VERSION ""

NS_ :

BS_:

BU_: VMCU TECU TACHO RECU_Virt IC3 HPCU EMS EBS DACU CIOM BBM ACM

BO_ 2566899694 PropTCO4_X_TACHO: 44 TACHO
 SG_ DailyRestingTimeShift1_ISig_3 : 144|15@1+ (1,0) [0|32767] "min"  IC3
 SG_ RestingPeriodFlagShift2_ISig_3 : 79|1@1+ (1,0) [0|0] ""  IC3
 SG_ DailyDrivingTimeShift4_ISig_3 : 96|15@1+ (1,0) [0|32767] "min"  IC3
 SG_ DailyDrivingPeriod_ISig_3 : 32|15@1+ (1,0) [0|32767] "min"  IC3
 SG_ DailyRestingTimeShift7_ISig_3 : 240|15@1+ (1,0) [0|32767] "min"  IC3
 SG_ UnknownPeriodShift1_ISig_3 : 159|1@1+ (1,0) [0|0] ""  IC3
 SG_ RestingPeriodFlagShift1_ISig_3 : 63|1@1+ (1,0) [0|0] ""  IC3
 SG_ DailyDrivingTimeShift3_ISig_3 : 80|15@1+ (1,0) [0|32767] "min"  IC3
 SG_ DailyRestingTimeShift2_ISig_3 : 160|15@1+ (1,0) [0|32767] "min"  IC3
 SG_ DailyRestingTimeShift3_ISig_3 : 176|15@1+ (1,0) [0|32767] "min"  IC3
 SG_ UnknownPeriodShift2_ISig_3 : 175|1@1+ (1,0) [0|0] ""  IC3
 SG_ RestingPeriodFlag_ISig_3 : 47|1@1+ (1,0) [0|0] ""  IC3
 SG_ TwoWeekTotalDrvingTime_ISig_3 : 0|16@1+ (1,0) [0|65535] "min"  IC3
 SG_ UnknownPeriodShift4_ISig_3 : 207|1@1+ (1,0) [0|0] ""  IC3
 SG_ DailyDrivingTimeShift2_ISig_3 : 64|15@1+ (1,0) [0|32767] "min"  IC3
 SG_ RestingPeriodFlagShift6_ISig_3 : 143|1@1+ (1,0) [0|0] ""  IC3
 SG_ DailyRestingTimeShift4_ISig_3 : 192|15@1+ (1,0) [0|32767] "min"  IC3
 SG_ RestingPeriodFlagShift5_ISig_3 : 127|1@1+ (1,0) [0|0] ""  IC3
 SG_ RestingPeriodFlagShift3_ISig_3 : 95|1@1+ (1,0) [0|0] ""  IC3
 SG_ DailyDrivingTimeShift5_ISig_3 : 112|15@1+ (1,0) [0|32767] "min"  IC3
 SG_ DailyRestingTimeShift6_ISig_3 : 224|15@1+ (1,0) [0|32767] "min"  IC3
 SG_ WeeklyTotalDrivingTime_ISig_3 : 16|16@1+ (1,0) [0|65535] "min"  IC3
 SG_ UnknownPeriodShift7_ISig_3 : 255|1@1+ (1,0) [0|0] ""  IC3
 SG_ UnknownPeriodShift6_ISig_3 : 239|1@1+ (1,0) [0|0] ""  IC3
 SG_ DailyRestingTimeShift5_ISig_3 : 208|15@1+ (1,0) [0|32767] "min"  IC3
 SG_ DailyDrivingTimeShift1_ISig_3 : 48|15@1+ (1,0) [0|32767] "min"  IC3
 SG_ UnknownPeriodShift3_ISig_3 : 191|1@1+ (1,0) [0|0] ""  IC3
 SG_ RestingPeriodFlagShift4_ISig_3 : 111|1@1+ (1,0) [0|0] ""  IC3
 SG_ DailyDrivingTimeShift6_ISig_3 : 128|15@1+ (1,0) [0|32767] "min"  IC3
 SG_ UnknownPeriodShift5_ISig_3 : 223|1@1+ (1,0) [0|0] ""  IC3

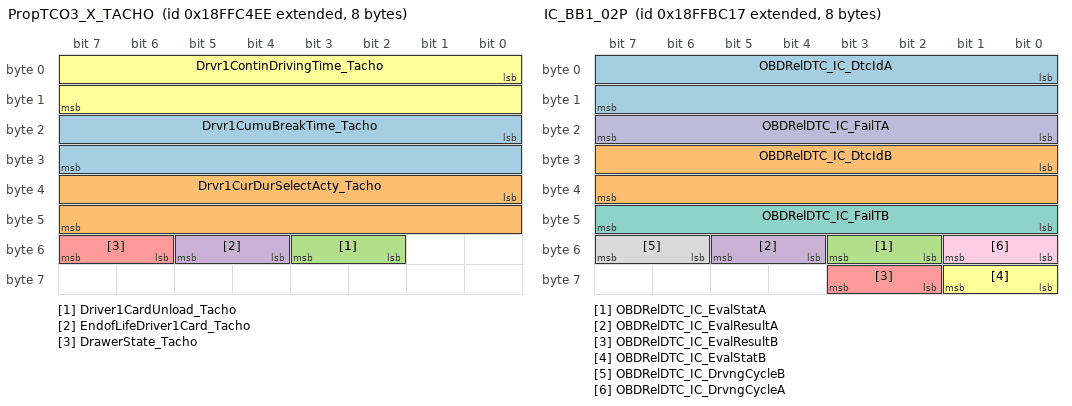
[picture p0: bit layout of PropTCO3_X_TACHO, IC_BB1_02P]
BO_ 2566898926 PropTCO3_X_TACHO: 8 TACHO
 SG_ Drvr1CumuBreakTime_Tacho : 16|16@1+ (1,0) [0|65535] "min"  VMCU
 SG_ Drvr1CurDurSelectActy_Tacho : 32|16@1+ (1,0) [0|65535] "min"  VMCU
 SG_ Driver1CardUnload_Tacho : 50|2@1+ (1,0) [0|0] ""  VMCU
 SG_ EndofLifeDriver1Card_Tacho : 52|2@1+ (1,0) [0|0] ""  VMCU
 SG_ DrawerState_Tacho : 54|2@1+ (1,0) [0|0] ""  VMCU
 SG_ Drvr1ContinDrivingTime_Tacho : 0|16@1+ (1,0) [0|65535] "min"  VMCU

BO_ 2566898670 PropTCO2_X_TACHO: 21 TACHO
 SG_ NextCalibrationDateDay : 136|8@1+ (0.25,0) [0|63.75] "Days"  VMCU
 SG_ WVehicleCharacteristicFactor : 152|16@1+ (0.001,0) [0|65.535] "NotApplicable"  VMCU
 SG_ NextCalibrationDateMonth : 128|8@1+ (1,0) [0|255] "Months"  VMCU
 SG_ Driver1Identification_ISig_3 : 0|112@1+ (1,0) [0|0] ""  IC3,CIOM
 SG_ NextCalibrationDateYear : 144|8@1+ (1,1985) [1985|2240] "Years"  VMCU

BO_ 2565804526 PropA_VMCU_TACHO: 8 TACHO
 SG_ DSRCtoOWSLink : 0|24@1+ (1,0) [0|0] ""  VMCU

BO_ 2565800709 PropA_TCU_GSSA: 8 Vector__XXX

BO_ 2565860881 PropA_TACHO_VMCU: 51 VMCU
 SG_ OWStoDSRCLink : 0|408@1+ (1,0) [0|0] ""  TACHO

BO_ 2565801219 PropA_GSSA_TCU: 8 Vector__XXX

BO_ 2671834641 PhysDiagRespMsg_F6_11_BB1: 8 ACM
 SG_ PhysDiagRespSig_F6_11_ISig_3 : 0|64@1+ (1,0) [0|0] ""  CIOM

BO_ 2671833838 PhysDiagRespMsg_F2_EE_BB1: 8 TACHO
 SG_ PhysDiagRespSig_F2_EE_ISig_3 : 0|64@1+ (1,0) [0|0] ""  VMCU

BO_ 2671833640 PhysDiagRespMsg_F2_28_BB1: 8 EBS
 SG_ PhysDiagRespSig_F2_28_ISig_3 : 0|64@1+ (1,0) [0|0] ""  VMCU

BO_ 2671833617 PhysDiagRespMsg_F2_11_BB1: 8 ACM
 SG_ PhysDiagRespSig_F2_11_ISig_3 : 0|64@1+ (1,0) [0|0] ""  VMCU

BO_ 2671833361 PhysDiagRespMsg_F1_11_BB1: 8 ACM
 SG_ PhysDiagRespSig_F1_11_ISig_3 : 0|64@1+ (1,0) [0|0] ""  VMCU

BO_ 2671832818 PhysDiagReqMsg_EE_F2_BB1: 8 VMCU
 SG_ PhysDiagReqSig_EE_F2_ISig_3 : 0|64@1+ (1,0) [0|0] ""  TACHO

BO_ 2671782130 PhysDiagReqMsg_28_F2_BB1: 8 VMCU
 SG_ PhysDiagReqSig_28_F2_ISig_3 : 0|64@1+ (1,0) [0|0] ""  EBS

BO_ 2671776246 PhysDiagReqMsg_11_F6_BB1: 8 CIOM
 SG_ PhysDiagReqSig_11_F6_ISig_3 : 0|64@1+ (1,0) [0|0] ""  ACM

BO_ 2671776242 PhysDiagReqMsg_11_F2_BB1: 8 VMCU
 SG_ PhysDiagReqSig_11_F2_ISig_3 : 0|64@1+ (1,0) [0|0] ""  ACM

BO_ 2671776241 PhysDiagReqMsg_11_F1_BB1: 8 VMCU
 SG_ PhysDiagReqSig_11_F1_ISig_3 : 0|64@1+ (1,0) [0|0] ""  ACM

BO_ 2566759457 PTODE_X_VMCU: 8 VMCU
 SG_ Pto2EnableSwitch : 4|2@1+ (1,0) [0|0] ""  TECU
 SG_ Pto1EnableSwitch : 6|2@1+ (1,0) [0|0] ""  TECU

BO_ 2566759427 PTODE_X_TECU: 8 TECU
 SG_ Pto2EngagementConsent : 20|2@1+ (1,0) [0|0] ""  VMCU
 SG_ Pto1EngagementConsent : 22|2@1+ (1,0) [0|0] ""  VMCU

BO_ 2671850481 OBDFuncDiagMsg_BB1: 8 VMCU
 SG_ FuncDiagDataOBD_ISig_3 : 0|64@1+ (1,0) [0|0] ""  ACM

BO_ 2671850486 OBDFuncDiagMsgF6_BB1: 8 CIOM
 SG_ FuncDiagDataOBDF6_ISig_3 : 0|64@1+ (1,0) [0|0] ""  ACM

BO_ 2566844928 LFE_X_EMS: 8 EMS
 SG_ InstantaneousFuelEconomy_ISig_3 : 16|16@1+ (0.001953125,0) [0|127.998046875] "km_per_l"  CIOM,IC3
 SG_ EngineFuelRate_ISig_3 : 0|16@1+ (0.05,0) [0|3276.75] "l_per_h"  BBM,VMCU,IC3,CIOM

BO_ 2566799590 LD_X_BBM_BB1: 8 BBM
 SG_ RearFogLights_ISig_3 : 32|2@1+ (1,0) [0|0] ""  DACU
 SG_ LowBeamHeadLightData_ISig_3 : 4|2@1+ (1,0) [0|0] ""  DACU

BO_ 2564428270 KWP2000Resp_VMCU_TACHO: 8 TACHO
 SG_ KWP2000Response_TACHO : 0|64@1+ (1,0) [0|0] ""  VMCU

BO_ 2564484625 KWP2000Req_TACHO_VMCU: 8 VMCU
 SG_ KWP2000Request_TACHO : 0|64@1+ (1,0) [0|0] ""  TACHO

BO_ 2633861635 J2012_X_TCU: 8 Vector__XXX

BO_ 2671902708 IntTesterTGW2FuncDiagMsg_BB1: 8 IC3
 SG_ FuncDiagDataIntTesterTGW2_ISig_3 : 0|64@1+ (1,0) [0|0] ""  TACHO,EBS,ACM

BO_ 2566825472 IMT1_X_EMS: 8 EMS
 SG_ EngineTurbo1BoostPressure : 0|16@1+ (0.125,0) [0|8191.875] "kPa"  IC3,ACM

BO_ 2566896663 IC_BB1_02P: 8 IC3
 SG_ OBDRelDTC_IC_DtcIdA : 0|16@1+ (1,0) [0|65535] ""  VMCU
 SG_ OBDRelDTC_IC_DtcIdB : 24|16@1+ (1,0) [0|65535] ""  VMCU
 SG_ OBDRelDTC_IC_EvalStatA : 50|2@1+ (1,0) [0|0] ""  VMCU
 SG_ OBDRelDTC_IC_EvalResultA : 52|2@1+ (1,0) [0|0] ""  VMCU
 SG_ OBDRelDTC_IC_EvalResultB : 58|2@1+ (1,0) [0|0] ""  VMCU
 SG_ OBDRelDTC_IC_EvalStatB : 56|2@1+ (1,0) [0|0] ""  VMCU
 SG_ OBDRelDTC_IC_FailTB : 40|8@1+ (1,0) [0|255] ""  VMCU
 SG_ OBDRelDTC_IC_DrvngCycleB : 54|2@1+ (1,0) [0|0] ""  VMCU
 SG_ OBDRelDTC_IC_DrvngCycleA : 48|2@1+ (1,0) [0|0] ""  VMCU
 SG_ OBDRelDTC_IC_FailTA : 16|8@1+ (1,0) [0|255] ""  VMCU

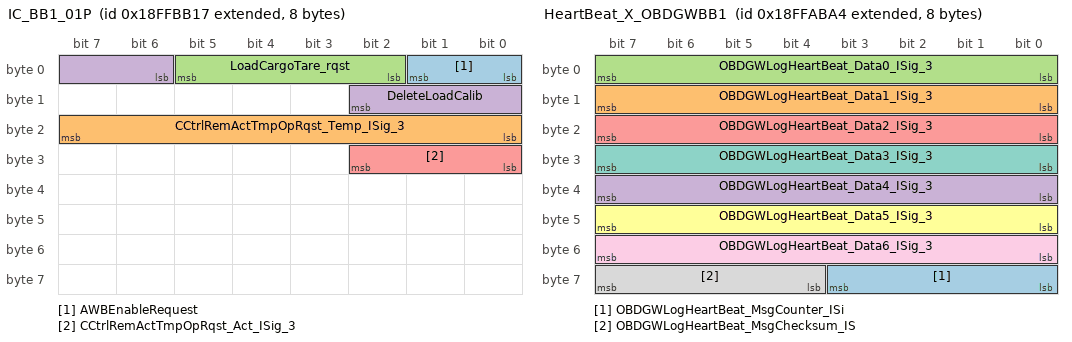
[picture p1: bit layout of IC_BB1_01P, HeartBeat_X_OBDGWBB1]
BO_ 2566896407 IC_BB1_01P: 8 IC3
 SG_ AWBEnableRequest : 0|2@1+ (1,0) [0|0] ""  TECU,EMS
 SG_ CCtrlRemActTmpOpRqst_Temp_ISig_3 : 16|8@1+ (0.5,0) [0|127.5] "DegreeC"  CIOM
 SG_ LoadCargoTare_rqst : 2|4@1+ (1,0) [0|0] ""  VMCU
 SG_ DeleteLoadCalib : 6|5@1+ (1,0) [0|0] ""  VMCU
 SG_ CCtrlRemActTmpOpRqst_Act_ISig_3 : 24|3@1+ (1,0) [0|0] ""  CIOM

BO_ 2566892452 HeartBeat_X_OBDGWBB1: 8 CIOM
 SG_ OBDGWLogHeartBeat_MsgCounter_ISi : 56|4@1+ (1,0) [0|15] "Count"  EMS
 SG_ OBDGWLogHeartBeat_Data1_ISig_3 : 8|8@1+ (1,0) [0|255] ""  EMS
 SG_ OBDGWLogHeartBeat_Data0_ISig_3 : 0|8@1+ (1,0) [0|255] ""  EMS
 SG_ OBDGWLogHeartBeat_Data4_ISig_3 : 32|8@1+ (1,0) [0|255] ""  EMS
 SG_ OBDGWLogHeartBeat_Data2_ISig_3 : 16|8@1+ (1,0) [0|255] ""  EMS
 SG_ OBDGWLogHeartBeat_Data5_ISig_3 : 40|8@1+ (1,0) [0|255] ""  EMS
 SG_ OBDGWLogHeartBeat_Data3_ISig_3 : 24|8@1+ (1,0) [0|255] ""  EMS
 SG_ OBDGWLogHeartBeat_MsgChecksum_IS : 60|4@1+ (1,0) [0|15] ""  EMS
 SG_ OBDGWLogHeartBeat_Data6_ISig_3 : 48|8@1+ (1,0) [0|255] ""  EMS

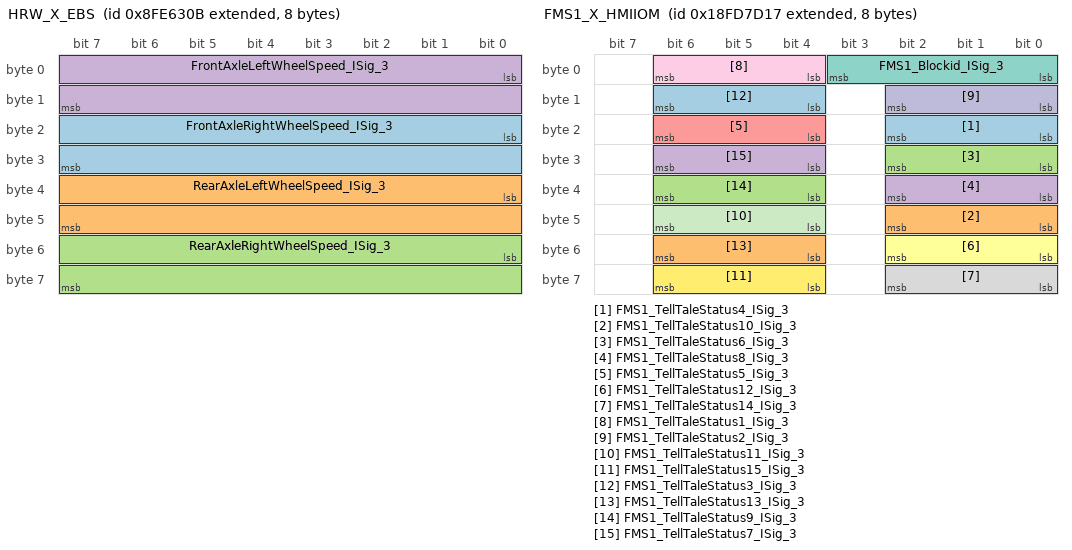
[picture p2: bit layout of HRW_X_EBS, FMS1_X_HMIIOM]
BO_ 2298372875 HRW_X_EBS: 8 EBS
 SG_ FrontAxleRightWheelSpeed_ISig_3 : 16|16@1+ (0.00390625,0) [0|255.99609375] "Km_per_h"  VMCU,BBM,DACU,TECU,IC3
 SG_ RearAxleLeftWheelSpeed_ISig_3 : 32|16@1+ (0.00390625,0) [0|255.99609375] "Km_per_h"  BBM,VMCU,TECU,DACU,IC3
 SG_ RearAxleRightWheelSpeed_ISig_3 : 48|16@1+ (0.00390625,0) [0|255.99609375] "Km_per_h"  BBM,VMCU,TECU,DACU,IC3
 SG_ FrontAxleLeftWheelSpeed_ISig_3 : 0|16@1+ (0.00390625,0) [0|255.99609375] "Km_per_h"  TECU,IC3,DACU,BBM,VMCU

BO_ 2566719744 HRLFC_X_EMS: 8 EMS
 SG_ HighResEngineTotalFuelUsed_ISig_ : 32|32@1+ (0.001,0) [0|4294967.295] "l"  IC3,BBM,CIOM

BO_ 2566841600 HOURS_X_EMS: 8 EMS
 SG_ EngineRevolutions_ISig_3 : 32|32@1+ (1000,0) [0|4294967295000] "r"  IC3

BO_ 2566749463 FMS1_X_HMIIOM: 8 IC3
 SG_ FMS1_TellTaleStatus4_ISig_3 : 16|3@1+ (1,0) [0|0] ""  CIOM
 SG_ FMS1_TellTaleStatus10_ISig_3 : 40|3@1+ (1,0) [0|0] ""  CIOM
 SG_ FMS1_TellTaleStatus6_ISig_3 : 24|3@1+ (1,0) [0|0] ""  CIOM
 SG_ FMS1_TellTaleStatus8_ISig_3 : 32|3@1+ (1,0) [0|0] ""  CIOM
 SG_ FMS1_TellTaleStatus5_ISig_3 : 20|3@1+ (1,0) [0|0] ""  CIOM
 SG_ FMS1_TellTaleStatus12_ISig_3 : 48|3@1+ (1,0) [0|0] ""  CIOM
 SG_ FMS1_Blockid_ISig_3 : 0|4@1+ (1,0) [0|15] ""  CIOM
 SG_ FMS1_TellTaleStatus14_ISig_3 : 56|3@1+ (1,0) [0|0] ""  CIOM
 SG_ FMS1_TellTaleStatus1_ISig_3 : 4|3@1+ (1,0) [0|0] ""  CIOM
 SG_ FMS1_TellTaleStatus2_ISig_3 : 8|3@1+ (1,0) [0|0] ""  CIOM
 SG_ FMS1_TellTaleStatus11_ISig_3 : 44|3@1+ (1,0) [0|0] ""  CIOM
 SG_ FMS1_TellTaleStatus15_ISig_3 : 60|3@1+ (1,0) [0|0] ""  CIOM
 SG_ FMS1_TellTaleStatus3_ISig_3 : 12|3@1+ (1,0) [0|0] ""  CIOM
 SG_ FMS1_TellTaleStatus13_ISig_3 : 52|3@1+ (1,0) [0|0] ""  CIOM
 SG_ FMS1_TellTaleStatus9_ISig_3 : 36|3@1+ (1,0) [0|0] ""  CIOM
 SG_ FMS1_TellTaleStatus7_ISig_3 : 28|3@1+ (1,0) [0|0] ""  CIOM

BO_ 2364541955 ETC8_X_TCU: 8 Vector__XXX

BO_ 2566801923 ETC7_X_TECU: 8 TECU
 SG_ TransmEngineCrankEnable2_ISig_3 : 12|2@1+ (1,0) [0|0] ""  VMCU

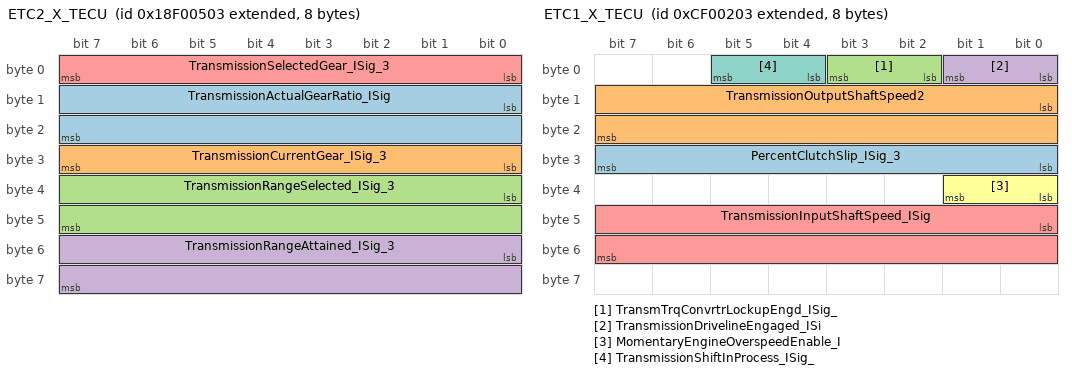
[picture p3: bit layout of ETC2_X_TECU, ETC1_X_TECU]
BO_ 2565866755 ETC2_X_TECU: 8 TECU
 SG_ TransmissionActualGearRatio_ISig : 8|16@1+ (0.001,0) [0|65.535] "NotApplicable"  BBM,DACU,EMS,VMCU
 SG_ TransmissionCurrentGear_ISig_3 : 24|8@1+ (1,-125) [-125|130] "GearValue"  EMS,BBM,VMCU,EBS,IC3,DACU
 SG_ TransmissionRangeSelected_ISig_3 : 32|16@1+ (1,0) [0|0] ""  VMCU,IC3,BBM
 SG_ TransmissionRangeAttained_ISig_3 : 48|16@1+ (1,0) [0|0] ""  BBM,IC3
 SG_ TransmissionSelectedGear_ISig_3 : 0|8@1+ (1,-125) [-125|130] "GearValue"  EMS,BBM,IC3,VMCU

BO_ 2364539395 ETC1_X_TECU: 8 TECU
 SG_ PercentClutchSlip_ISig_3 : 24|8@1+ (0.4,0) [0|102] "Percent"  EBS,EMS,VMCU,BBM
 SG_ TransmissionOutputShaftSpeed2 : 8|16@1+ (0.125,0) [0|8191.875] "rpm"  VMCU
 SG_ TransmTrqConvrtrLockupEngd_ISig_ : 2|2@1+ (1,0) [0|0] ""  VMCU,EMS,BBM
 SG_ TransmissionDrivelineEngaged_ISi : 0|2@1+ (1,0) [0|0] ""  EMS,VMCU,BBM,DACU,EBS
 SG_ TransmissionInputShaftSpeed_ISig : 40|16@1+ (0.125,0) [0|8191.875] "rpm"  BBM,EBS
 SG_ MomentaryEngineOverspeedEnable_I : 32|2@1+ (1,0) [0|0] ""  BBM,EMS
 SG_ TransmissionShiftInProcess_ISig_ : 4|2@1+ (1,0) [0|0] ""  EMS,VMCU,EBS,BBM,DACU

BO_ 2566843904 ET1_X_EMS: 8 EMS
 SG_ EngineOilTemperature_ISig_3 : 16|16@1+ (0.03125,-273) [-273|1774.96875] "DegreeC"  IC3,BBM,TECU
 SG_ EngineCoolantTemp_stat_ISig_3 : 0|8@1+ (1,-40) [-40|215] "DegreeC"  CIOM,IC3,VMCU,TECU,ACM,BBM

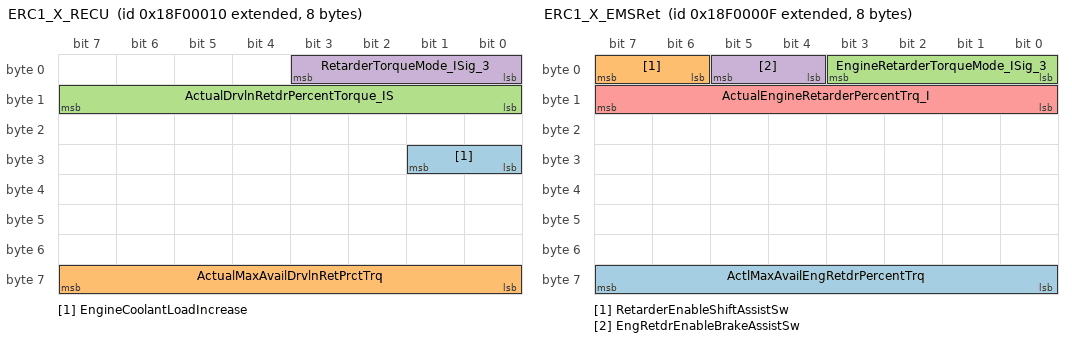
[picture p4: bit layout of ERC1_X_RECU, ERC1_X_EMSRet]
BO_ 2565865488 ERC1_X_RECU: 8 RECU_Virt
 SG_ EngineCoolantLoadIncrease : 24|2@1+ (1,0) [0|0] ""  EMS
 SG_ ActualMaxAvailDrvlnRetPrctTrq : 56|8@1+ (1,-125) [-125|130] "Percent"  EMS,EBS,VMCU,TECU
 SG_ ActualDrvlnRetdrPercentTorque_IS : 8|8@1+ (1,-125) [-125|130] "Percent"  EMS,CIOM,VMCU,TECU,EBS,IC3
 SG_ RetarderTorqueMode_ISig_3 : 0|4@1+ (1,0) [0|0] ""  CIOM,IC3,EMS

BO_ 2565865487 ERC1_X_EMSRet: 8 EMS
 SG_ ActlMaxAvailEngRetdrPercentTrq : 56|8@1+ (1,-125) [-125|130] "Percent"  VMCU,EBS
 SG_ RetarderEnableShiftAssistSw : 6|2@1+ (1,0) [0|0] ""  TECU
 SG_ EngineRetarderTorqueMode_ISig_3 : 0|4@1+ (1,0) [0|0] ""  CIOM,IC3
 SG_ EngRetdrEnableBrakeAssistSw : 4|2@1+ (1,0) [0|0] ""  TECU
 SG_ ActualEngineRetarderPercentTrq_I : 8|8@1+ (1,-125) [-125|130] "Percent"  RECU_Virt,CIOM,EBS,IC3,VMCU,TECU

BO_ 2364541440 EGF1_X_EMS: 8 EMS
 SG_ EngineIntakeAirRate : 16|16@1+ (0.05,0) [0|3276.75] "Kg_per_h"  CIOM

BO_ 2566844160 EFLP1_X_EMS: 8 EMS
 SG_ EngineOilLevel_ISig_3 : 16|8@1+ (0.4,0) [0|102] "Percent"  BBM,IC3
 SG_ EngineOilPressure_ISig_3 : 24|8@1+ (4,0) [0|1020] "kPa"  VMCU,IC3,BBM

BO_ 2566840064 EEC3_X_EMS: 8 EMS
 SG_ NominalFrictionPercentTorque_ISi : 0|8@1+ (1,-125) [-125|130] "Percent"  VMCU,TECU,DACU,CIOM,EBS,RECU_Virt

BO_ 2364539665 EEC2_X_VMCU: 8 VMCU
 SG_ AcceleratorPedalPositionVendor : 8|8@1+ (0.4,0) [0|102] "Percent"  TECU

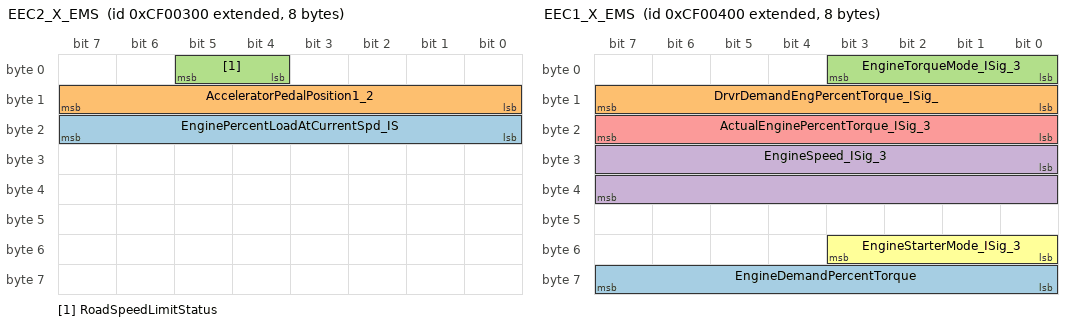
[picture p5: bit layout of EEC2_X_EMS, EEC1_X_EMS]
BO_ 2364539648 EEC2_X_EMS: 8 EMS
 SG_ EnginePercentLoadAtCurrentSpd_IS : 16|8@1+ (1,0) [0|255] "Percent"  ACM,IC3,BBM,CIOM,VMCU,TECU
 SG_ AcceleratorPedalPosition1_2 : 8|8@1+ (0.4,0) [0|102] "Percent"  TECU
 SG_ RoadSpeedLimitStatus : 4|2@1+ (1,0) [0|0] ""  TECU

BO_ 2364539904 EEC1_X_EMS: 8 EMS
 SG_ EngineDemandPercentTorque : 56|8@1+ (1,-125) [-125|130] "Percent"  TECU,CIOM
 SG_ DrvrDemandEngPercentTorque_ISig_ : 8|8@1+ (1,-125) [-125|130] "Percent"  BBM,TECU,EBS,VMCU
 SG_ EngineTorqueMode_ISig_3 : 0|4@1+ (1,0) [0|0] ""  TECU,VMCU,BBM,EBS,IC3
 SG_ EngineSpeed_ISig_3 : 24|16@1+ (0.125,0) [0|8191.875] "rpm"  BBM,DACU,IC3,VMCU,EBS,ACM,TECU,CIOM
 SG_ ActualEnginePercentTorque_ISig_3 : 16|8@1+ (1,-125) [-125|130] "Percent"  IC3,VMCU,EBS,CIOM,TECU,BBM,DACU
 SG_ EngineStarterMode_ISig_3 : 48|4@1+ (1,0) [0|0] ""  VMCU,BBM,IC3

BO_ 2566841088 EC1_X_EMS: 39 EMS
 SG_ EngConf_EngSpeedAtHighIdle_P6 : 120|16@1+ (0.125,0) [0|8191.875] "rpm"  TECU
 SG_ EngConf_EngTorqueAt_P4 : 88|8@1+ (1,-125) [-125|130] "Percent"  TECU
 SG_ EngConf_EngMaxMomOvSpeed_P7 : 168|16@1+ (0.125,0) [0|8191.875] "rpm"  TECU
 SG_ EngConf_EngTorqueAt_P5 : 112|8@1+ (1,-125) [-125|130] "Percent"  TECU
 SG_ EngConf_EngSpeedAtIdle_P1 : 0|16@1+ (0.125,0) [0|8191.875] "rpm"  TECU
 SG_ EngineReferenceTorque_ISig_3 : 152|16@1+ (1,0) [0|65535] "Nm"  TECU,CIOM,RECU_Virt,DACU,EBS,VMCU
 SG_ EngConf_EngSpeedAt_P2 : 24|16@1+ (0.125,0) [0|8191.875] "rpm"  TECU
 SG_ EngConf_MaxMomOverrideTimeLim : 184|8@1+ (0.1,0) [0|25.5] "s"  TECU
 SG_ EngConf_EngSpeedAt_P5 : 96|16@1+ (0.125,0) [0|8191.875] "rpm"  TECU
 SG_ EngConf_EngTorqueAtIdle_P1 : 16|8@1+ (1,-125) [-125|130] "Percent"  TECU
 SG_ EngConf_EngSpeedAt_P4 : 72|16@1+ (0.125,0) [0|8191.875] "rpm"  TECU
 SG_ EngConf_EngSpeedAt_P3 : 48|16@1+ (0.125,0) [0|8191.875] "rpm"  TECU
 SG_ EngConf_EngTorqueAt_P3 : 64|8@1+ (1,-125) [-125|130] "Percent"  TECU
 SG_ EngConf_EngTorqueAt_P2 : 40|8@1+ (1,-125) [-125|130] "Percent"  TECU

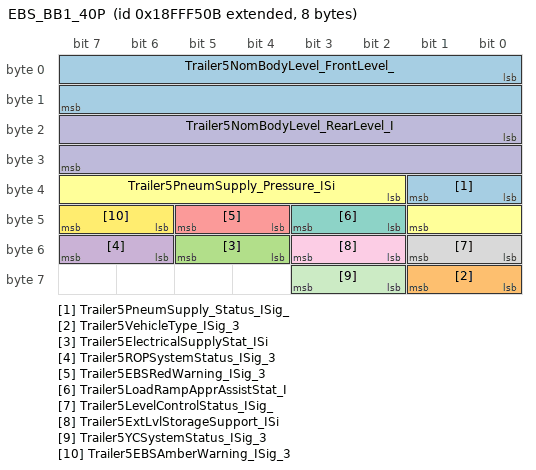
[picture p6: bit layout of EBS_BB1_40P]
BO_ 2566911243 EBS_BB1_40P: 8 EBS
 SG_ Trailer5PneumSupply_Status_ISig_ : 32|2@1+ (1,0) [0|0] ""  IC3
 SG_ Trailer5VehicleType_ISig_3 : 56|2@1+ (1,0) [0|0] ""  IC3
 SG_ Trailer5ElectricalSupplyStat_ISi : 52|2@1+ (1,0) [0|0] ""  IC3
 SG_ Trailer5ROPSystemStatus_ISig_3 : 54|2@1+ (1,0) [0|0] ""  IC3
 SG_ Trailer5EBSRedWarning_ISig_3 : 44|2@1+ (1,0) [0|0] ""  IC3
 SG_ Trailer5PneumSupply_Pressure_ISi : 34|8@1+ (5,0) [0|1275] "kPa"  IC3
 SG_ Trailer5LoadRampApprAssistStat_I : 42|2@1+ (1,0) [0|0] ""  IC3
 SG_ Trailer5LevelControlStatus_ISig_ : 48|2@1+ (1,0) [0|0] ""  IC3
 SG_ Trailer5ExtLvlStorageSupport_ISi : 50|2@1+ (1,0) [0|0] ""  IC3
 SG_ Trailer5NomBodyLevel_RearLevel_I : 16|16@1+ (1,0) [0|65535] "mm"  IC3
 SG_ Trailer5YCSystemStatus_ISig_3 : 58|2@1+ (1,0) [0|0] ""  IC3
 SG_ Trailer5EBSAmberWarning_ISig_3 : 46|2@1+ (1,0) [0|0] ""  IC3
 SG_ Trailer5NomBodyLevel_FrontLevel_ : 0|16@1+ (1,0) [0|65535] "mm"  IC3

CM_ BO_ 2566899694 "Proprietary TACHO message 4";
CM_ SG_ 2566899694 TwoWeekTotalDrvingTime_ISig_3 "65024 - 65279 Error ; 65280 - 65535 Not available";
CM_ SG_ 2566899694 WeeklyTotalDrivingTime_ISig_3 "65024 - 65279 Error ; 65280 - 65535 Not available";
CM_ BO_ 2566898926 "Proprietary TACHO message 3";
CM_ SG_ 2566898926 Drvr1CumuBreakTime_Tacho "65024 - 65279 Error ; 65280 - 65535 Not available";
CM_ SG_ 2566898926 Drvr1CurDurSelectActy_Tacho "65024 - 65279 Error ; 65280 - 65535 Not available";
CM_ SG_ 2566898926 Drvr1ContinDrivingTime_Tacho "65024 - 65279 Error ; 65280 - 65535 Not available";
CM_ BO_ 2566898670 "Proprietary TACHO message 2";
CM_ SG_ 2566898670 NextCalibrationDateDay "254 Error ; 255 Not available";
CM_ SG_ 2566898670 NextCalibrationDateMonth "254 Error ; 255 Not available";
CM_ SG_ 2566898670 NextCalibrationDateYear "254 Error ; 255 Not available";
CM_ BO_ 2565800709 "PGN61184 Proprietary A data sent by Transmission ECU to Gearshift selector";
CM_ BO_ 2565801219 "PGN61184 Proprietary A data sent by Gearshift selector to Transmission ECU";
CM_ BO_ 2566759457 "PGN 64932 PTO Drive Engagement";
CM_ BO_ 2566759427 "PGN 64932 PTO Drive Engagement
";
CM_ BO_ 2566844928 "PGN 65266 Fuel Economy (Liquid)";
CM_ SG_ 2566844928 InstantaneousFuelEconomy_ISig_3 "64256 - 65023 Spare
65024 - 65279 Error
65280 - 65535 NotAvailable";
CM_ SG_ 2566844928 EngineFuelRate_ISig_3 "65024 - 65279 Error ; 65280 - 65535 Not available";
CM_ BO_ 2633861635 "PGN 64906 SAE J2012 DTC Display";
CM_ BO_ 2566825472 "PGN 65190 Intake Manifold Information 1";
CM_ SG_ 2566825472 EngineTurbo1BoostPressure "65024 - 65279 Error ; 65280 - 65535 Not Available";
CM_ BO_ 2566892452 "Defined as sporadic on BB1, but is in reality sent cyclic 30 seconds when OBDGW is present and send msg cyclic on DiagLink.";
CM_ BO_ 2298372875 "PGN 65134 High Resolution Wheel Speed";
CM_ SG_ 2298372875 FrontAxleRightWheelSpeed_ISig_3 "65024 - 65279 Error ; 65280 - 65535 Not available";
CM_ SG_ 2298372875 RearAxleLeftWheelSpeed_ISig_3 "65024 - 65279 Error ; 65280 - 65535 Not available";
CM_ SG_ 2298372875 RearAxleRightWheelSpeed_ISig_3 "65024 - 65279 Error ; 65280 - 65535 Not available";
CM_ SG_ 2298372875 FrontAxleLeftWheelSpeed_ISig_3 "65024 - 65279 Error ; 65280 - 65535 Not available";
CM_ BO_ 2566719744 "PGN 64777 High Resolution Fuel Consumption (Liquid)";
CM_ SG_ 2566719744 HighResEngineTotalFuelUsed_ISig_ "4211081216 - 4261412863 Spare
4261412864 - 4278190079 Error
4278190080 - 4294967295 NotAvailable";
CM_ BO_ 2566841600 "PGN 65253 Engine Hours, Revolutions";
CM_ SG_ 2566841600 EngineRevolutions_ISig_3 "4261412864 - 4278190079 Error ; 4278190080 - 4294967295 Not available";
CM_ BO_ 2566749463 "PGN 64893 FMS Telltale status";
CM_ SG_ 2566749463 FMS1_Blockid_ISig_3 "15: Don't care";
CM_ BO_ 2364541955 "PGN61452 Electronic Transmission Controller #8";
CM_ BO_ 2566801923 "PGN 65098 Electronic Transmission Controller 7";
CM_ BO_ 2565866755 "PGN 61445 Electronic Transmission Controller 2";
CM_ SG_ 2565866755 TransmissionActualGearRatio_ISig "65024 - 65279 Error ; 65280 - 65535 Not available";
CM_ SG_ 2565866755 TransmissionCurrentGear_ISig_3 "254 Error ; 255 Not available";
CM_ SG_ 2565866755 TransmissionSelectedGear_ISig_3 "254 Error ; 255 Not available";
CM_ BO_ 2364539395 "PGN 61442 Electronic Transmission Controller 1";
CM_ SG_ 2364539395 PercentClutchSlip_ISig_3 "254 Error ; 255 Not available";
CM_ SG_ 2364539395 TransmissionInputShaftSpeed_ISig "65024 - 65279 Error ; 65280 - 65535 Not available";
CM_ BO_ 2566843904 "PGN 65262 Engine Temperature 1";
CM_ SG_ 2566843904 EngineOilTemperature_ISig_3 "65024 - 65279 Error ; 65280 - 65535 Not available";
CM_ SG_ 2566843904 EngineCoolantTemp_stat_ISig_3 "254 Error ; 255 Not available";
CM_ BO_ 2565865488 "PGN 61440 Electronic Retarder Controller 1 from RECU";
CM_ SG_ 2565865488 ActualMaxAvailDrvlnRetPrctTrq "254 Error ; 255 Not available";
CM_ SG_ 2565865488 ActualDrvlnRetdrPercentTorque_IS "254 Error ; 255 Not available";
CM_ BO_ 2565865487 "PGN 61440 Electronic Retarder Controller 1";
CM_ SG_ 2565865487 ActlMaxAvailEngRetdrPercentTrq "254 Error ; 255 Not available";
CM_ SG_ 2565865487 ActualEngineRetarderPercentTrq_I "254 Error ; 255 Not available";
CM_ BO_ 2364541440 "PGN 61450 Flow rates of Air and mixed gasses into the engine cylinders.
Note: SAE recommended rate 50ms, but 500ms set due to current usage only for logging.";
CM_ BO_ 2566844160 "PGN 65263 Engine Fluid Level/Pressure 1";
CM_ SG_ 2566844160 EngineOilLevel_ISig_3 "254 Error ; 255 Not available";
CM_ SG_ 2566844160 EngineOilPressure_ISig_3 "254 Error ; 255 Not available";
CM_ BO_ 2566840064 "PGN 65247 Electronic Engine Controller 3";
CM_ SG_ 2566840064 NominalFrictionPercentTorque_ISi "254 Error ; 255 Not available";
CM_ BO_ 2364539665 "PGN 61443 Electronic Engine Controller 2";
CM_ BO_ 2364539648 "PGN 61443 Electronic Engine Controller 2";
CM_ SG_ 2364539648 EnginePercentLoadAtCurrentSpd_IS "254 Error ; 255 Not available";
CM_ BO_ 2364539904 "PGN 61444 Electronic Engine Controller 1";
CM_ SG_ 2364539904 DrvrDemandEngPercentTorque_ISig_ "254 Error ; 255 Not available";
CM_ SG_ 2364539904 EngineSpeed_ISig_3 "65024 - 65279 Error ; 65280 - 65535 Not available";
CM_ SG_ 2364539904 ActualEnginePercentTorque_ISig_3 "254 Error ; 255 Not available";
CM_ BO_ 2566841088 "PGN 65251 Engine Configuration 1";
CM_ SG_ 2566841088 EngConf_EngSpeedAtHighIdle_P6 "65024 - 65279 Error ; 65280 - 65535 Not available";
CM_ SG_ 2566841088 EngConf_EngTorqueAt_P4 "254 Error ; 255 Not available";
CM_ SG_ 2566841088 EngConf_EngMaxMomOvSpeed_P7 "65024 - 65279 Error ; 65280 - 65535 Not available";
CM_ SG_ 2566841088 EngConf_EngTorqueAt_P5 "254 Error ; 255 Not available";
CM_ SG_ 2566841088 EngConf_EngSpeedAtIdle_P1 "65024 - 65279 Error ; 65280 - 65535 Not available";
CM_ SG_ 2566841088 EngineReferenceTorque_ISig_3 "65024 - 65279 Error ; 65280 - 65535 Not available";
CM_ SG_ 2566841088 EngConf_EngSpeedAt_P2 "65024 - 65279 Error ; 65280 - 65535 Not available";
CM_ SG_ 2566841088 EngConf_MaxMomOverrideTimeLim "254 Error ; 255 Not available";
CM_ SG_ 2566841088 EngConf_EngSpeedAt_P5 "65024 - 65279 Error ; 65280 - 65535 Not available";
CM_ SG_ 2566841088 EngConf_EngTorqueAtIdle_P1 "254 Error ; 255 Not available";
CM_ SG_ 2566841088 EngConf_EngSpeedAt_P4 "65024 - 65279 Error ; 65280 - 65535 Not available";
CM_ SG_ 2566841088 EngConf_EngSpeedAt_P3 "65024 - 65279 Error ; 65280 - 65535 Not available";
CM_ SG_ 2566841088 EngConf_EngTorqueAt_P3 "254 Error ; 255 Not available";
CM_ SG_ 2566841088 EngConf_EngTorqueAt_P2 "254 Error ; 255 Not available";
CM_ SG_ 2566911243 Trailer5PneumSupply_Pressure_ISi "254 Error ; 255 Not available";
BA_DEF_ BO_  "GenMsgStartDelayTime" INT 0 0;
BA_DEF_ BO_  "GenMsgDelayTime" INT 0 0;
BA_DEF_ BO_  "GenMsgNrOfRepetition" INT 0 0;
BA_DEF_ BO_  "GenMsgCycleTimeFast" INT 0 0;
BA_DEF_ BO_  "GenMsgCycleTime" INT 0 0;
BA_DEF_ BO_  "GenMsgSendType" ENUM  "Cyclic","NotUsed","NotUsed","NotUsed","NotUsed","NotUsed","NotUsed","IfActive","NoMsgSendType","NotUsed";
BA_DEF_ SG_  "GenSigStartValue" INT 0 0;
BA_DEF_ SG_  "GenSigCycleTimeActive" INT 0 0;
BA_DEF_ SG_  "GenSigCycleTime" INT 0 0;
BA_DEF_ SG_  "GenSigSendType" ENUM  "Cyclic","OnWrite","OnWriteWithRepetition","OnChange","OnChangeWithRepetition","IfActive","IfActiveWithRepetition","NoSigSendType","NotUsed","NotUsed","NotUsed","NotUsed","NotUsed";
BA_DEF_ BO_  "VFrameFormat" ENUM  "StandardCAN","ExtendedCAN","reserved","J1939PG","reserved","reserved","reserved","reserved","reserved","reserved","reserved","reserved","reserved","reserved","StandardCAN_FD","ExtendedCAN_FD";
BA_DEF_ BO_  "TpJ1939VarDlc" ENUM  "No","Yes";
BA_DEF_ SG_  "SigType" ENUM  "Default","Range","RangeSigned","ASCII","Discrete","Control","ReferencePGN","DTC","StringDelimiter","StringLength","StringLengthControl";
BA_DEF_ SG_  "SeToolVersion_SIGNAL" STRING ;
BA_DEF_ SG_  "SeToolUniqueID_SIGNAL" STRING ;
BA_DEF_ SG_  "SeToolOwnerSigGroup_SIGNAL" STRING ;
BA_DEF_ SG_  "SeToolOwnerSigGroupID_SIGNAL" STRING ;
BA_DEF_ SG_  "SeToolName_SIGNAL" STRING ;
BA_DEF_ SG_  "SeToolItemID_SIGNAL" STRING ;
BA_DEF_ SG_  "SeToolAncestorID_SIGNAL" STRING ;
BA_DEF_ SG_  "SPN" INT 0 524287;
BA_DEF_ SG_  "Platform_VMCU1_Sig" ENUM  "No","Yes";
BA_DEF_ SG_  "Platform_FactoryIf_Sig" ENUM  "No","Yes";
BA_DEF_ SG_  "NeedsUpdateBit" ENUM  "No","Yes";
BA_DEF_ SG_  "GenSigMaxLatency" INT 0 65535;
BA_DEF_ SG_  "GenSigILSupport" ENUM  "Yes","No";
BA_DEF_ BO_  "GenMsgILSupport" ENUM  "No","Yes";
BA_DEF_ BO_  "DiagUUDTResponse" ENUM  "No","Yes";
BA_DEF_ BO_  "DiagState" ENUM  "No","Yes";
BA_DEF_ BO_  "DiagResponse" ENUM  "No","Yes";
BA_DEF_ BO_  "DiagRequest" ENUM  "No","Yes";
BA_DEF_ BO_  "DiagConnection" HEX 0 65535;
BA_DEF_ BO_  "CanTpFcFrameId" HEX 0 2147483647;
BA_DEF_ BO_  "CanTpBs" INT 0 255;
BA_DEF_ SG_  "SystemSignalLongSymbol" STRING ;
BA_DEF_REL_ BU_SG_REL_  "GenSigTimeoutTime" INT 0 65535;
BA_DEF_REL_ BU_SG_REL_  "GenSigFirstTimeoutTime" INT 0 65535;
BA_DEF_DEF_  "GenMsgStartDelayTime" 0;
BA_DEF_DEF_  "GenMsgDelayTime" 0;
BA_DEF_DEF_  "GenMsgNrOfRepetition" 0;
BA_DEF_DEF_  "GenMsgCycleTimeFast" 0;
BA_DEF_DEF_  "GenMsgCycleTime" 0;
BA_DEF_DEF_  "GenMsgSendType" "Cyclic";
BA_DEF_DEF_  "GenSigStartValue" 0;
BA_DEF_DEF_  "GenSigCycleTimeActive" 0;
BA_DEF_DEF_  "GenSigCycleTime" 0;
BA_DEF_DEF_  "GenSigSendType" "Cyclic";
BA_DEF_DEF_  "VFrameFormat" "ExtendedCAN";
BA_DEF_DEF_  "TpJ1939VarDlc" "No";
BA_DEF_DEF_  "SigType" "Default";
BA_DEF_DEF_  "SeToolVersion_SIGNAL" "";
BA_DEF_DEF_  "SeToolUniqueID_SIGNAL" "";
BA_DEF_DEF_  "SeToolOwnerSigGroup_SIGNAL" "";
BA_DEF_DEF_  "SeToolOwnerSigGroupID_SIGNAL" "";
BA_DEF_DEF_  "SeToolName_SIGNAL" "";
BA_DEF_DEF_  "SeToolItemID_SIGNAL" "";
BA_DEF_DEF_  "SeToolAncestorID_SIGNAL" "";
BA_DEF_DEF_  "SPN" 0;
BA_DEF_DEF_  "Platform_VMCU1_Sig" "No";
BA_DEF_DEF_  "Platform_FactoryIf_Sig" "No";
BA_DEF_DEF_  "NeedsUpdateBit" "No";
BA_DEF_DEF_  "GenSigMaxLatency" 0;
BA_DEF_DEF_  "GenSigILSupport" "Yes";
BA_DEF_DEF_  "GenMsgILSupport" "Yes";
BA_DEF_DEF_  "DiagUUDTResponse" "No";
BA_DEF_DEF_  "DiagState" "No";
BA_DEF_DEF_  "DiagResponse" "No";
BA_DEF_DEF_  "DiagRequest" "No";
BA_DEF_DEF_  "DiagConnection" 0;
BA_DEF_DEF_  "CanTpFcFrameId" 2147483647;
BA_DEF_DEF_  "CanTpBs" 255;
BA_DEF_DEF_REL_ "GenSigTimeoutTime" 0;
BA_DEF_DEF_REL_ "GenSigFirstTimeoutTime" 0;
BA_DEF_DEF_  "SystemSignalLongSymbol" "";
BA_ "GenMsgCycleTime" BO_ 2566899694 60000;
BA_ "GenMsgDelayTime" BO_ 2566899694 995;
BA_ "VFrameFormat" BO_ 2566899694 3;
BA_ "GenMsgCycleTime" BO_ 2566898926 10000;
BA_ "GenMsgDelayTime" BO_ 2566898926 995;
BA_ "VFrameFormat" BO_ 2566898926 3;
BA_ "GenMsgCycleTime" BO_ 2566898670 60000;
BA_ "GenMsgDelayTime" BO_ 2566898670 995;
BA_ "VFrameFormat" BO_ 2566898670 3;
BA_ "GenMsgSendType" BO_ 2565804526 8;
BA_ "VFrameFormat" BO_ 2565804526 3;
BA_ "VFrameFormat" BO_ 2565800709 3;
BA_ "TpJ1939VarDlc" BO_ 2565860881 1;
BA_ "GenMsgSendType" BO_ 2565860881 8;
BA_ "VFrameFormat" BO_ 2565860881 3;
BA_ "VFrameFormat" BO_ 2565801219 3;
BA_ "DiagConnection" BO_ 2671834641 62993;
BA_ "DiagResponse" BO_ 2671834641 1;
BA_ "GenMsgILSupport" BO_ 2671834641 0;
BA_ "GenMsgSendType" BO_ 2671834641 8;
BA_ "VFrameFormat" BO_ 2671834641 3;
BA_ "DiagConnection" BO_ 2671833838 62190;
BA_ "DiagResponse" BO_ 2671833838 1;
BA_ "GenMsgILSupport" BO_ 2671833838 0;
BA_ "GenMsgSendType" BO_ 2671833838 8;
BA_ "VFrameFormat" BO_ 2671833838 3;
BA_ "DiagConnection" BO_ 2671833640 61992;
BA_ "DiagResponse" BO_ 2671833640 1;
BA_ "GenMsgILSupport" BO_ 2671833640 0;
BA_ "GenMsgSendType" BO_ 2671833640 8;
BA_ "VFrameFormat" BO_ 2671833640 3;
BA_ "DiagConnection" BO_ 2671833617 61969;
BA_ "DiagResponse" BO_ 2671833617 1;
BA_ "GenMsgILSupport" BO_ 2671833617 0;
BA_ "GenMsgSendType" BO_ 2671833617 8;
BA_ "VFrameFormat" BO_ 2671833617 3;
BA_ "DiagConnection" BO_ 2671833361 61713;
BA_ "DiagResponse" BO_ 2671833361 1;
BA_ "GenMsgILSupport" BO_ 2671833361 0;
BA_ "GenMsgSendType" BO_ 2671833361 8;
BA_ "VFrameFormat" BO_ 2671833361 3;
BA_ "DiagConnection" BO_ 2671832818 62190;
BA_ "DiagRequest" BO_ 2671832818 1;
BA_ "GenMsgILSupport" BO_ 2671832818 0;
BA_ "GenMsgSendType" BO_ 2671832818 8;
BA_ "VFrameFormat" BO_ 2671832818 3;
BA_ "DiagConnection" BO_ 2671782130 61992;
BA_ "DiagRequest" BO_ 2671782130 1;
BA_ "GenMsgILSupport" BO_ 2671782130 0;
BA_ "GenMsgSendType" BO_ 2671782130 8;
BA_ "VFrameFormat" BO_ 2671782130 3;
BA_ "DiagConnection" BO_ 2671776246 62993;
BA_ "DiagRequest" BO_ 2671776246 1;
BA_ "GenMsgILSupport" BO_ 2671776246 0;
BA_ "GenMsgSendType" BO_ 2671776246 8;
BA_ "VFrameFormat" BO_ 2671776246 3;
BA_ "DiagConnection" BO_ 2671776242 61969;
BA_ "DiagRequest" BO_ 2671776242 1;
BA_ "GenMsgILSupport" BO_ 2671776242 0;
BA_ "GenMsgSendType" BO_ 2671776242 8;
BA_ "VFrameFormat" BO_ 2671776242 3;
BA_ "DiagConnection" BO_ 2671776241 61713;
BA_ "DiagRequest" BO_ 2671776241 1;
BA_ "GenMsgILSupport" BO_ 2671776241 0;
BA_ "GenMsgSendType" BO_ 2671776241 8;
BA_ "VFrameFormat" BO_ 2671776241 3;
BA_ "GenMsgCycleTime" BO_ 2566759457 100;
BA_ "VFrameFormat" BO_ 2566759457 3;
BA_ "GenMsgCycleTime" BO_ 2566759427 100;
BA_ "GenMsgStartDelayTime" BO_ 2566759427 55;
BA_ "VFrameFormat" BO_ 2566759427 3;
BA_ "DiagConnection" BO_ 2671850481 61713;
BA_ "DiagState" BO_ 2671850481 1;
BA_ "GenMsgILSupport" BO_ 2671850481 0;
BA_ "GenMsgSendType" BO_ 2671850481 8;
BA_ "VFrameFormat" BO_ 2671850481 3;
BA_ "DiagConnection" BO_ 2671850486 62993;
BA_ "DiagState" BO_ 2671850486 1;
BA_ "GenMsgILSupport" BO_ 2671850486 0;
BA_ "GenMsgSendType" BO_ 2671850486 8;
BA_ "VFrameFormat" BO_ 2671850486 3;
BA_ "GenMsgCycleTime" BO_ 2566844928 100;
BA_ "GenMsgStartDelayTime" BO_ 2566844928 15;
BA_ "VFrameFormat" BO_ 2566844928 3;
BA_ "GenMsgCycleTime" BO_ 2566799590 100;
BA_ "GenMsgStartDelayTime" BO_ 2566799590 10;
BA_ "VFrameFormat" BO_ 2566799590 3;
BA_ "GenMsgSendType" BO_ 2564428270 8;
BA_ "VFrameFormat" BO_ 2564428270 3;
BA_ "GenMsgSendType" BO_ 2564484625 8;
BA_ "VFrameFormat" BO_ 2564484625 3;
BA_ "TpJ1939VarDlc" BO_ 2633861635 1;
BA_ "VFrameFormat" BO_ 2633861635 3;
BA_ "DiagConnection" BO_ 2671902708 62467;
BA_ "DiagState" BO_ 2671902708 1;
BA_ "GenMsgILSupport" BO_ 2671902708 0;
BA_ "GenMsgSendType" BO_ 2671902708 8;
BA_ "VFrameFormat" BO_ 2671902708 3;
BA_ "GenMsgCycleTime" BO_ 2566825472 500;
BA_ "VFrameFormat" BO_ 2566825472 3;
BA_ "GenMsgCycleTime" BO_ 2566896663 500;
BA_ "VFrameFormat" BO_ 2566896663 3;
BA_ "GenMsgCycleTime" BO_ 2566896407 500;
BA_ "GenMsgStartDelayTime" BO_ 2566896407 50;
BA_ "VFrameFormat" BO_ 2566896407 3;
BA_ "GenMsgSendType" BO_ 2566892452 8;
BA_ "GenMsgDelayTime" BO_ 2566892452 100;
BA_ "VFrameFormat" BO_ 2566892452 3;
BA_ "GenMsgCycleTime" BO_ 2298372875 20;
BA_ "VFrameFormat" BO_ 2298372875 3;
BA_ "GenMsgCycleTime" BO_ 2566719744 1000;
BA_ "VFrameFormat" BO_ 2566719744 3;
BA_ "GenMsgCycleTime" BO_ 2566841600 5000;
BA_ "GenMsgStartDelayTime" BO_ 2566841600 1345;
BA_ "VFrameFormat" BO_ 2566841600 3;
BA_ "GenMsgCycleTime" BO_ 2566749463 1000;
BA_ "GenMsgStartDelayTime" BO_ 2566749463 10;
BA_ "VFrameFormat" BO_ 2566749463 3;
BA_ "VFrameFormat" BO_ 2364541955 3;
BA_ "GenMsgCycleTime" BO_ 2566801923 100;
BA_ "GenMsgStartDelayTime" BO_ 2566801923 20;
BA_ "VFrameFormat" BO_ 2566801923 3;
BA_ "GenMsgCycleTime" BO_ 2565866755 100;
BA_ "GenMsgStartDelayTime" BO_ 2565866755 15;
BA_ "VFrameFormat" BO_ 2565866755 3;
BA_ "GenMsgCycleTime" BO_ 2364539395 10;
BA_ "VFrameFormat" BO_ 2364539395 3;
BA_ "GenMsgCycleTime" BO_ 2566843904 1000;
BA_ "GenMsgStartDelayTime" BO_ 2566843904 430;
BA_ "VFrameFormat" BO_ 2566843904 3;
BA_ "GenMsgCycleTime" BO_ 2565865488 100;
BA_ "VFrameFormat" BO_ 2565865488 3;
BA_ "GenMsgCycleTime" BO_ 2565865487 100;
BA_ "GenMsgStartDelayTime" BO_ 2565865487 10;
BA_ "VFrameFormat" BO_ 2565865487 3;
BA_ "GenMsgCycleTime" BO_ 2364541440 500;
BA_ "GenMsgStartDelayTime" BO_ 2364541440 25;
BA_ "VFrameFormat" BO_ 2364541440 3;
BA_ "GenMsgCycleTime" BO_ 2566844160 500;
BA_ "GenMsgStartDelayTime" BO_ 2566844160 125;
BA_ "VFrameFormat" BO_ 2566844160 3;
BA_ "GenMsgCycleTime" BO_ 2566840064 250;
BA_ "GenMsgStartDelayTime" BO_ 2566840064 20;
BA_ "VFrameFormat" BO_ 2566840064 3;
BA_ "GenMsgCycleTime" BO_ 2364539665 50;
BA_ "VFrameFormat" BO_ 2364539665 3;
BA_ "GenMsgCycleTime" BO_ 2364539648 50;
BA_ "VFrameFormat" BO_ 2364539648 3;
BA_ "GenMsgCycleTime" BO_ 2364539904 20;
BA_ "GenMsgStartDelayTime" BO_ 2364539904 5;
BA_ "VFrameFormat" BO_ 2364539904 3;
BA_ "GenMsgCycleTime" BO_ 2566841088 5000;
BA_ "GenMsgDelayTime" BO_ 2566841088 200;
BA_ "GenMsgStartDelayTime" BO_ 2566841088 140;
BA_ "VFrameFormat" BO_ 2566841088 3;
BA_ "GenMsgCycleTime" BO_ 2566911243 1000;
BA_ "GenMsgStartDelayTime" BO_ 2566911243 410;
BA_ "VFrameFormat" BO_ 2566911243 3;
BA_ "GenSigSendType" SG_ 2566899694 DailyRestingTimeShift1_ISig_3 1;
BA_ "GenSigStartValue" SG_ 2566899694 DailyRestingTimeShift1_ISig_3 32767;
BA_ "Platform_VMCU1_Sig" SG_ 2566899694 DailyRestingTimeShift1_ISig_3 1;
BA_ "GenSigSendType" SG_ 2566899694 RestingPeriodFlagShift2_ISig_3 1;
BA_ "Platform_VMCU1_Sig" SG_ 2566899694 RestingPeriodFlagShift2_ISig_3 1;
BA_ "GenSigSendType" SG_ 2566899694 DailyDrivingTimeShift4_ISig_3 1;
BA_ "GenSigStartValue" SG_ 2566899694 DailyDrivingTimeShift4_ISig_3 32767;
BA_ "Platform_VMCU1_Sig" SG_ 2566899694 DailyDrivingTimeShift4_ISig_3 1;
BA_ "GenSigSendType" SG_ 2566899694 DailyDrivingPeriod_ISig_3 1;
BA_ "GenSigStartValue" SG_ 2566899694 DailyDrivingPeriod_ISig_3 32767;
BA_ "Platform_VMCU1_Sig" SG_ 2566899694 DailyDrivingPeriod_ISig_3 1;
BA_ "GenSigSendType" SG_ 2566899694 DailyRestingTimeShift7_ISig_3 1;
BA_ "GenSigStartValue" SG_ 2566899694 DailyRestingTimeShift7_ISig_3 32767;
BA_ "Platform_VMCU1_Sig" SG_ 2566899694 DailyRestingTimeShift7_ISig_3 1;
BA_ "GenSigSendType" SG_ 2566899694 UnknownPeriodShift1_ISig_3 1;
BA_ "Platform_VMCU1_Sig" SG_ 2566899694 UnknownPeriodShift1_ISig_3 1;
BA_ "GenSigSendType" SG_ 2566899694 RestingPeriodFlagShift1_ISig_3 1;
BA_ "Platform_VMCU1_Sig" SG_ 2566899694 RestingPeriodFlagShift1_ISig_3 1;
BA_ "GenSigSendType" SG_ 2566899694 DailyDrivingTimeShift3_ISig_3 1;
BA_ "GenSigStartValue" SG_ 2566899694 DailyDrivingTimeShift3_ISig_3 32767;
BA_ "Platform_VMCU1_Sig" SG_ 2566899694 DailyDrivingTimeShift3_ISig_3 1;
BA_ "GenSigSendType" SG_ 2566899694 DailyRestingTimeShift2_ISig_3 1;
BA_ "GenSigStartValue" SG_ 2566899694 DailyRestingTimeShift2_ISig_3 32767;
BA_ "Platform_VMCU1_Sig" SG_ 2566899694 DailyRestingTimeShift2_ISig_3 1;
BA_ "GenSigSendType" SG_ 2566899694 DailyRestingTimeShift3_ISig_3 1;
BA_ "GenSigStartValue" SG_ 2566899694 DailyRestingTimeShift3_ISig_3 32767;
BA_ "Platform_VMCU1_Sig" SG_ 2566899694 DailyRestingTimeShift3_ISig_3 1;
BA_ "GenSigSendType" SG_ 2566899694 UnknownPeriodShift2_ISig_3 1;
BA_ "Platform_VMCU1_Sig" SG_ 2566899694 UnknownPeriodShift2_ISig_3 1;
BA_ "GenSigSendType" SG_ 2566899694 RestingPeriodFlag_ISig_3 1;
BA_ "Platform_VMCU1_Sig" SG_ 2566899694 RestingPeriodFlag_ISig_3 1;
BA_ "GenSigSendType" SG_ 2566899694 TwoWeekTotalDrvingTime_ISig_3 1;
BA_ "GenSigStartValue" SG_ 2566899694 TwoWeekTotalDrvingTime_ISig_3 65535;
BA_ "Platform_VMCU1_Sig" SG_ 2566899694 TwoWeekTotalDrvingTime_ISig_3 1;
BA_ "GenSigSendType" SG_ 2566899694 UnknownPeriodShift4_ISig_3 1;
BA_ "Platform_VMCU1_Sig" SG_ 2566899694 UnknownPeriodShift4_ISig_3 1;
BA_ "GenSigSendType" SG_ 2566899694 DailyDrivingTimeShift2_ISig_3 1;
BA_ "GenSigStartValue" SG_ 2566899694 DailyDrivingTimeShift2_ISig_3 32767;
BA_ "Platform_VMCU1_Sig" SG_ 2566899694 DailyDrivingTimeShift2_ISig_3 1;
BA_ "GenSigSendType" SG_ 2566899694 RestingPeriodFlagShift6_ISig_3 1;
BA_ "Platform_VMCU1_Sig" SG_ 2566899694 RestingPeriodFlagShift6_ISig_3 1;
BA_ "GenSigSendType" SG_ 2566899694 DailyRestingTimeShift4_ISig_3 1;
BA_ "GenSigStartValue" SG_ 2566899694 DailyRestingTimeShift4_ISig_3 32767;
BA_ "Platform_VMCU1_Sig" SG_ 2566899694 DailyRestingTimeShift4_ISig_3 1;
BA_ "GenSigSendType" SG_ 2566899694 RestingPeriodFlagShift5_ISig_3 1;
BA_ "Platform_VMCU1_Sig" SG_ 2566899694 RestingPeriodFlagShift5_ISig_3 1;
BA_ "GenSigSendType" SG_ 2566899694 RestingPeriodFlagShift3_ISig_3 1;
BA_ "Platform_VMCU1_Sig" SG_ 2566899694 RestingPeriodFlagShift3_ISig_3 1;
BA_ "GenSigSendType" SG_ 2566899694 DailyDrivingTimeShift5_ISig_3 1;
BA_ "GenSigStartValue" SG_ 2566899694 DailyDrivingTimeShift5_ISig_3 32767;
BA_ "Platform_VMCU1_Sig" SG_ 2566899694 DailyDrivingTimeShift5_ISig_3 1;
BA_ "GenSigSendType" SG_ 2566899694 DailyRestingTimeShift6_ISig_3 1;
BA_ "GenSigStartValue" SG_ 2566899694 DailyRestingTimeShift6_ISig_3 32767;
BA_ "Platform_VMCU1_Sig" SG_ 2566899694 DailyRestingTimeShift6_ISig_3 1;
BA_ "GenSigSendType" SG_ 2566899694 WeeklyTotalDrivingTime_ISig_3 1;
BA_ "GenSigStartValue" SG_ 2566899694 WeeklyTotalDrivingTime_ISig_3 65535;
BA_ "Platform_VMCU1_Sig" SG_ 2566899694 WeeklyTotalDrivingTime_ISig_3 1;
BA_ "GenSigSendType" SG_ 2566899694 UnknownPeriodShift7_ISig_3 1;
BA_ "Platform_VMCU1_Sig" SG_ 2566899694 UnknownPeriodShift7_ISig_3 1;
BA_ "GenSigSendType" SG_ 2566899694 UnknownPeriodShift6_ISig_3 1;
BA_ "Platform_VMCU1_Sig" SG_ 2566899694 UnknownPeriodShift6_ISig_3 1;
BA_ "GenSigSendType" SG_ 2566899694 DailyRestingTimeShift5_ISig_3 1;
BA_ "GenSigStartValue" SG_ 2566899694 DailyRestingTimeShift5_ISig_3 32767;
BA_ "Platform_VMCU1_Sig" SG_ 2566899694 DailyRestingTimeShift5_ISig_3 1;
BA_ "GenSigSendType" SG_ 2566899694 DailyDrivingTimeShift1_ISig_3 1;
BA_ "GenSigStartValue" SG_ 2566899694 DailyDrivingTimeShift1_ISig_3 32767;
BA_ "Platform_VMCU1_Sig" SG_ 2566899694 DailyDrivingTimeShift1_ISig_3 1;
BA_ "GenSigSendType" SG_ 2566899694 UnknownPeriodShift3_ISig_3 1;
BA_ "Platform_VMCU1_Sig" SG_ 2566899694 UnknownPeriodShift3_ISig_3 1;
BA_ "GenSigSendType" SG_ 2566899694 RestingPeriodFlagShift4_ISig_3 1;
BA_ "Platform_VMCU1_Sig" SG_ 2566899694 RestingPeriodFlagShift4_ISig_3 1;
BA_ "GenSigSendType" SG_ 2566899694 DailyDrivingTimeShift6_ISig_3 1;
BA_ "GenSigStartValue" SG_ 2566899694 DailyDrivingTimeShift6_ISig_3 32767;
BA_ "Platform_VMCU1_Sig" SG_ 2566899694 DailyDrivingTimeShift6_ISig_3 1;
BA_ "GenSigSendType" SG_ 2566899694 UnknownPeriodShift5_ISig_3 1;
BA_ "Platform_VMCU1_Sig" SG_ 2566899694 UnknownPeriodShift5_ISig_3 1;
BA_ "GenSigSendType" SG_ 2566898926 Drvr1CumuBreakTime_Tacho 1;
BA_ "GenSigStartValue" SG_ 2566898926 Drvr1CumuBreakTime_Tacho 65535;
BA_ "Platform_VMCU1_Sig" SG_ 2566898926 Drvr1CumuBreakTime_Tacho 1;
BA_ "GenSigSendType" SG_ 2566898926 Drvr1CurDurSelectActy_Tacho 1;
BA_ "GenSigStartValue" SG_ 2566898926 Drvr1CurDurSelectActy_Tacho 65535;
BA_ "Platform_VMCU1_Sig" SG_ 2566898926 Drvr1CurDurSelectActy_Tacho 1;
BA_ "GenSigSendType" SG_ 2566898926 Driver1CardUnload_Tacho 1;
BA_ "GenSigStartValue" SG_ 2566898926 Driver1CardUnload_Tacho 3;
BA_ "Platform_VMCU1_Sig" SG_ 2566898926 Driver1CardUnload_Tacho 1;
BA_ "GenSigSendType" SG_ 2566898926 EndofLifeDriver1Card_Tacho 1;
BA_ "GenSigStartValue" SG_ 2566898926 EndofLifeDriver1Card_Tacho 3;
BA_ "Platform_VMCU1_Sig" SG_ 2566898926 EndofLifeDriver1Card_Tacho 1;
BA_ "GenSigSendType" SG_ 2566898926 DrawerState_Tacho 1;
BA_ "GenSigStartValue" SG_ 2566898926 DrawerState_Tacho 3;
BA_ "Platform_VMCU1_Sig" SG_ 2566898926 DrawerState_Tacho 1;
BA_ "GenSigSendType" SG_ 2566898926 Drvr1ContinDrivingTime_Tacho 1;
BA_ "GenSigStartValue" SG_ 2566898926 Drvr1ContinDrivingTime_Tacho 65535;
BA_ "Platform_VMCU1_Sig" SG_ 2566898926 Drvr1ContinDrivingTime_Tacho 1;
BA_ "GenSigSendType" SG_ 2566898670 NextCalibrationDateDay 1;
BA_ "GenSigStartValue" SG_ 2566898670 NextCalibrationDateDay 255;
BA_ "Platform_VMCU1_Sig" SG_ 2566898670 NextCalibrationDateDay 1;
BA_ "GenSigSendType" SG_ 2566898670 WVehicleCharacteristicFactor 1;
BA_ "GenSigStartValue" SG_ 2566898670 WVehicleCharacteristicFactor 65535;
BA_ "Platform_VMCU1_Sig" SG_ 2566898670 WVehicleCharacteristicFactor 1;
BA_ "GenSigSendType" SG_ 2566898670 NextCalibrationDateMonth 1;
BA_ "GenSigStartValue" SG_ 2566898670 NextCalibrationDateMonth 255;
BA_ "Platform_VMCU1_Sig" SG_ 2566898670 NextCalibrationDateMonth 1;
BA_ "GenSigSendType" SG_ 2566898670 Driver1Identification_ISig_3 1;
BA_ "Platform_VMCU1_Sig" SG_ 2566898670 Driver1Identification_ISig_3 1;
BA_ "GenSigSendType" SG_ 2566898670 NextCalibrationDateYear 1;
BA_ "GenSigStartValue" SG_ 2566898670 NextCalibrationDateYear 255;
BA_ "Platform_VMCU1_Sig" SG_ 2566898670 NextCalibrationDateYear 1;
BA_ "GenSigSendType" SG_ 2565804526 DSRCtoOWSLink 1;
BA_ "GenSigSendType" SG_ 2565860881 OWStoDSRCLink 1;
BA_ "GenSigSendType" SG_ 2671834641 PhysDiagRespSig_F6_11_ISig_3 7;
BA_ "GenSigSendType" SG_ 2671833838 PhysDiagRespSig_F2_EE_ISig_3 7;
BA_ "Platform_VMCU1_Sig" SG_ 2671833838 PhysDiagRespSig_F2_EE_ISig_3 1;
BA_ "GenSigSendType" SG_ 2671833640 PhysDiagRespSig_F2_28_ISig_3 7;
BA_ "Platform_VMCU1_Sig" SG_ 2671833640 PhysDiagRespSig_F2_28_ISig_3 1;
BA_ "GenSigSendType" SG_ 2671833617 PhysDiagRespSig_F2_11_ISig_3 7;
BA_ "Platform_VMCU1_Sig" SG_ 2671833617 PhysDiagRespSig_F2_11_ISig_3 1;
BA_ "GenSigSendType" SG_ 2671833361 PhysDiagRespSig_F1_11_ISig_3 7;
BA_ "Platform_VMCU1_Sig" SG_ 2671833361 PhysDiagRespSig_F1_11_ISig_3 1;
BA_ "GenSigSendType" SG_ 2671832818 PhysDiagReqSig_EE_F2_ISig_3 7;
BA_ "Platform_VMCU1_Sig" SG_ 2671832818 PhysDiagReqSig_EE_F2_ISig_3 1;
BA_ "GenSigSendType" SG_ 2671782130 PhysDiagReqSig_28_F2_ISig_3 7;
BA_ "Platform_VMCU1_Sig" SG_ 2671782130 PhysDiagReqSig_28_F2_ISig_3 1;
BA_ "GenSigSendType" SG_ 2671776246 PhysDiagReqSig_11_F6_ISig_3 7;
BA_ "GenSigSendType" SG_ 2671776242 PhysDiagReqSig_11_F2_ISig_3 7;
BA_ "Platform_VMCU1_Sig" SG_ 2671776242 PhysDiagReqSig_11_F2_ISig_3 1;
BA_ "GenSigSendType" SG_ 2671776241 PhysDiagReqSig_11_F1_ISig_3 7;
BA_ "Platform_VMCU1_Sig" SG_ 2671776241 PhysDiagReqSig_11_F1_ISig_3 1;
BA_ "GenSigCycleTime" SG_ 2566759457 Pto2EnableSwitch 100;
BA_ "GenSigCycleTimeActive" SG_ 2566759457 Pto2EnableSwitch 100;
BA_ "GenSigStartValue" SG_ 2566759457 Pto2EnableSwitch 3;
BA_ "Platform_VMCU1_Sig" SG_ 2566759457 Pto2EnableSwitch 1;
BA_ "SPN" SG_ 2566759457 Pto2EnableSwitch 3453;
BA_ "GenSigCycleTime" SG_ 2566759457 Pto1EnableSwitch 100;
BA_ "GenSigCycleTimeActive" SG_ 2566759457 Pto1EnableSwitch 100;
BA_ "GenSigStartValue" SG_ 2566759457 Pto1EnableSwitch 3;
BA_ "Platform_VMCU1_Sig" SG_ 2566759457 Pto1EnableSwitch 1;
BA_ "SPN" SG_ 2566759457 Pto1EnableSwitch 3452;
BA_ "GenSigCycleTime" SG_ 2566759427 Pto2EngagementConsent 100;
BA_ "GenSigCycleTimeActive" SG_ 2566759427 Pto2EngagementConsent 100;
BA_ "GenSigStartValue" SG_ 2566759427 Pto2EngagementConsent 3;
BA_ "Platform_VMCU1_Sig" SG_ 2566759427 Pto2EngagementConsent 1;
BA_ "SPN" SG_ 2566759427 Pto2EngagementConsent 3457;
BA_ "GenSigCycleTime" SG_ 2566759427 Pto1EngagementConsent 100;
BA_ "GenSigCycleTimeActive" SG_ 2566759427 Pto1EngagementConsent 100;
BA_ "GenSigStartValue" SG_ 2566759427 Pto1EngagementConsent 3;
BA_ "Platform_VMCU1_Sig" SG_ 2566759427 Pto1EngagementConsent 1;
BA_ "SPN" SG_ 2566759427 Pto1EngagementConsent 3456;
BA_ "GenSigSendType" SG_ 2671850481 FuncDiagDataOBD_ISig_3 7;
BA_ "Platform_VMCU1_Sig" SG_ 2671850481 FuncDiagDataOBD_ISig_3 1;
BA_ "GenSigSendType" SG_ 2671850486 FuncDiagDataOBDF6_ISig_3 7;
BA_ "GenSigCycleTime" SG_ 2566844928 InstantaneousFuelEconomy_ISig_3 100;
BA_ "GenSigCycleTimeActive" SG_ 2566844928 InstantaneousFuelEconomy_ISig_3 100;
BA_ "GenSigStartValue" SG_ 2566844928 InstantaneousFuelEconomy_ISig_3 65535;
BA_ "Platform_VMCU1_Sig" SG_ 2566844928 InstantaneousFuelEconomy_ISig_3 1;
BA_ "SPN" SG_ 2566844928 InstantaneousFuelEconomy_ISig_3 184;
BA_ "GenSigCycleTime" SG_ 2566844928 EngineFuelRate_ISig_3 100;
BA_ "GenSigCycleTimeActive" SG_ 2566844928 EngineFuelRate_ISig_3 100;
BA_ "GenSigStartValue" SG_ 2566844928 EngineFuelRate_ISig_3 65535;
BA_ "Platform_VMCU1_Sig" SG_ 2566844928 EngineFuelRate_ISig_3 1;
BA_ "SPN" SG_ 2566844928 EngineFuelRate_ISig_3 183;
BA_ "GenSigCycleTime" SG_ 2566799590 RearFogLights_ISig_3 100;
BA_ "GenSigCycleTimeActive" SG_ 2566799590 RearFogLights_ISig_3 100;
BA_ "GenSigStartValue" SG_ 2566799590 RearFogLights_ISig_3 3;
BA_ "GenSigCycleTime" SG_ 2566799590 LowBeamHeadLightData_ISig_3 100;
BA_ "GenSigCycleTimeActive" SG_ 2566799590 LowBeamHeadLightData_ISig_3 100;
BA_ "GenSigStartValue" SG_ 2566799590 LowBeamHeadLightData_ISig_3 3;
BA_ "GenSigSendType" SG_ 2564428270 KWP2000Response_TACHO 1;
BA_ "Platform_VMCU1_Sig" SG_ 2564428270 KWP2000Response_TACHO 1;
BA_ "GenSigSendType" SG_ 2564484625 KWP2000Request_TACHO 1;
BA_ "Platform_VMCU1_Sig" SG_ 2564484625 KWP2000Request_TACHO 1;
BA_ "GenSigSendType" SG_ 2671902708 FuncDiagDataIntTesterTGW2_ISig_3 7;
BA_ "Platform_VMCU1_Sig" SG_ 2671902708 FuncDiagDataIntTesterTGW2_ISig_3 1;
BA_ "GenSigCycleTime" SG_ 2566825472 EngineTurbo1BoostPressure 100;
BA_ "GenSigCycleTimeActive" SG_ 2566825472 EngineTurbo1BoostPressure 100;
BA_ "GenSigStartValue" SG_ 2566825472 EngineTurbo1BoostPressure 65535;
BA_ "Platform_VMCU1_Sig" SG_ 2566825472 EngineTurbo1BoostPressure 1;
BA_ "SPN" SG_ 2566825472 EngineTurbo1BoostPressure 1127;
BA_ "GenSigCycleTime" SG_ 2566896663 OBDRelDTC_IC_DtcIdA 100;
BA_ "GenSigCycleTimeActive" SG_ 2566896663 OBDRelDTC_IC_DtcIdA 100;
BA_ "GenSigCycleTime" SG_ 2566896663 OBDRelDTC_IC_DtcIdB 100;
BA_ "GenSigCycleTimeActive" SG_ 2566896663 OBDRelDTC_IC_DtcIdB 100;
BA_ "GenSigCycleTime" SG_ 2566896663 OBDRelDTC_IC_EvalStatA 100;
BA_ "GenSigCycleTimeActive" SG_ 2566896663 OBDRelDTC_IC_EvalStatA 100;
BA_ "GenSigStartValue" SG_ 2566896663 OBDRelDTC_IC_EvalStatA 3;
BA_ "GenSigCycleTime" SG_ 2566896663 OBDRelDTC_IC_EvalResultA 100;
BA_ "GenSigCycleTimeActive" SG_ 2566896663 OBDRelDTC_IC_EvalResultA 100;
BA_ "GenSigStartValue" SG_ 2566896663 OBDRelDTC_IC_EvalResultA 3;
BA_ "GenSigCycleTime" SG_ 2566896663 OBDRelDTC_IC_EvalResultB 100;
BA_ "GenSigCycleTimeActive" SG_ 2566896663 OBDRelDTC_IC_EvalResultB 100;
BA_ "GenSigStartValue" SG_ 2566896663 OBDRelDTC_IC_EvalResultB 3;
BA_ "GenSigCycleTime" SG_ 2566896663 OBDRelDTC_IC_EvalStatB 100;
BA_ "GenSigCycleTimeActive" SG_ 2566896663 OBDRelDTC_IC_EvalStatB 100;
BA_ "GenSigStartValue" SG_ 2566896663 OBDRelDTC_IC_EvalStatB 3;
BA_ "GenSigCycleTime" SG_ 2566896663 OBDRelDTC_IC_FailTB 100;
BA_ "GenSigCycleTimeActive" SG_ 2566896663 OBDRelDTC_IC_FailTB 100;
BA_ "GenSigCycleTime" SG_ 2566896663 OBDRelDTC_IC_DrvngCycleB 100;
BA_ "GenSigCycleTimeActive" SG_ 2566896663 OBDRelDTC_IC_DrvngCycleB 100;
BA_ "GenSigStartValue" SG_ 2566896663 OBDRelDTC_IC_DrvngCycleB 3;
BA_ "GenSigCycleTime" SG_ 2566896663 OBDRelDTC_IC_DrvngCycleA 100;
BA_ "GenSigCycleTimeActive" SG_ 2566896663 OBDRelDTC_IC_DrvngCycleA 100;
BA_ "GenSigStartValue" SG_ 2566896663 OBDRelDTC_IC_DrvngCycleA 3;
BA_ "GenSigCycleTime" SG_ 2566896663 OBDRelDTC_IC_FailTA 100;
BA_ "GenSigCycleTimeActive" SG_ 2566896663 OBDRelDTC_IC_FailTA 100;
BA_ "GenSigCycleTime" SG_ 2566896407 AWBEnableRequest 100;
BA_ "GenSigCycleTimeActive" SG_ 2566896407 AWBEnableRequest 100;
BA_ "GenSigStartValue" SG_ 2566896407 AWBEnableRequest 3;
BA_ "GenSigCycleTime" SG_ 2566896407 CCtrlRemActTmpOpRqst_Temp_ISig_3 100;
BA_ "GenSigCycleTimeActive" SG_ 2566896407 CCtrlRemActTmpOpRqst_Temp_ISig_3 100;
BA_ "GenSigStartValue" SG_ 2566896407 CCtrlRemActTmpOpRqst_Temp_ISig_3 255;
BA_ "GenSigCycleTime" SG_ 2566896407 LoadCargoTare_rqst 100;
BA_ "GenSigCycleTimeActive" SG_ 2566896407 LoadCargoTare_rqst 100;
BA_ "GenSigStartValue" SG_ 2566896407 LoadCargoTare_rqst 15;
BA_ "GenSigCycleTime" SG_ 2566896407 DeleteLoadCalib 100;
BA_ "GenSigCycleTimeActive" SG_ 2566896407 DeleteLoadCalib 100;
BA_ "GenSigStartValue" SG_ 2566896407 DeleteLoadCalib 31;
BA_ "GenSigCycleTime" SG_ 2566896407 CCtrlRemActTmpOpRqst_Act_ISig_3 100;
BA_ "GenSigCycleTimeActive" SG_ 2566896407 CCtrlRemActTmpOpRqst_Act_ISig_3 100;
BA_ "GenSigStartValue" SG_ 2566896407 CCtrlRemActTmpOpRqst_Act_ISig_3 7;
BA_ "GenSigSendType" SG_ 2566892452 OBDGWLogHeartBeat_MsgCounter_ISi 1;
BA_ "GenSigCycleTime" SG_ 2566892452 OBDGWLogHeartBeat_MsgCounter_ISi 100;
BA_ "GenSigCycleTimeActive" SG_ 2566892452 OBDGWLogHeartBeat_MsgCounter_ISi 100;
BA_ "GenSigStartValue" SG_ 2566892452 OBDGWLogHeartBeat_MsgCounter_ISi 15;
BA_ "SystemSignalLongSymbol" SG_ 2566892452 OBDGWLogHeartBeat_MsgCounter_ISi "OBDGWLogHeartBeat_MsgCounter_ISig_3";
BA_ "GenSigSendType" SG_ 2566892452 OBDGWLogHeartBeat_Data1_ISig_3 1;
BA_ "GenSigCycleTime" SG_ 2566892452 OBDGWLogHeartBeat_Data1_ISig_3 100;
BA_ "GenSigCycleTimeActive" SG_ 2566892452 OBDGWLogHeartBeat_Data1_ISig_3 100;
BA_ "GenSigStartValue" SG_ 2566892452 OBDGWLogHeartBeat_Data1_ISig_3 255;
BA_ "GenSigSendType" SG_ 2566892452 OBDGWLogHeartBeat_Data0_ISig_3 1;
BA_ "GenSigCycleTime" SG_ 2566892452 OBDGWLogHeartBeat_Data0_ISig_3 100;
BA_ "GenSigCycleTimeActive" SG_ 2566892452 OBDGWLogHeartBeat_Data0_ISig_3 100;
BA_ "GenSigStartValue" SG_ 2566892452 OBDGWLogHeartBeat_Data0_ISig_3 255;
BA_ "GenSigSendType" SG_ 2566892452 OBDGWLogHeartBeat_Data4_ISig_3 1;
BA_ "GenSigCycleTime" SG_ 2566892452 OBDGWLogHeartBeat_Data4_ISig_3 100;
BA_ "GenSigCycleTimeActive" SG_ 2566892452 OBDGWLogHeartBeat_Data4_ISig_3 100;
BA_ "GenSigStartValue" SG_ 2566892452 OBDGWLogHeartBeat_Data4_ISig_3 255;
BA_ "GenSigSendType" SG_ 2566892452 OBDGWLogHeartBeat_Data2_ISig_3 1;
BA_ "GenSigCycleTime" SG_ 2566892452 OBDGWLogHeartBeat_Data2_ISig_3 100;
BA_ "GenSigCycleTimeActive" SG_ 2566892452 OBDGWLogHeartBeat_Data2_ISig_3 100;
BA_ "GenSigStartValue" SG_ 2566892452 OBDGWLogHeartBeat_Data2_ISig_3 255;
BA_ "GenSigSendType" SG_ 2566892452 OBDGWLogHeartBeat_Data5_ISig_3 1;
BA_ "GenSigCycleTime" SG_ 2566892452 OBDGWLogHeartBeat_Data5_ISig_3 100;
BA_ "GenSigCycleTimeActive" SG_ 2566892452 OBDGWLogHeartBeat_Data5_ISig_3 100;
BA_ "GenSigStartValue" SG_ 2566892452 OBDGWLogHeartBeat_Data5_ISig_3 255;
BA_ "GenSigSendType" SG_ 2566892452 OBDGWLogHeartBeat_Data3_ISig_3 1;
BA_ "GenSigCycleTime" SG_ 2566892452 OBDGWLogHeartBeat_Data3_ISig_3 100;
BA_ "GenSigCycleTimeActive" SG_ 2566892452 OBDGWLogHeartBeat_Data3_ISig_3 100;
BA_ "GenSigStartValue" SG_ 2566892452 OBDGWLogHeartBeat_Data3_ISig_3 255;
BA_ "GenSigSendType" SG_ 2566892452 OBDGWLogHeartBeat_MsgChecksum_IS 1;
BA_ "GenSigCycleTime" SG_ 2566892452 OBDGWLogHeartBeat_MsgChecksum_IS 100;
BA_ "GenSigCycleTimeActive" SG_ 2566892452 OBDGWLogHeartBeat_MsgChecksum_IS 100;
BA_ "GenSigStartValue" SG_ 2566892452 OBDGWLogHeartBeat_MsgChecksum_IS 15;
BA_ "SystemSignalLongSymbol" SG_ 2566892452 OBDGWLogHeartBeat_MsgChecksum_IS "OBDGWLogHeartBeat_MsgChecksum_ISig_3";
BA_ "GenSigSendType" SG_ 2566892452 OBDGWLogHeartBeat_Data6_ISig_3 1;
BA_ "GenSigCycleTime" SG_ 2566892452 OBDGWLogHeartBeat_Data6_ISig_3 100;
BA_ "GenSigCycleTimeActive" SG_ 2566892452 OBDGWLogHeartBeat_Data6_ISig_3 100;
BA_ "GenSigStartValue" SG_ 2566892452 OBDGWLogHeartBeat_Data6_ISig_3 255;
BA_ "GenSigCycleTime" SG_ 2298372875 FrontAxleRightWheelSpeed_ISig_3 100;
BA_ "GenSigCycleTimeActive" SG_ 2298372875 FrontAxleRightWheelSpeed_ISig_3 100;
BA_ "GenSigStartValue" SG_ 2298372875 FrontAxleRightWheelSpeed_ISig_3 65535;
BA_ "Platform_VMCU1_Sig" SG_ 2298372875 FrontAxleRightWheelSpeed_ISig_3 1;
BA_ "SPN" SG_ 2298372875 FrontAxleRightWheelSpeed_ISig_3 1593;
BA_ "SeToolAncestorID_SIGNAL" SG_ 2298372875 FrontAxleRightWheelSpeed_ISig_3 "x0000001D0410DA6F";
BA_ "SeToolItemID_SIGNAL" SG_ 2298372875 FrontAxleRightWheelSpeed_ISig_3 "x0000001D0410DA6F";
BA_ "SeToolName_SIGNAL" SG_ 2298372875 FrontAxleRightWheelSpeed_ISig_3 "FrontAxleRightWheelSpeed";
BA_ "SeToolVersion_SIGNAL" SG_ 2298372875 FrontAxleRightWheelSpeed_ISig_3 "1";
BA_ "GenSigCycleTime" SG_ 2298372875 RearAxleLeftWheelSpeed_ISig_3 100;
BA_ "GenSigCycleTimeActive" SG_ 2298372875 RearAxleLeftWheelSpeed_ISig_3 100;
BA_ "GenSigStartValue" SG_ 2298372875 RearAxleLeftWheelSpeed_ISig_3 65535;
BA_ "Platform_VMCU1_Sig" SG_ 2298372875 RearAxleLeftWheelSpeed_ISig_3 1;
BA_ "SPN" SG_ 2298372875 RearAxleLeftWheelSpeed_ISig_3 1594;
BA_ "SeToolAncestorID_SIGNAL" SG_ 2298372875 RearAxleLeftWheelSpeed_ISig_3 "x0000001D0410DA87";
BA_ "SeToolItemID_SIGNAL" SG_ 2298372875 RearAxleLeftWheelSpeed_ISig_3 "x0000001D0410DA87";
BA_ "SeToolName_SIGNAL" SG_ 2298372875 RearAxleLeftWheelSpeed_ISig_3 "RearAxleLeftWheelSpeed";
BA_ "SeToolVersion_SIGNAL" SG_ 2298372875 RearAxleLeftWheelSpeed_ISig_3 "1";
BA_ "GenSigCycleTime" SG_ 2298372875 RearAxleRightWheelSpeed_ISig_3 100;
BA_ "GenSigCycleTimeActive" SG_ 2298372875 RearAxleRightWheelSpeed_ISig_3 100;
BA_ "GenSigStartValue" SG_ 2298372875 RearAxleRightWheelSpeed_ISig_3 65535;
BA_ "Platform_VMCU1_Sig" SG_ 2298372875 RearAxleRightWheelSpeed_ISig_3 1;
BA_ "SPN" SG_ 2298372875 RearAxleRightWheelSpeed_ISig_3 1595;
BA_ "SeToolAncestorID_SIGNAL" SG_ 2298372875 RearAxleRightWheelSpeed_ISig_3 "x0000001D0410DA80";
BA_ "SeToolItemID_SIGNAL" SG_ 2298372875 RearAxleRightWheelSpeed_ISig_3 "x0000001D0410DA80";
BA_ "SeToolName_SIGNAL" SG_ 2298372875 RearAxleRightWheelSpeed_ISig_3 "RearAxleRightWheelSpeed";
BA_ "SeToolVersion_SIGNAL" SG_ 2298372875 RearAxleRightWheelSpeed_ISig_3 "1";
BA_ "GenSigCycleTime" SG_ 2298372875 FrontAxleLeftWheelSpeed_ISig_3 100;
BA_ "GenSigCycleTimeActive" SG_ 2298372875 FrontAxleLeftWheelSpeed_ISig_3 100;
BA_ "GenSigStartValue" SG_ 2298372875 FrontAxleLeftWheelSpeed_ISig_3 65535;
BA_ "Platform_VMCU1_Sig" SG_ 2298372875 FrontAxleLeftWheelSpeed_ISig_3 1;
BA_ "SPN" SG_ 2298372875 FrontAxleLeftWheelSpeed_ISig_3 1592;
BA_ "SeToolAncestorID_SIGNAL" SG_ 2298372875 FrontAxleLeftWheelSpeed_ISig_3 "x0000001D0410DA66";
BA_ "SeToolItemID_SIGNAL" SG_ 2298372875 FrontAxleLeftWheelSpeed_ISig_3 "x0000001D0410DA66";
BA_ "SeToolName_SIGNAL" SG_ 2298372875 FrontAxleLeftWheelSpeed_ISig_3 "FrontAxleLeftWheelSpeed";
BA_ "SeToolVersion_SIGNAL" SG_ 2298372875 FrontAxleLeftWheelSpeed_ISig_3 "1";
BA_ "GenSigCycleTime" SG_ 2566719744 HighResEngineTotalFuelUsed_ISig_ 100;
BA_ "GenSigCycleTimeActive" SG_ 2566719744 HighResEngineTotalFuelUsed_ISig_ 100;
BA_ "GenSigStartValue" SG_ 2566719744 HighResEngineTotalFuelUsed_ISig_ 4294967295;
BA_ "Platform_VMCU1_Sig" SG_ 2566719744 HighResEngineTotalFuelUsed_ISig_ 1;
BA_ "SPN" SG_ 2566719744 HighResEngineTotalFuelUsed_ISig_ 5054;
BA_ "SystemSignalLongSymbol" SG_ 2566719744 HighResEngineTotalFuelUsed_ISig_ "HighResEngineTotalFuelUsed_ISig_3";
BA_ "GenSigCycleTime" SG_ 2566841600 EngineRevolutions_ISig_3 100;
BA_ "GenSigCycleTimeActive" SG_ 2566841600 EngineRevolutions_ISig_3 100;
BA_ "GenSigStartValue" SG_ 2566841600 EngineRevolutions_ISig_3 4294967295;
BA_ "Platform_VMCU1_Sig" SG_ 2566841600 EngineRevolutions_ISig_3 1;
BA_ "SPN" SG_ 2566841600 EngineRevolutions_ISig_3 249;
BA_ "GenSigCycleTime" SG_ 2566749463 FMS1_TellTaleStatus4_ISig_3 100;
BA_ "GenSigCycleTimeActive" SG_ 2566749463 FMS1_TellTaleStatus4_ISig_3 100;
BA_ "GenSigStartValue" SG_ 2566749463 FMS1_TellTaleStatus4_ISig_3 7;
BA_ "GenSigCycleTime" SG_ 2566749463 FMS1_TellTaleStatus10_ISig_3 100;
BA_ "GenSigCycleTimeActive" SG_ 2566749463 FMS1_TellTaleStatus10_ISig_3 100;
BA_ "GenSigStartValue" SG_ 2566749463 FMS1_TellTaleStatus10_ISig_3 7;
BA_ "GenSigCycleTime" SG_ 2566749463 FMS1_TellTaleStatus6_ISig_3 100;
BA_ "GenSigCycleTimeActive" SG_ 2566749463 FMS1_TellTaleStatus6_ISig_3 100;
BA_ "GenSigStartValue" SG_ 2566749463 FMS1_TellTaleStatus6_ISig_3 7;
BA_ "GenSigCycleTime" SG_ 2566749463 FMS1_TellTaleStatus8_ISig_3 100;
BA_ "GenSigCycleTimeActive" SG_ 2566749463 FMS1_TellTaleStatus8_ISig_3 100;
BA_ "GenSigStartValue" SG_ 2566749463 FMS1_TellTaleStatus8_ISig_3 7;
BA_ "GenSigCycleTime" SG_ 2566749463 FMS1_TellTaleStatus5_ISig_3 100;
BA_ "GenSigCycleTimeActive" SG_ 2566749463 FMS1_TellTaleStatus5_ISig_3 100;
BA_ "GenSigStartValue" SG_ 2566749463 FMS1_TellTaleStatus5_ISig_3 7;
BA_ "GenSigCycleTime" SG_ 2566749463 FMS1_TellTaleStatus12_ISig_3 100;
BA_ "GenSigCycleTimeActive" SG_ 2566749463 FMS1_TellTaleStatus12_ISig_3 100;
BA_ "GenSigStartValue" SG_ 2566749463 FMS1_TellTaleStatus12_ISig_3 7;
BA_ "GenSigCycleTime" SG_ 2566749463 FMS1_Blockid_ISig_3 100;
BA_ "GenSigCycleTimeActive" SG_ 2566749463 FMS1_Blockid_ISig_3 100;
BA_ "GenSigStartValue" SG_ 2566749463 FMS1_Blockid_ISig_3 15;
BA_ "GenSigCycleTime" SG_ 2566749463 FMS1_TellTaleStatus14_ISig_3 100;
BA_ "GenSigCycleTimeActive" SG_ 2566749463 FMS1_TellTaleStatus14_ISig_3 100;
BA_ "GenSigStartValue" SG_ 2566749463 FMS1_TellTaleStatus14_ISig_3 7;
BA_ "GenSigCycleTime" SG_ 2566749463 FMS1_TellTaleStatus1_ISig_3 100;
BA_ "GenSigCycleTimeActive" SG_ 2566749463 FMS1_TellTaleStatus1_ISig_3 100;
BA_ "GenSigStartValue" SG_ 2566749463 FMS1_TellTaleStatus1_ISig_3 7;
BA_ "GenSigCycleTime" SG_ 2566749463 FMS1_TellTaleStatus2_ISig_3 100;
BA_ "GenSigCycleTimeActive" SG_ 2566749463 FMS1_TellTaleStatus2_ISig_3 100;
BA_ "GenSigStartValue" SG_ 2566749463 FMS1_TellTaleStatus2_ISig_3 7;
BA_ "GenSigCycleTime" SG_ 2566749463 FMS1_TellTaleStatus11_ISig_3 100;
BA_ "GenSigCycleTimeActive" SG_ 2566749463 FMS1_TellTaleStatus11_ISig_3 100;
BA_ "GenSigStartValue" SG_ 2566749463 FMS1_TellTaleStatus11_ISig_3 7;
BA_ "GenSigCycleTime" SG_ 2566749463 FMS1_TellTaleStatus15_ISig_3 100;
BA_ "GenSigCycleTimeActive" SG_ 2566749463 FMS1_TellTaleStatus15_ISig_3 100;
BA_ "GenSigStartValue" SG_ 2566749463 FMS1_TellTaleStatus15_ISig_3 7;
BA_ "GenSigCycleTime" SG_ 2566749463 FMS1_TellTaleStatus3_ISig_3 100;
BA_ "GenSigCycleTimeActive" SG_ 2566749463 FMS1_TellTaleStatus3_ISig_3 100;
BA_ "GenSigStartValue" SG_ 2566749463 FMS1_TellTaleStatus3_ISig_3 7;
BA_ "GenSigCycleTime" SG_ 2566749463 FMS1_TellTaleStatus13_ISig_3 100;
BA_ "GenSigCycleTimeActive" SG_ 2566749463 FMS1_TellTaleStatus13_ISig_3 100;
BA_ "GenSigStartValue" SG_ 2566749463 FMS1_TellTaleStatus13_ISig_3 7;
BA_ "GenSigCycleTime" SG_ 2566749463 FMS1_TellTaleStatus9_ISig_3 100;
BA_ "GenSigCycleTimeActive" SG_ 2566749463 FMS1_TellTaleStatus9_ISig_3 100;
BA_ "GenSigStartValue" SG_ 2566749463 FMS1_TellTaleStatus9_ISig_3 7;
BA_ "GenSigCycleTime" SG_ 2566749463 FMS1_TellTaleStatus7_ISig_3 100;
BA_ "GenSigCycleTimeActive" SG_ 2566749463 FMS1_TellTaleStatus7_ISig_3 100;
BA_ "GenSigStartValue" SG_ 2566749463 FMS1_TellTaleStatus7_ISig_3 7;
BA_ "GenSigCycleTime" SG_ 2566801923 TransmEngineCrankEnable2_ISig_3 100;
BA_ "GenSigCycleTimeActive" SG_ 2566801923 TransmEngineCrankEnable2_ISig_3 100;
BA_ "GenSigStartValue" SG_ 2566801923 TransmEngineCrankEnable2_ISig_3 3;
BA_ "Platform_VMCU1_Sig" SG_ 2566801923 TransmEngineCrankEnable2_ISig_3 1;
BA_ "SPN" SG_ 2566801923 TransmEngineCrankEnable2_ISig_3 2900;
BA_ "GenSigCycleTime" SG_ 2565866755 TransmissionActualGearRatio_ISig 100;
BA_ "GenSigCycleTimeActive" SG_ 2565866755 TransmissionActualGearRatio_ISig 100;
BA_ "GenSigStartValue" SG_ 2565866755 TransmissionActualGearRatio_ISig 65535;
BA_ "Platform_VMCU1_Sig" SG_ 2565866755 TransmissionActualGearRatio_ISig 1;
BA_ "SPN" SG_ 2565866755 TransmissionActualGearRatio_ISig 526;
BA_ "SeToolAncestorID_SIGNAL" SG_ 2565866755 TransmissionActualGearRatio_ISig "x0000001D0414E198";
BA_ "SeToolItemID_SIGNAL" SG_ 2565866755 TransmissionActualGearRatio_ISig "x0000001D0414E198";
BA_ "SeToolName_SIGNAL" SG_ 2565866755 TransmissionActualGearRatio_ISig "TransmissionActualGearRatio";
BA_ "SeToolVersion_SIGNAL" SG_ 2565866755 TransmissionActualGearRatio_ISig "1";
BA_ "SystemSignalLongSymbol" SG_ 2565866755 TransmissionActualGearRatio_ISig "TransmissionActualGearRatio_ISig_3";
BA_ "GenSigCycleTime" SG_ 2565866755 TransmissionCurrentGear_ISig_3 100;
BA_ "GenSigCycleTimeActive" SG_ 2565866755 TransmissionCurrentGear_ISig_3 100;
BA_ "GenSigStartValue" SG_ 2565866755 TransmissionCurrentGear_ISig_3 255;
BA_ "Platform_VMCU1_Sig" SG_ 2565866755 TransmissionCurrentGear_ISig_3 1;
BA_ "SPN" SG_ 2565866755 TransmissionCurrentGear_ISig_3 523;
BA_ "SeToolAncestorID_SIGNAL" SG_ 2565866755 TransmissionCurrentGear_ISig_3 "x0000001D0412E700";
BA_ "SeToolItemID_SIGNAL" SG_ 2565866755 TransmissionCurrentGear_ISig_3 "x0000001D0412E700";
BA_ "SeToolName_SIGNAL" SG_ 2565866755 TransmissionCurrentGear_ISig_3 "TransmissionCurrentGear";
BA_ "SeToolVersion_SIGNAL" SG_ 2565866755 TransmissionCurrentGear_ISig_3 "1";
BA_ "GenSigCycleTime" SG_ 2565866755 TransmissionRangeSelected_ISig_3 100;
BA_ "GenSigCycleTimeActive" SG_ 2565866755 TransmissionRangeSelected_ISig_3 100;
BA_ "Platform_VMCU1_Sig" SG_ 2565866755 TransmissionRangeSelected_ISig_3 1;
BA_ "SPN" SG_ 2565866755 TransmissionRangeSelected_ISig_3 162;
BA_ "SigType" SG_ 2565866755 TransmissionRangeSelected_ISig_3 3;
BA_ "SeToolAncestorID_SIGNAL" SG_ 2565866755 TransmissionRangeSelected_ISig_3 "x0000001D0416F5C6";
BA_ "SeToolItemID_SIGNAL" SG_ 2565866755 TransmissionRangeSelected_ISig_3 "x0000001D04320F35";
BA_ "SeToolName_SIGNAL" SG_ 2565866755 TransmissionRangeSelected_ISig_3 "TransmissionRangeSelected";
BA_ "SeToolVersion_SIGNAL" SG_ 2565866755 TransmissionRangeSelected_ISig_3 "2";
BA_ "GenSigCycleTime" SG_ 2565866755 TransmissionRangeAttained_ISig_3 100;
BA_ "GenSigCycleTimeActive" SG_ 2565866755 TransmissionRangeAttained_ISig_3 100;
BA_ "Platform_VMCU1_Sig" SG_ 2565866755 TransmissionRangeAttained_ISig_3 1;
BA_ "SPN" SG_ 2565866755 TransmissionRangeAttained_ISig_3 163;
BA_ "SigType" SG_ 2565866755 TransmissionRangeAttained_ISig_3 3;
BA_ "SeToolAncestorID_SIGNAL" SG_ 2565866755 TransmissionRangeAttained_ISig_3 "x0000001D04296471";
BA_ "SeToolItemID_SIGNAL" SG_ 2565866755 TransmissionRangeAttained_ISig_3 "x0000001D04296471";
BA_ "SeToolName_SIGNAL" SG_ 2565866755 TransmissionRangeAttained_ISig_3 "TransmissionRangeAttained";
BA_ "SeToolVersion_SIGNAL" SG_ 2565866755 TransmissionRangeAttained_ISig_3 "1";
BA_ "GenSigCycleTime" SG_ 2565866755 TransmissionSelectedGear_ISig_3 100;
BA_ "GenSigCycleTimeActive" SG_ 2565866755 TransmissionSelectedGear_ISig_3 100;
BA_ "GenSigStartValue" SG_ 2565866755 TransmissionSelectedGear_ISig_3 255;
BA_ "Platform_VMCU1_Sig" SG_ 2565866755 TransmissionSelectedGear_ISig_3 1;
BA_ "SPN" SG_ 2565866755 TransmissionSelectedGear_ISig_3 524;
BA_ "SeToolAncestorID_SIGNAL" SG_ 2565866755 TransmissionSelectedGear_ISig_3 "x0000001D0416F5A6";
BA_ "SeToolItemID_SIGNAL" SG_ 2565866755 TransmissionSelectedGear_ISig_3 "x0000001D0416F5A6";
BA_ "SeToolName_SIGNAL" SG_ 2565866755 TransmissionSelectedGear_ISig_3 "TransmissionSelectedGear";
BA_ "SeToolVersion_SIGNAL" SG_ 2565866755 TransmissionSelectedGear_ISig_3 "1";
BA_ "GenSigCycleTime" SG_ 2364539395 PercentClutchSlip_ISig_3 100;
BA_ "GenSigCycleTimeActive" SG_ 2364539395 PercentClutchSlip_ISig_3 100;
BA_ "GenSigStartValue" SG_ 2364539395 PercentClutchSlip_ISig_3 255;
BA_ "Platform_VMCU1_Sig" SG_ 2364539395 PercentClutchSlip_ISig_3 1;
BA_ "SPN" SG_ 2364539395 PercentClutchSlip_ISig_3 522;
BA_ "SeToolAncestorID_SIGNAL" SG_ 2364539395 PercentClutchSlip_ISig_3 "x0000001D04174A3C";
BA_ "SeToolItemID_SIGNAL" SG_ 2364539395 PercentClutchSlip_ISig_3 "x0000001D04174A3C";
BA_ "SeToolName_SIGNAL" SG_ 2364539395 PercentClutchSlip_ISig_3 "PercentClutchSlip";
BA_ "SeToolVersion_SIGNAL" SG_ 2364539395 PercentClutchSlip_ISig_3 "1";
BA_ "GenSigCycleTime" SG_ 2364539395 TransmissionOutputShaftSpeed2 100;
BA_ "GenSigCycleTimeActive" SG_ 2364539395 TransmissionOutputShaftSpeed2 100;
BA_ "GenSigStartValue" SG_ 2364539395 TransmissionOutputShaftSpeed2 65535;
BA_ "Platform_VMCU1_Sig" SG_ 2364539395 TransmissionOutputShaftSpeed2 1;
BA_ "SPN" SG_ 2364539395 TransmissionOutputShaftSpeed2 191;
BA_ "GenSigCycleTime" SG_ 2364539395 TransmTrqConvrtrLockupEngd_ISig_ 100;
BA_ "GenSigCycleTimeActive" SG_ 2364539395 TransmTrqConvrtrLockupEngd_ISig_ 100;
BA_ "GenSigStartValue" SG_ 2364539395 TransmTrqConvrtrLockupEngd_ISig_ 3;
BA_ "Platform_VMCU1_Sig" SG_ 2364539395 TransmTrqConvrtrLockupEngd_ISig_ 1;
BA_ "SPN" SG_ 2364539395 TransmTrqConvrtrLockupEngd_ISig_ 573;
BA_ "SystemSignalLongSymbol" SG_ 2364539395 TransmTrqConvrtrLockupEngd_ISig_ "TransmTrqConvrtrLockupEngd_ISig_3";
BA_ "GenSigCycleTime" SG_ 2364539395 TransmissionDrivelineEngaged_ISi 100;
BA_ "GenSigCycleTimeActive" SG_ 2364539395 TransmissionDrivelineEngaged_ISi 100;
BA_ "GenSigStartValue" SG_ 2364539395 TransmissionDrivelineEngaged_ISi 3;
BA_ "Platform_VMCU1_Sig" SG_ 2364539395 TransmissionDrivelineEngaged_ISi 1;
BA_ "SPN" SG_ 2364539395 TransmissionDrivelineEngaged_ISi 560;
BA_ "SeToolAncestorID_SIGNAL" SG_ 2364539395 TransmissionDrivelineEngaged_ISi "x0000001D0410CEC8";
BA_ "SeToolItemID_SIGNAL" SG_ 2364539395 TransmissionDrivelineEngaged_ISi "x0000001D0410CEC8";
BA_ "SeToolName_SIGNAL" SG_ 2364539395 TransmissionDrivelineEngaged_ISi "TransmissionDrivelineEngaged";
BA_ "SeToolVersion_SIGNAL" SG_ 2364539395 TransmissionDrivelineEngaged_ISi "1";
BA_ "SystemSignalLongSymbol" SG_ 2364539395 TransmissionDrivelineEngaged_ISi "TransmissionDrivelineEngaged_ISig_3";
BA_ "GenSigCycleTime" SG_ 2364539395 TransmissionInputShaftSpeed_ISig 100;
BA_ "GenSigCycleTimeActive" SG_ 2364539395 TransmissionInputShaftSpeed_ISig 100;
BA_ "GenSigStartValue" SG_ 2364539395 TransmissionInputShaftSpeed_ISig 65535;
BA_ "Platform_VMCU1_Sig" SG_ 2364539395 TransmissionInputShaftSpeed_ISig 1;
BA_ "SPN" SG_ 2364539395 TransmissionInputShaftSpeed_ISig 161;
BA_ "SeToolAncestorID_SIGNAL" SG_ 2364539395 TransmissionInputShaftSpeed_ISig "x0000001D0410D25D";
BA_ "SeToolItemID_SIGNAL" SG_ 2364539395 TransmissionInputShaftSpeed_ISig "x0000001D0410D25D";
BA_ "SeToolName_SIGNAL" SG_ 2364539395 TransmissionInputShaftSpeed_ISig "TransmissionInputShaftSpeed";
BA_ "SeToolVersion_SIGNAL" SG_ 2364539395 TransmissionInputShaftSpeed_ISig "1";
BA_ "SystemSignalLongSymbol" SG_ 2364539395 TransmissionInputShaftSpeed_ISig "TransmissionInputShaftSpeed_ISig_3";
BA_ "GenSigCycleTime" SG_ 2364539395 MomentaryEngineOverspeedEnable_I 100;
BA_ "GenSigCycleTimeActive" SG_ 2364539395 MomentaryEngineOverspeedEnable_I 100;
BA_ "GenSigStartValue" SG_ 2364539395 MomentaryEngineOverspeedEnable_I 3;
BA_ "Platform_VMCU1_Sig" SG_ 2364539395 MomentaryEngineOverspeedEnable_I 1;
BA_ "SPN" SG_ 2364539395 MomentaryEngineOverspeedEnable_I 606;
BA_ "SeToolAncestorID_SIGNAL" SG_ 2364539395 MomentaryEngineOverspeedEnable_I "x0000001D041DB5AB";
BA_ "SeToolItemID_SIGNAL" SG_ 2364539395 MomentaryEngineOverspeedEnable_I "x0000001D041DB5AB";
BA_ "SeToolName_SIGNAL" SG_ 2364539395 MomentaryEngineOverspeedEnable_I "MomentaryEngineOverspeedEnable";
BA_ "SeToolVersion_SIGNAL" SG_ 2364539395 MomentaryEngineOverspeedEnable_I "1";
BA_ "SystemSignalLongSymbol" SG_ 2364539395 MomentaryEngineOverspeedEnable_I "MomentaryEngineOverspeedEnable_ISig_3";
BA_ "GenSigCycleTime" SG_ 2364539395 TransmissionShiftInProcess_ISig_ 100;
BA_ "GenSigCycleTimeActive" SG_ 2364539395 TransmissionShiftInProcess_ISig_ 100;
BA_ "GenSigStartValue" SG_ 2364539395 TransmissionShiftInProcess_ISig_ 3;
BA_ "Platform_VMCU1_Sig" SG_ 2364539395 TransmissionShiftInProcess_ISig_ 1;
BA_ "SPN" SG_ 2364539395 TransmissionShiftInProcess_ISig_ 574;
BA_ "SeToolAncestorID_SIGNAL" SG_ 2364539395 TransmissionShiftInProcess_ISig_ "x0000001D0410D0F1";
BA_ "SeToolItemID_SIGNAL" SG_ 2364539395 TransmissionShiftInProcess_ISig_ "x0000001D0410D0F1";
BA_ "SeToolName_SIGNAL" SG_ 2364539395 TransmissionShiftInProcess_ISig_ "TransmissionShiftInProcess";
BA_ "SeToolVersion_SIGNAL" SG_ 2364539395 TransmissionShiftInProcess_ISig_ "1";
BA_ "SystemSignalLongSymbol" SG_ 2364539395 TransmissionShiftInProcess_ISig_ "TransmissionShiftInProcess_ISig_3";
BA_ "GenSigCycleTime" SG_ 2566843904 EngineOilTemperature_ISig_3 100;
BA_ "GenSigCycleTimeActive" SG_ 2566843904 EngineOilTemperature_ISig_3 100;
BA_ "GenSigStartValue" SG_ 2566843904 EngineOilTemperature_ISig_3 65535;
BA_ "Platform_FactoryIf_Sig" SG_ 2566843904 EngineOilTemperature_ISig_3 1;
BA_ "Platform_VMCU1_Sig" SG_ 2566843904 EngineOilTemperature_ISig_3 1;
BA_ "SPN" SG_ 2566843904 EngineOilTemperature_ISig_3 175;
BA_ "SeToolAncestorID_SIGNAL" SG_ 2566843904 EngineOilTemperature_ISig_3 "x0000001D0413132D";
BA_ "SeToolItemID_SIGNAL" SG_ 2566843904 EngineOilTemperature_ISig_3 "x0000001D0413132D";
BA_ "SeToolName_SIGNAL" SG_ 2566843904 EngineOilTemperature_ISig_3 "EngineOilTemperature";
BA_ "SeToolVersion_SIGNAL" SG_ 2566843904 EngineOilTemperature_ISig_3 "1";
BA_ "GenSigCycleTime" SG_ 2566843904 EngineCoolantTemp_stat_ISig_3 100;
BA_ "GenSigCycleTimeActive" SG_ 2566843904 EngineCoolantTemp_stat_ISig_3 100;
BA_ "GenSigStartValue" SG_ 2566843904 EngineCoolantTemp_stat_ISig_3 255;
BA_ "Platform_VMCU1_Sig" SG_ 2566843904 EngineCoolantTemp_stat_ISig_3 1;
BA_ "SPN" SG_ 2566843904 EngineCoolantTemp_stat_ISig_3 110;
BA_ "SeToolAncestorID_SIGNAL" SG_ 2566843904 EngineCoolantTemp_stat_ISig_3 "x0000001D0410E5B1";
BA_ "SeToolItemID_SIGNAL" SG_ 2566843904 EngineCoolantTemp_stat_ISig_3 "x0000001D0410E5B1";
BA_ "SeToolName_SIGNAL" SG_ 2566843904 EngineCoolantTemp_stat_ISig_3 "EngineCoolantTemperature_status";
BA_ "SeToolVersion_SIGNAL" SG_ 2566843904 EngineCoolantTemp_stat_ISig_3 "1";
BA_ "GenSigCycleTime" SG_ 2565865488 EngineCoolantLoadIncrease 100;
BA_ "GenSigCycleTimeActive" SG_ 2565865488 EngineCoolantLoadIncrease 100;
BA_ "GenSigStartValue" SG_ 2565865488 EngineCoolantLoadIncrease 3;
BA_ "Platform_VMCU1_Sig" SG_ 2565865488 EngineCoolantLoadIncrease 1;
BA_ "SPN" SG_ 2565865488 EngineCoolantLoadIncrease 1082;
BA_ "GenSigCycleTime" SG_ 2565865488 ActualMaxAvailDrvlnRetPrctTrq 100;
BA_ "GenSigCycleTimeActive" SG_ 2565865488 ActualMaxAvailDrvlnRetPrctTrq 100;
BA_ "GenSigStartValue" SG_ 2565865488 ActualMaxAvailDrvlnRetPrctTrq 255;
BA_ "Platform_VMCU1_Sig" SG_ 2565865488 ActualMaxAvailDrvlnRetPrctTrq 1;
BA_ "SPN" SG_ 2565865488 ActualMaxAvailDrvlnRetPrctTrq 1717;
BA_ "GenSigCycleTime" SG_ 2565865488 ActualDrvlnRetdrPercentTorque_IS 100;
BA_ "GenSigCycleTimeActive" SG_ 2565865488 ActualDrvlnRetdrPercentTorque_IS 100;
BA_ "GenSigStartValue" SG_ 2565865488 ActualDrvlnRetdrPercentTorque_IS 255;
BA_ "Platform_VMCU1_Sig" SG_ 2565865488 ActualDrvlnRetdrPercentTorque_IS 1;
BA_ "SPN" SG_ 2565865488 ActualDrvlnRetdrPercentTorque_IS 520;
BA_ "SeToolAncestorID_SIGNAL" SG_ 2565865488 ActualDrvlnRetdrPercentTorque_IS "x0000001D0410CFDE";
BA_ "SeToolItemID_SIGNAL" SG_ 2565865488 ActualDrvlnRetdrPercentTorque_IS "x0000001D0410CFDE";
BA_ "SeToolName_SIGNAL" SG_ 2565865488 ActualDrvlnRetdrPercentTorque_IS "ActualDrivelineRetarderPercentTorque";
BA_ "SeToolVersion_SIGNAL" SG_ 2565865488 ActualDrvlnRetdrPercentTorque_IS "1";
BA_ "SystemSignalLongSymbol" SG_ 2565865488 ActualDrvlnRetdrPercentTorque_IS "ActualDrvlnRetdrPercentTorque_ISig_3";
BA_ "GenSigCycleTime" SG_ 2565865488 RetarderTorqueMode_ISig_3 100;
BA_ "GenSigCycleTimeActive" SG_ 2565865488 RetarderTorqueMode_ISig_3 100;
BA_ "GenSigStartValue" SG_ 2565865488 RetarderTorqueMode_ISig_3 15;
BA_ "Platform_VMCU1_Sig" SG_ 2565865488 RetarderTorqueMode_ISig_3 1;
BA_ "SPN" SG_ 2565865488 RetarderTorqueMode_ISig_3 900;
BA_ "GenSigCycleTime" SG_ 2565865487 ActlMaxAvailEngRetdrPercentTrq 100;
BA_ "GenSigCycleTimeActive" SG_ 2565865487 ActlMaxAvailEngRetdrPercentTrq 100;
BA_ "GenSigStartValue" SG_ 2565865487 ActlMaxAvailEngRetdrPercentTrq 255;
BA_ "Platform_VMCU1_Sig" SG_ 2565865487 ActlMaxAvailEngRetdrPercentTrq 1;
BA_ "SPN" SG_ 2565865487 ActlMaxAvailEngRetdrPercentTrq 1717;
BA_ "SeToolAncestorID_SIGNAL" SG_ 2565865487 ActlMaxAvailEngRetdrPercentTrq "x0000001D041286DD";
BA_ "SeToolItemID_SIGNAL" SG_ 2565865487 ActlMaxAvailEngRetdrPercentTrq "x0000001D0437CD37";
BA_ "SeToolName_SIGNAL" SG_ 2565865487 ActlMaxAvailEngRetdrPercentTrq "ActualMaximumAvailableEngineRetarder-PercentTorque";
BA_ "SeToolVersion_SIGNAL" SG_ 2565865487 ActlMaxAvailEngRetdrPercentTrq "2";
BA_ "GenSigCycleTime" SG_ 2565865487 RetarderEnableShiftAssistSw 100;
BA_ "GenSigCycleTimeActive" SG_ 2565865487 RetarderEnableShiftAssistSw 100;
BA_ "GenSigStartValue" SG_ 2565865487 RetarderEnableShiftAssistSw 3;
BA_ "Platform_VMCU1_Sig" SG_ 2565865487 RetarderEnableShiftAssistSw 1;
BA_ "SPN" SG_ 2565865487 RetarderEnableShiftAssistSw 572;
BA_ "SeToolAncestorID_SIGNAL" SG_ 2565865487 RetarderEnableShiftAssistSw "x0000001D042E05A1";
BA_ "SeToolItemID_SIGNAL" SG_ 2565865487 RetarderEnableShiftAssistSw "x0000001D042E05A1";
BA_ "SeToolName_SIGNAL" SG_ 2565865487 RetarderEnableShiftAssistSw "RetarderEnableShiftAssistSwitch";
BA_ "SeToolVersion_SIGNAL" SG_ 2565865487 RetarderEnableShiftAssistSw "1";
BA_ "GenSigCycleTime" SG_ 2565865487 EngineRetarderTorqueMode_ISig_3 100;
BA_ "GenSigCycleTimeActive" SG_ 2565865487 EngineRetarderTorqueMode_ISig_3 100;
BA_ "GenSigStartValue" SG_ 2565865487 EngineRetarderTorqueMode_ISig_3 15;
BA_ "SPN" SG_ 2565865487 EngineRetarderTorqueMode_ISig_3 900;
BA_ "GenSigCycleTime" SG_ 2565865487 EngRetdrEnableBrakeAssistSw 100;
BA_ "GenSigCycleTimeActive" SG_ 2565865487 EngRetdrEnableBrakeAssistSw 100;
BA_ "GenSigStartValue" SG_ 2565865487 EngRetdrEnableBrakeAssistSw 3;
BA_ "Platform_VMCU1_Sig" SG_ 2565865487 EngRetdrEnableBrakeAssistSw 1;
BA_ "SPN" SG_ 2565865487 EngRetdrEnableBrakeAssistSw 571;
BA_ "GenSigCycleTime" SG_ 2565865487 ActualEngineRetarderPercentTrq_I 100;
BA_ "GenSigCycleTimeActive" SG_ 2565865487 ActualEngineRetarderPercentTrq_I 100;
BA_ "GenSigStartValue" SG_ 2565865487 ActualEngineRetarderPercentTrq_I 255;
BA_ "Platform_VMCU1_Sig" SG_ 2565865487 ActualEngineRetarderPercentTrq_I 1;
BA_ "SPN" SG_ 2565865487 ActualEngineRetarderPercentTrq_I 520;
BA_ "SeToolAncestorID_SIGNAL" SG_ 2565865487 ActualEngineRetarderPercentTrq_I "x0000001D0410BAE1";
BA_ "SeToolItemID_SIGNAL" SG_ 2565865487 ActualEngineRetarderPercentTrq_I "x0000001D043C302E";
BA_ "SeToolName_SIGNAL" SG_ 2565865487 ActualEngineRetarderPercentTrq_I "ActualEngineRetarderPercentTorque";
BA_ "SeToolVersion_SIGNAL" SG_ 2565865487 ActualEngineRetarderPercentTrq_I "2";
BA_ "SystemSignalLongSymbol" SG_ 2565865487 ActualEngineRetarderPercentTrq_I "ActualEngineRetarderPercentTrq_ISig_3";
BA_ "GenSigCycleTime" SG_ 2364541440 EngineIntakeAirRate 100;
BA_ "GenSigCycleTimeActive" SG_ 2364541440 EngineIntakeAirRate 100;
BA_ "GenSigStartValue" SG_ 2364541440 EngineIntakeAirRate 65535;
BA_ "SPN" SG_ 2364541440 EngineIntakeAirRate 132;
BA_ "GenSigCycleTime" SG_ 2566844160 EngineOilLevel_ISig_3 100;
BA_ "GenSigCycleTimeActive" SG_ 2566844160 EngineOilLevel_ISig_3 100;
BA_ "GenSigStartValue" SG_ 2566844160 EngineOilLevel_ISig_3 255;
BA_ "Platform_VMCU1_Sig" SG_ 2566844160 EngineOilLevel_ISig_3 1;
BA_ "SPN" SG_ 2566844160 EngineOilLevel_ISig_3 98;
BA_ "SeToolAncestorID_SIGNAL" SG_ 2566844160 EngineOilLevel_ISig_3 "x0000001D0412B86E";
BA_ "SeToolItemID_SIGNAL" SG_ 2566844160 EngineOilLevel_ISig_3 "x0000001D0412B86E";
BA_ "SeToolName_SIGNAL" SG_ 2566844160 EngineOilLevel_ISig_3 "EngineOilLevel";
BA_ "SeToolVersion_SIGNAL" SG_ 2566844160 EngineOilLevel_ISig_3 "1";
BA_ "GenSigCycleTime" SG_ 2566844160 EngineOilPressure_ISig_3 100;
BA_ "GenSigCycleTimeActive" SG_ 2566844160 EngineOilPressure_ISig_3 100;
BA_ "GenSigStartValue" SG_ 2566844160 EngineOilPressure_ISig_3 255;
BA_ "Platform_FactoryIf_Sig" SG_ 2566844160 EngineOilPressure_ISig_3 1;
BA_ "Platform_VMCU1_Sig" SG_ 2566844160 EngineOilPressure_ISig_3 1;
BA_ "SPN" SG_ 2566844160 EngineOilPressure_ISig_3 100;
BA_ "SeToolAncestorID_SIGNAL" SG_ 2566844160 EngineOilPressure_ISig_3 "x0000001D041937A0";
BA_ "SeToolItemID_SIGNAL" SG_ 2566844160 EngineOilPressure_ISig_3 "x0000001D041937A0";
BA_ "SeToolName_SIGNAL" SG_ 2566844160 EngineOilPressure_ISig_3 "EngineOilPressure";
BA_ "SeToolVersion_SIGNAL" SG_ 2566844160 EngineOilPressure_ISig_3 "1";
BA_ "GenSigCycleTime" SG_ 2566840064 NominalFrictionPercentTorque_ISi 100;
BA_ "GenSigCycleTimeActive" SG_ 2566840064 NominalFrictionPercentTorque_ISi 100;
BA_ "GenSigStartValue" SG_ 2566840064 NominalFrictionPercentTorque_ISi 255;
BA_ "Platform_VMCU1_Sig" SG_ 2566840064 NominalFrictionPercentTorque_ISi 1;
BA_ "SPN" SG_ 2566840064 NominalFrictionPercentTorque_ISi 514;
BA_ "SeToolAncestorID_SIGNAL" SG_ 2566840064 NominalFrictionPercentTorque_ISi "x0000001D0410CF68";
BA_ "SeToolItemID_SIGNAL" SG_ 2566840064 NominalFrictionPercentTorque_ISi "x0000001D04295709";
BA_ "SeToolName_SIGNAL" SG_ 2566840064 NominalFrictionPercentTorque_ISi "NominalFrictionPercentTorque";
BA_ "SeToolVersion_SIGNAL" SG_ 2566840064 NominalFrictionPercentTorque_ISi "2";
BA_ "SystemSignalLongSymbol" SG_ 2566840064 NominalFrictionPercentTorque_ISi "NominalFrictionPercentTorque_ISig_3";
BA_ "GenSigCycleTime" SG_ 2364539665 AcceleratorPedalPositionVendor 100;
BA_ "GenSigCycleTimeActive" SG_ 2364539665 AcceleratorPedalPositionVendor 100;
BA_ "GenSigStartValue" SG_ 2364539665 AcceleratorPedalPositionVendor 255;
BA_ "SPN" SG_ 2364539665 AcceleratorPedalPositionVendor 91;
BA_ "GenSigCycleTime" SG_ 2364539648 EnginePercentLoadAtCurrentSpd_IS 100;
BA_ "GenSigCycleTimeActive" SG_ 2364539648 EnginePercentLoadAtCurrentSpd_IS 100;
BA_ "GenSigStartValue" SG_ 2364539648 EnginePercentLoadAtCurrentSpd_IS 255;
BA_ "Platform_FactoryIf_Sig" SG_ 2364539648 EnginePercentLoadAtCurrentSpd_IS 1;
BA_ "Platform_VMCU1_Sig" SG_ 2364539648 EnginePercentLoadAtCurrentSpd_IS 1;
BA_ "SPN" SG_ 2364539648 EnginePercentLoadAtCurrentSpd_IS 92;
BA_ "SeToolAncestorID_SIGNAL" SG_ 2364539648 EnginePercentLoadAtCurrentSpd_IS "x0000001D04172658";
BA_ "SeToolItemID_SIGNAL" SG_ 2364539648 EnginePercentLoadAtCurrentSpd_IS "x0000001D04172658";
BA_ "SeToolName_SIGNAL" SG_ 2364539648 EnginePercentLoadAtCurrentSpd_IS "EnginePercentLoadAtCurrentSpeed";
BA_ "SeToolVersion_SIGNAL" SG_ 2364539648 EnginePercentLoadAtCurrentSpd_IS "1";
BA_ "SystemSignalLongSymbol" SG_ 2364539648 EnginePercentLoadAtCurrentSpd_IS "EnginePercentLoadAtCurrentSpd_ISig_3";
BA_ "GenSigCycleTime" SG_ 2364539648 AcceleratorPedalPosition1_2 100;
BA_ "GenSigCycleTimeActive" SG_ 2364539648 AcceleratorPedalPosition1_2 100;
BA_ "GenSigStartValue" SG_ 2364539648 AcceleratorPedalPosition1_2 255;
BA_ "Platform_VMCU1_Sig" SG_ 2364539648 AcceleratorPedalPosition1_2 1;
BA_ "SPN" SG_ 2364539648 AcceleratorPedalPosition1_2 91;
BA_ "GenSigCycleTime" SG_ 2364539648 RoadSpeedLimitStatus 100;
BA_ "GenSigCycleTimeActive" SG_ 2364539648 RoadSpeedLimitStatus 100;
BA_ "GenSigStartValue" SG_ 2364539648 RoadSpeedLimitStatus 3;
BA_ "Platform_VMCU1_Sig" SG_ 2364539648 RoadSpeedLimitStatus 1;
BA_ "SPN" SG_ 2364539648 RoadSpeedLimitStatus 1437;
BA_ "GenSigCycleTime" SG_ 2364539904 EngineDemandPercentTorque 100;
BA_ "GenSigCycleTimeActive" SG_ 2364539904 EngineDemandPercentTorque 100;
BA_ "GenSigStartValue" SG_ 2364539904 EngineDemandPercentTorque 255;
BA_ "Platform_VMCU1_Sig" SG_ 2364539904 EngineDemandPercentTorque 1;
BA_ "SPN" SG_ 2364539904 EngineDemandPercentTorque 2432;
BA_ "GenSigCycleTime" SG_ 2364539904 DrvrDemandEngPercentTorque_ISig_ 100;
BA_ "GenSigCycleTimeActive" SG_ 2364539904 DrvrDemandEngPercentTorque_ISig_ 100;
BA_ "GenSigStartValue" SG_ 2364539904 DrvrDemandEngPercentTorque_ISig_ 255;
BA_ "Platform_VMCU1_Sig" SG_ 2364539904 DrvrDemandEngPercentTorque_ISig_ 1;
BA_ "SPN" SG_ 2364539904 DrvrDemandEngPercentTorque_ISig_ 512;
BA_ "SeToolAncestorID_SIGNAL" SG_ 2364539904 DrvrDemandEngPercentTorque_ISig_ "x0000001D0410D0C7";
BA_ "SeToolItemID_SIGNAL" SG_ 2364539904 DrvrDemandEngPercentTorque_ISig_ "x0000001D0410D0C7";
BA_ "SeToolName_SIGNAL" SG_ 2364539904 DrvrDemandEngPercentTorque_ISig_ "Driver'sDemandEngine-PercentTorque";
BA_ "SeToolVersion_SIGNAL" SG_ 2364539904 DrvrDemandEngPercentTorque_ISig_ "1";
BA_ "SystemSignalLongSymbol" SG_ 2364539904 DrvrDemandEngPercentTorque_ISig_ "DrvrDemandEngPercentTorque_ISig_3";
BA_ "GenSigCycleTime" SG_ 2364539904 EngineTorqueMode_ISig_3 100;
BA_ "GenSigCycleTimeActive" SG_ 2364539904 EngineTorqueMode_ISig_3 100;
BA_ "GenSigStartValue" SG_ 2364539904 EngineTorqueMode_ISig_3 15;
BA_ "Platform_VMCU1_Sig" SG_ 2364539904 EngineTorqueMode_ISig_3 1;
BA_ "SPN" SG_ 2364539904 EngineTorqueMode_ISig_3 899;
BA_ "SeToolAncestorID_SIGNAL" SG_ 2364539904 EngineTorqueMode_ISig_3 "x0000001D0414E4FD";
BA_ "SeToolItemID_SIGNAL" SG_ 2364539904 EngineTorqueMode_ISig_3 "x0000001D0414E4FD";
BA_ "SeToolName_SIGNAL" SG_ 2364539904 EngineTorqueMode_ISig_3 "EngineTorqueMode";
BA_ "SeToolVersion_SIGNAL" SG_ 2364539904 EngineTorqueMode_ISig_3 "1";
BA_ "GenSigCycleTime" SG_ 2364539904 EngineSpeed_ISig_3 100;
BA_ "GenSigCycleTimeActive" SG_ 2364539904 EngineSpeed_ISig_3 100;
BA_ "GenSigStartValue" SG_ 2364539904 EngineSpeed_ISig_3 65535;
BA_ "Platform_VMCU1_Sig" SG_ 2364539904 EngineSpeed_ISig_3 1;
BA_ "SPN" SG_ 2364539904 EngineSpeed_ISig_3 190;
BA_ "SeToolAncestorID_SIGNAL" SG_ 2364539904 EngineSpeed_ISig_3 "x0000001D0410BACF";
BA_ "SeToolItemID_SIGNAL" SG_ 2364539904 EngineSpeed_ISig_3 "x0000001D0410BACF";
BA_ "SeToolName_SIGNAL" SG_ 2364539904 EngineSpeed_ISig_3 "EngineSpeed_status";
BA_ "SeToolVersion_SIGNAL" SG_ 2364539904 EngineSpeed_ISig_3 "1";
BA_ "GenSigCycleTime" SG_ 2364539904 ActualEnginePercentTorque_ISig_3 100;
BA_ "GenSigCycleTimeActive" SG_ 2364539904 ActualEnginePercentTorque_ISig_3 100;
BA_ "GenSigStartValue" SG_ 2364539904 ActualEnginePercentTorque_ISig_3 255;
BA_ "Platform_VMCU1_Sig" SG_ 2364539904 ActualEnginePercentTorque_ISig_3 1;
BA_ "SPN" SG_ 2364539904 ActualEnginePercentTorque_ISig_3 513;
BA_ "SeToolAncestorID_SIGNAL" SG_ 2364539904 ActualEnginePercentTorque_ISig_3 "x0000001D0410CDD5";
BA_ "SeToolItemID_SIGNAL" SG_ 2364539904 ActualEnginePercentTorque_ISig_3 "x0000001D0410CDD5";
BA_ "SeToolName_SIGNAL" SG_ 2364539904 ActualEnginePercentTorque_ISig_3 "ActualEngine-PercentTorque";
BA_ "SeToolVersion_SIGNAL" SG_ 2364539904 ActualEnginePercentTorque_ISig_3 "1";
BA_ "GenSigCycleTime" SG_ 2364539904 EngineStarterMode_ISig_3 100;
BA_ "GenSigCycleTimeActive" SG_ 2364539904 EngineStarterMode_ISig_3 100;
BA_ "GenSigStartValue" SG_ 2364539904 EngineStarterMode_ISig_3 15;
BA_ "Platform_FactoryIf_Sig" SG_ 2364539904 EngineStarterMode_ISig_3 1;
BA_ "Platform_VMCU1_Sig" SG_ 2364539904 EngineStarterMode_ISig_3 1;
BA_ "SPN" SG_ 2364539904 EngineStarterMode_ISig_3 1675;
BA_ "SeToolAncestorID_SIGNAL" SG_ 2364539904 EngineStarterMode_ISig_3 "x0000001D04146CF7";
BA_ "SeToolItemID_SIGNAL" SG_ 2364539904 EngineStarterMode_ISig_3 "x0000001D04146CF7";
BA_ "SeToolName_SIGNAL" SG_ 2364539904 EngineStarterMode_ISig_3 "EngineStarterMode";
BA_ "SeToolVersion_SIGNAL" SG_ 2364539904 EngineStarterMode_ISig_3 "1";
BA_ "GenSigSendType" SG_ 2566841088 EngConf_EngSpeedAtHighIdle_P6 3;
BA_ "GenSigStartValue" SG_ 2566841088 EngConf_EngSpeedAtHighIdle_P6 65535;
BA_ "Platform_VMCU1_Sig" SG_ 2566841088 EngConf_EngSpeedAtHighIdle_P6 1;
BA_ "SPN" SG_ 2566841088 EngConf_EngSpeedAtHighIdle_P6 532;
BA_ "SeToolAncestorID_SIGNAL" SG_ 2566841088 EngConf_EngSpeedAtHighIdle_P6 "x0000001D0429A8E3";
BA_ "SeToolItemID_SIGNAL" SG_ 2566841088 EngConf_EngSpeedAtHighIdle_P6 "x0000001D0429A8E3";
BA_ "SeToolName_SIGNAL" SG_ 2566841088 EngConf_EngSpeedAtHighIdle_P6 "EngConf_EngSpeedAtHighIdle_P6";
BA_ "SeToolVersion_SIGNAL" SG_ 2566841088 EngConf_EngSpeedAtHighIdle_P6 "1";
BA_ "GenSigSendType" SG_ 2566841088 EngConf_EngTorqueAt_P4 3;
BA_ "GenSigStartValue" SG_ 2566841088 EngConf_EngTorqueAt_P4 255;
BA_ "Platform_VMCU1_Sig" SG_ 2566841088 EngConf_EngTorqueAt_P4 1;
BA_ "SPN" SG_ 2566841088 EngConf_EngTorqueAt_P4 542;
BA_ "SeToolAncestorID_SIGNAL" SG_ 2566841088 EngConf_EngTorqueAt_P4 "x0000001D0429EA2A";
BA_ "SeToolItemID_SIGNAL" SG_ 2566841088 EngConf_EngTorqueAt_P4 "x0000001D0429EA2A";
BA_ "SeToolName_SIGNAL" SG_ 2566841088 EngConf_EngTorqueAt_P4 "EngConf_EngTorqueAt_P4";
BA_ "SeToolVersion_SIGNAL" SG_ 2566841088 EngConf_EngTorqueAt_P4 "1";
BA_ "GenSigSendType" SG_ 2566841088 EngConf_EngMaxMomOvSpeed_P7 3;
BA_ "GenSigStartValue" SG_ 2566841088 EngConf_EngMaxMomOvSpeed_P7 65535;
BA_ "Platform_VMCU1_Sig" SG_ 2566841088 EngConf_EngMaxMomOvSpeed_P7 1;
BA_ "SPN" SG_ 2566841088 EngConf_EngMaxMomOvSpeed_P7 533;
BA_ "SeToolAncestorID_SIGNAL" SG_ 2566841088 EngConf_EngMaxMomOvSpeed_P7 "x0000001D0429A8EA";
BA_ "SeToolItemID_SIGNAL" SG_ 2566841088 EngConf_EngMaxMomOvSpeed_P7 "x0000001D0429A8EA";
BA_ "SeToolName_SIGNAL" SG_ 2566841088 EngConf_EngMaxMomOvSpeed_P7 "EngConf_EngMaxMomOvSpeed_P7";
BA_ "SeToolVersion_SIGNAL" SG_ 2566841088 EngConf_EngMaxMomOvSpeed_P7 "1";
BA_ "GenSigSendType" SG_ 2566841088 EngConf_EngTorqueAt_P5 3;
BA_ "GenSigStartValue" SG_ 2566841088 EngConf_EngTorqueAt_P5 255;
BA_ "Platform_VMCU1_Sig" SG_ 2566841088 EngConf_EngTorqueAt_P5 1;
BA_ "SPN" SG_ 2566841088 EngConf_EngTorqueAt_P5 543;
BA_ "SeToolAncestorID_SIGNAL" SG_ 2566841088 EngConf_EngTorqueAt_P5 "x0000001D0429EA2C";
BA_ "SeToolItemID_SIGNAL" SG_ 2566841088 EngConf_EngTorqueAt_P5 "x0000001D0429EA2C";
BA_ "SeToolName_SIGNAL" SG_ 2566841088 EngConf_EngTorqueAt_P5 "EngConf_EngTorqueAt_P5";
BA_ "SeToolVersion_SIGNAL" SG_ 2566841088 EngConf_EngTorqueAt_P5 "1";
BA_ "GenSigSendType" SG_ 2566841088 EngConf_EngSpeedAtIdle_P1 3;
BA_ "GenSigStartValue" SG_ 2566841088 EngConf_EngSpeedAtIdle_P1 65535;
BA_ "Platform_VMCU1_Sig" SG_ 2566841088 EngConf_EngSpeedAtIdle_P1 1;
BA_ "SPN" SG_ 2566841088 EngConf_EngSpeedAtIdle_P1 539;
BA_ "SeToolAncestorID_SIGNAL" SG_ 2566841088 EngConf_EngSpeedAtIdle_P1 "x0000001D0429A8D5";
BA_ "SeToolItemID_SIGNAL" SG_ 2566841088 EngConf_EngSpeedAtIdle_P1 "x0000001D0429A8D5";
BA_ "SeToolName_SIGNAL" SG_ 2566841088 EngConf_EngSpeedAtIdle_P1 "EngConf_EngSpeedAtIdle_P1";
BA_ "SeToolVersion_SIGNAL" SG_ 2566841088 EngConf_EngSpeedAtIdle_P1 "1";
BA_ "GenSigSendType" SG_ 2566841088 EngineReferenceTorque_ISig_3 3;
BA_ "GenSigStartValue" SG_ 2566841088 EngineReferenceTorque_ISig_3 65535;
BA_ "Platform_VMCU1_Sig" SG_ 2566841088 EngineReferenceTorque_ISig_3 1;
BA_ "SPN" SG_ 2566841088 EngineReferenceTorque_ISig_3 544;
BA_ "SeToolAncestorID_SIGNAL" SG_ 2566841088 EngineReferenceTorque_ISig_3 "x0000001D041286BC";
BA_ "SeToolItemID_SIGNAL" SG_ 2566841088 EngineReferenceTorque_ISig_3 "x0000001D041286BC";
BA_ "SeToolName_SIGNAL" SG_ 2566841088 EngineReferenceTorque_ISig_3 "EngineReferenceTorque";
BA_ "SeToolVersion_SIGNAL" SG_ 2566841088 EngineReferenceTorque_ISig_3 "1";
BA_ "GenSigSendType" SG_ 2566841088 EngConf_EngSpeedAt_P2 3;
BA_ "GenSigStartValue" SG_ 2566841088 EngConf_EngSpeedAt_P2 65535;
BA_ "Platform_VMCU1_Sig" SG_ 2566841088 EngConf_EngSpeedAt_P2 1;
BA_ "SPN" SG_ 2566841088 EngConf_EngSpeedAt_P2 528;
BA_ "SeToolAncestorID_SIGNAL" SG_ 2566841088 EngConf_EngSpeedAt_P2 "x0000001D0429A8D8";
BA_ "SeToolItemID_SIGNAL" SG_ 2566841088 EngConf_EngSpeedAt_P2 "x0000001D0429A8D8";
BA_ "SeToolName_SIGNAL" SG_ 2566841088 EngConf_EngSpeedAt_P2 "EngConf_EngSpeedAt_P2";
BA_ "SeToolVersion_SIGNAL" SG_ 2566841088 EngConf_EngSpeedAt_P2 "1";
BA_ "GenSigSendType" SG_ 2566841088 EngConf_MaxMomOverrideTimeLim 3;
BA_ "GenSigStartValue" SG_ 2566841088 EngConf_MaxMomOverrideTimeLim 255;
BA_ "Platform_VMCU1_Sig" SG_ 2566841088 EngConf_MaxMomOverrideTimeLim 1;
BA_ "SPN" SG_ 2566841088 EngConf_MaxMomOverrideTimeLim 534;
BA_ "SeToolAncestorID_SIGNAL" SG_ 2566841088 EngConf_MaxMomOverrideTimeLim "x0000001D0429EA9F";
BA_ "SeToolItemID_SIGNAL" SG_ 2566841088 EngConf_MaxMomOverrideTimeLim "x0000001D0429EA9F";
BA_ "SeToolName_SIGNAL" SG_ 2566841088 EngConf_MaxMomOverrideTimeLim "EngConf_MaxMomOverrideTimeLimit";
BA_ "SeToolVersion_SIGNAL" SG_ 2566841088 EngConf_MaxMomOverrideTimeLim "1";
BA_ "GenSigSendType" SG_ 2566841088 EngConf_EngSpeedAt_P5 3;
BA_ "GenSigStartValue" SG_ 2566841088 EngConf_EngSpeedAt_P5 65535;
BA_ "Platform_VMCU1_Sig" SG_ 2566841088 EngConf_EngSpeedAt_P5 1;
BA_ "SPN" SG_ 2566841088 EngConf_EngSpeedAt_P5 531;
BA_ "SeToolAncestorID_SIGNAL" SG_ 2566841088 EngConf_EngSpeedAt_P5 "x0000001D0429A8E1";
BA_ "SeToolItemID_SIGNAL" SG_ 2566841088 EngConf_EngSpeedAt_P5 "x0000001D0429A8E1";
BA_ "SeToolName_SIGNAL" SG_ 2566841088 EngConf_EngSpeedAt_P5 "EngConf_EngSpeedAt_P5";
BA_ "SeToolVersion_SIGNAL" SG_ 2566841088 EngConf_EngSpeedAt_P5 "1";
BA_ "GenSigSendType" SG_ 2566841088 EngConf_EngTorqueAtIdle_P1 3;
BA_ "GenSigStartValue" SG_ 2566841088 EngConf_EngTorqueAtIdle_P1 255;
BA_ "Platform_VMCU1_Sig" SG_ 2566841088 EngConf_EngTorqueAtIdle_P1 1;
BA_ "SPN" SG_ 2566841088 EngConf_EngTorqueAtIdle_P1 188;
BA_ "SeToolAncestorID_SIGNAL" SG_ 2566841088 EngConf_EngTorqueAtIdle_P1 "x0000001D0429EA1D";
BA_ "SeToolItemID_SIGNAL" SG_ 2566841088 EngConf_EngTorqueAtIdle_P1 "x0000001D0429EA1D";
BA_ "SeToolName_SIGNAL" SG_ 2566841088 EngConf_EngTorqueAtIdle_P1 "EngConf_EngTorqueAtIdle_P1";
BA_ "SeToolVersion_SIGNAL" SG_ 2566841088 EngConf_EngTorqueAtIdle_P1 "1";
BA_ "GenSigSendType" SG_ 2566841088 EngConf_EngSpeedAt_P4 3;
BA_ "GenSigStartValue" SG_ 2566841088 EngConf_EngSpeedAt_P4 65535;
BA_ "Platform_VMCU1_Sig" SG_ 2566841088 EngConf_EngSpeedAt_P4 1;
BA_ "SPN" SG_ 2566841088 EngConf_EngSpeedAt_P4 530;
BA_ "SeToolAncestorID_SIGNAL" SG_ 2566841088 EngConf_EngSpeedAt_P4 "x0000001D0429A8DF";
BA_ "SeToolItemID_SIGNAL" SG_ 2566841088 EngConf_EngSpeedAt_P4 "x0000001D0429A8DF";
BA_ "SeToolName_SIGNAL" SG_ 2566841088 EngConf_EngSpeedAt_P4 "EngConf_EngSpeedAt_P4";
BA_ "SeToolVersion_SIGNAL" SG_ 2566841088 EngConf_EngSpeedAt_P4 "1";
BA_ "GenSigSendType" SG_ 2566841088 EngConf_EngSpeedAt_P3 3;
BA_ "GenSigStartValue" SG_ 2566841088 EngConf_EngSpeedAt_P3 65535;
BA_ "Platform_VMCU1_Sig" SG_ 2566841088 EngConf_EngSpeedAt_P3 1;
BA_ "SPN" SG_ 2566841088 EngConf_EngSpeedAt_P3 529;
BA_ "SeToolAncestorID_SIGNAL" SG_ 2566841088 EngConf_EngSpeedAt_P3 "x0000001D0429A8DD";
BA_ "SeToolItemID_SIGNAL" SG_ 2566841088 EngConf_EngSpeedAt_P3 "x0000001D0429A8DD";
BA_ "SeToolName_SIGNAL" SG_ 2566841088 EngConf_EngSpeedAt_P3 "EngConf_EngSpeedAt_P3";
BA_ "SeToolVersion_SIGNAL" SG_ 2566841088 EngConf_EngSpeedAt_P3 "1";
BA_ "GenSigSendType" SG_ 2566841088 EngConf_EngTorqueAt_P3 3;
BA_ "GenSigStartValue" SG_ 2566841088 EngConf_EngTorqueAt_P3 255;
BA_ "Platform_VMCU1_Sig" SG_ 2566841088 EngConf_EngTorqueAt_P3 1;
BA_ "SPN" SG_ 2566841088 EngConf_EngTorqueAt_P3 541;
BA_ "SeToolAncestorID_SIGNAL" SG_ 2566841088 EngConf_EngTorqueAt_P3 "x0000001D0429EA28";
BA_ "SeToolItemID_SIGNAL" SG_ 2566841088 EngConf_EngTorqueAt_P3 "x0000001D0429EA28";
BA_ "SeToolName_SIGNAL" SG_ 2566841088 EngConf_EngTorqueAt_P3 "EngConf_EngTorqueAt_P3";
BA_ "SeToolVersion_SIGNAL" SG_ 2566841088 EngConf_EngTorqueAt_P3 "1";
BA_ "GenSigSendType" SG_ 2566841088 EngConf_EngTorqueAt_P2 3;
BA_ "GenSigStartValue" SG_ 2566841088 EngConf_EngTorqueAt_P2 255;
BA_ "Platform_VMCU1_Sig" SG_ 2566841088 EngConf_EngTorqueAt_P2 1;
BA_ "SPN" SG_ 2566841088 EngConf_EngTorqueAt_P2 540;
BA_ "SeToolAncestorID_SIGNAL" SG_ 2566841088 EngConf_EngTorqueAt_P2 "x0000001D0429EA26";
BA_ "SeToolItemID_SIGNAL" SG_ 2566841088 EngConf_EngTorqueAt_P2 "x0000001D0429EA26";
BA_ "SeToolName_SIGNAL" SG_ 2566841088 EngConf_EngTorqueAt_P2 "EngConf_EngTorqueAt_P2";
BA_ "SeToolVersion_SIGNAL" SG_ 2566841088 EngConf_EngTorqueAt_P2 "1";
BA_ "GenSigCycleTime" SG_ 2566911243 Trailer5PneumSupply_Status_ISig_ 100;
BA_ "GenSigCycleTimeActive" SG_ 2566911243 Trailer5PneumSupply_Status_ISig_ 100;
BA_ "GenSigStartValue" SG_ 2566911243 Trailer5PneumSupply_Status_ISig_ 3;
BA_ "GenSigMaxLatency" SG_ 2566911243 Trailer5PneumSupply_Status_ISig_ 1150;
BA_ "SystemSignalLongSymbol" SG_ 2566911243 Trailer5PneumSupply_Status_ISig_ "Trailer5PneumSupply_Status_ISig_3";
BA_ "GenSigCycleTime" SG_ 2566911243 Trailer5VehicleType_ISig_3 100;
BA_ "GenSigCycleTimeActive" SG_ 2566911243 Trailer5VehicleType_ISig_3 100;
BA_ "GenSigStartValue" SG_ 2566911243 Trailer5VehicleType_ISig_3 3;
BA_ "GenSigMaxLatency" SG_ 2566911243 Trailer5VehicleType_ISig_3 1150;
BA_ "GenSigCycleTime" SG_ 2566911243 Trailer5ElectricalSupplyStat_ISi 100;
BA_ "GenSigCycleTimeActive" SG_ 2566911243 Trailer5ElectricalSupplyStat_ISi 100;
BA_ "GenSigStartValue" SG_ 2566911243 Trailer5ElectricalSupplyStat_ISi 3;
BA_ "GenSigMaxLatency" SG_ 2566911243 Trailer5ElectricalSupplyStat_ISi 1150;
BA_ "SystemSignalLongSymbol" SG_ 2566911243 Trailer5ElectricalSupplyStat_ISi "Trailer5ElectricalSupplyStat_ISig_3";
BA_ "GenSigCycleTime" SG_ 2566911243 Trailer5ROPSystemStatus_ISig_3 100;
BA_ "GenSigCycleTimeActive" SG_ 2566911243 Trailer5ROPSystemStatus_ISig_3 100;
BA_ "GenSigStartValue" SG_ 2566911243 Trailer5ROPSystemStatus_ISig_3 3;
BA_ "GenSigMaxLatency" SG_ 2566911243 Trailer5ROPSystemStatus_ISig_3 1150;
BA_ "GenSigCycleTime" SG_ 2566911243 Trailer5EBSRedWarning_ISig_3 100;
BA_ "GenSigCycleTimeActive" SG_ 2566911243 Trailer5EBSRedWarning_ISig_3 100;
BA_ "GenSigStartValue" SG_ 2566911243 Trailer5EBSRedWarning_ISig_3 3;
BA_ "GenSigMaxLatency" SG_ 2566911243 Trailer5EBSRedWarning_ISig_3 1150;
BA_ "GenSigCycleTime" SG_ 2566911243 Trailer5PneumSupply_Pressure_ISi 100;
BA_ "GenSigCycleTimeActive" SG_ 2566911243 Trailer5PneumSupply_Pressure_ISi 100;
BA_ "GenSigStartValue" SG_ 2566911243 Trailer5PneumSupply_Pressure_ISi 255;
BA_ "GenSigMaxLatency" SG_ 2566911243 Trailer5PneumSupply_Pressure_ISi 1150;
BA_ "SystemSignalLongSymbol" SG_ 2566911243 Trailer5PneumSupply_Pressure_ISi "Trailer5PneumSupply_Pressure_ISig_3";
BA_ "GenSigCycleTime" SG_ 2566911243 Trailer5LoadRampApprAssistStat_I 100;
BA_ "GenSigCycleTimeActive" SG_ 2566911243 Trailer5LoadRampApprAssistStat_I 100;
BA_ "GenSigStartValue" SG_ 2566911243 Trailer5LoadRampApprAssistStat_I 3;
BA_ "GenSigMaxLatency" SG_ 2566911243 Trailer5LoadRampApprAssistStat_I 1150;
BA_ "SystemSignalLongSymbol" SG_ 2566911243 Trailer5LoadRampApprAssistStat_I "Trailer5LoadRampApprAssistStat_ISig_3";
BA_ "GenSigCycleTime" SG_ 2566911243 Trailer5LevelControlStatus_ISig_ 100;
BA_ "GenSigCycleTimeActive" SG_ 2566911243 Trailer5LevelControlStatus_ISig_ 100;
BA_ "GenSigStartValue" SG_ 2566911243 Trailer5LevelControlStatus_ISig_ 3;
BA_ "GenSigMaxLatency" SG_ 2566911243 Trailer5LevelControlStatus_ISig_ 1150;
BA_ "SystemSignalLongSymbol" SG_ 2566911243 Trailer5LevelControlStatus_ISig_ "Trailer5LevelControlStatus_ISig_3";
BA_ "GenSigCycleTime" SG_ 2566911243 Trailer5ExtLvlStorageSupport_ISi 100;
BA_ "GenSigCycleTimeActive" SG_ 2566911243 Trailer5ExtLvlStorageSupport_ISi 100;
BA_ "GenSigStartValue" SG_ 2566911243 Trailer5ExtLvlStorageSupport_ISi 3;
BA_ "GenSigMaxLatency" SG_ 2566911243 Trailer5ExtLvlStorageSupport_ISi 1150;
BA_ "SystemSignalLongSymbol" SG_ 2566911243 Trailer5ExtLvlStorageSupport_ISi "Trailer5ExtLvlStorageSupport_ISig_3";
BA_ "GenSigCycleTime" SG_ 2566911243 Trailer5NomBodyLevel_RearLevel_I 100;
BA_ "GenSigCycleTimeActive" SG_ 2566911243 Trailer5NomBodyLevel_RearLevel_I 100;
BA_ "GenSigStartValue" SG_ 2566911243 Trailer5NomBodyLevel_RearLevel_I 65535;
BA_ "GenSigMaxLatency" SG_ 2566911243 Trailer5NomBodyLevel_RearLevel_I 1150;
BA_ "SystemSignalLongSymbol" SG_ 2566911243 Trailer5NomBodyLevel_RearLevel_I "Trailer5NomBodyLevel_RearLevel_ISig_3";
BA_ "GenSigCycleTime" SG_ 2566911243 Trailer5YCSystemStatus_ISig_3 100;
BA_ "GenSigCycleTimeActive" SG_ 2566911243 Trailer5YCSystemStatus_ISig_3 100;
BA_ "GenSigStartValue" SG_ 2566911243 Trailer5YCSystemStatus_ISig_3 3;
BA_ "GenSigMaxLatency" SG_ 2566911243 Trailer5YCSystemStatus_ISig_3 1150;
BA_ "GenSigCycleTime" SG_ 2566911243 Trailer5EBSAmberWarning_ISig_3 100;
BA_ "GenSigCycleTimeActive" SG_ 2566911243 Trailer5EBSAmberWarning_ISig_3 100;
BA_ "GenSigStartValue" SG_ 2566911243 Trailer5EBSAmberWarning_ISig_3 3;
BA_ "GenSigMaxLatency" SG_ 2566911243 Trailer5EBSAmberWarning_ISig_3 1150;
BA_ "GenSigCycleTime" SG_ 2566911243 Trailer5NomBodyLevel_FrontLevel_ 100;
BA_ "GenSigCycleTimeActive" SG_ 2566911243 Trailer5NomBodyLevel_FrontLevel_ 100;
BA_ "GenSigStartValue" SG_ 2566911243 Trailer5NomBodyLevel_FrontLevel_ 65535;
BA_ "GenSigMaxLatency" SG_ 2566911243 Trailer5NomBodyLevel_FrontLevel_ 1150;
BA_ "SystemSignalLongSymbol" SG_ 2566911243 Trailer5NomBodyLevel_FrontLevel_ "Trailer5NomBodyLevel_FrontLevel_ISig_3";
BA_REL_ "GenSigFirstTimeoutTime" BU_SG_REL_ IC3 SG_ 2566899694 DailyRestingTimeShift1_ISig_3 65535;
BA_REL_ "GenSigTimeoutTime" BU_SG_REL_ IC3 SG_ 2566899694 DailyRestingTimeShift1_ISig_3 65535;
BA_REL_ "GenSigFirstTimeoutTime" BU_SG_REL_ IC3 SG_ 2566899694 RestingPeriodFlagShift2_ISig_3 65535;
BA_REL_ "GenSigTimeoutTime" BU_SG_REL_ IC3 SG_ 2566899694 RestingPeriodFlagShift2_ISig_3 65535;
BA_REL_ "GenSigFirstTimeoutTime" BU_SG_REL_ IC3 SG_ 2566899694 DailyDrivingTimeShift4_ISig_3 65535;
BA_REL_ "GenSigTimeoutTime" BU_SG_REL_ IC3 SG_ 2566899694 DailyDrivingTimeShift4_ISig_3 65535;
BA_REL_ "GenSigFirstTimeoutTime" BU_SG_REL_ IC3 SG_ 2566899694 DailyDrivingPeriod_ISig_3 65535;
BA_REL_ "GenSigTimeoutTime" BU_SG_REL_ IC3 SG_ 2566899694 DailyDrivingPeriod_ISig_3 65535;
BA_REL_ "GenSigFirstTimeoutTime" BU_SG_REL_ IC3 SG_ 2566899694 DailyRestingTimeShift7_ISig_3 65535;
BA_REL_ "GenSigTimeoutTime" BU_SG_REL_ IC3 SG_ 2566899694 DailyRestingTimeShift7_ISig_3 65535;
BA_REL_ "GenSigFirstTimeoutTime" BU_SG_REL_ IC3 SG_ 2566899694 UnknownPeriodShift1_ISig_3 65535;
BA_REL_ "GenSigTimeoutTime" BU_SG_REL_ IC3 SG_ 2566899694 UnknownPeriodShift1_ISig_3 65535;
BA_REL_ "GenSigFirstTimeoutTime" BU_SG_REL_ IC3 SG_ 2566899694 RestingPeriodFlagShift1_ISig_3 65535;
BA_REL_ "GenSigTimeoutTime" BU_SG_REL_ IC3 SG_ 2566899694 RestingPeriodFlagShift1_ISig_3 65535;
BA_REL_ "GenSigFirstTimeoutTime" BU_SG_REL_ IC3 SG_ 2566899694 DailyDrivingTimeShift3_ISig_3 65535;
BA_REL_ "GenSigTimeoutTime" BU_SG_REL_ IC3 SG_ 2566899694 DailyDrivingTimeShift3_ISig_3 65535;
BA_REL_ "GenSigFirstTimeoutTime" BU_SG_REL_ IC3 SG_ 2566899694 DailyRestingTimeShift2_ISig_3 65535;
BA_REL_ "GenSigTimeoutTime" BU_SG_REL_ IC3 SG_ 2566899694 DailyRestingTimeShift2_ISig_3 65535;
BA_REL_ "GenSigFirstTimeoutTime" BU_SG_REL_ IC3 SG_ 2566899694 DailyRestingTimeShift3_ISig_3 65535;
BA_REL_ "GenSigTimeoutTime" BU_SG_REL_ IC3 SG_ 2566899694 DailyRestingTimeShift3_ISig_3 65535;
BA_REL_ "GenSigFirstTimeoutTime" BU_SG_REL_ IC3 SG_ 2566899694 UnknownPeriodShift2_ISig_3 65535;
BA_REL_ "GenSigTimeoutTime" BU_SG_REL_ IC3 SG_ 2566899694 UnknownPeriodShift2_ISig_3 65535;
BA_REL_ "GenSigFirstTimeoutTime" BU_SG_REL_ IC3 SG_ 2566899694 RestingPeriodFlag_ISig_3 65535;
BA_REL_ "GenSigTimeoutTime" BU_SG_REL_ IC3 SG_ 2566899694 RestingPeriodFlag_ISig_3 65535;
BA_REL_ "GenSigFirstTimeoutTime" BU_SG_REL_ IC3 SG_ 2566899694 TwoWeekTotalDrvingTime_ISig_3 65535;
BA_REL_ "GenSigTimeoutTime" BU_SG_REL_ IC3 SG_ 2566899694 TwoWeekTotalDrvingTime_ISig_3 65535;
BA_REL_ "GenSigFirstTimeoutTime" BU_SG_REL_ IC3 SG_ 2566899694 UnknownPeriodShift4_ISig_3 65535;
BA_REL_ "GenSigTimeoutTime" BU_SG_REL_ IC3 SG_ 2566899694 UnknownPeriodShift4_ISig_3 65535;
BA_REL_ "GenSigFirstTimeoutTime" BU_SG_REL_ IC3 SG_ 2566899694 DailyDrivingTimeShift2_ISig_3 65535;
BA_REL_ "GenSigTimeoutTime" BU_SG_REL_ IC3 SG_ 2566899694 DailyDrivingTimeShift2_ISig_3 65535;
BA_REL_ "GenSigFirstTimeoutTime" BU_SG_REL_ IC3 SG_ 2566899694 RestingPeriodFlagShift6_ISig_3 65535;
BA_REL_ "GenSigTimeoutTime" BU_SG_REL_ IC3 SG_ 2566899694 RestingPeriodFlagShift6_ISig_3 65535;
BA_REL_ "GenSigFirstTimeoutTime" BU_SG_REL_ IC3 SG_ 2566899694 DailyRestingTimeShift4_ISig_3 65535;
BA_REL_ "GenSigTimeoutTime" BU_SG_REL_ IC3 SG_ 2566899694 DailyRestingTimeShift4_ISig_3 65535;
BA_REL_ "GenSigFirstTimeoutTime" BU_SG_REL_ IC3 SG_ 2566899694 RestingPeriodFlagShift5_ISig_3 65535;
BA_REL_ "GenSigTimeoutTime" BU_SG_REL_ IC3 SG_ 2566899694 RestingPeriodFlagShift5_ISig_3 65535;
BA_REL_ "GenSigFirstTimeoutTime" BU_SG_REL_ IC3 SG_ 2566899694 RestingPeriodFlagShift3_ISig_3 65535;
BA_REL_ "GenSigTimeoutTime" BU_SG_REL_ IC3 SG_ 2566899694 RestingPeriodFlagShift3_ISig_3 65535;
BA_REL_ "GenSigFirstTimeoutTime" BU_SG_REL_ IC3 SG_ 2566899694 DailyDrivingTimeShift5_ISig_3 65535;
BA_REL_ "GenSigTimeoutTime" BU_SG_REL_ IC3 SG_ 2566899694 DailyDrivingTimeShift5_ISig_3 65535;
BA_REL_ "GenSigFirstTimeoutTime" BU_SG_REL_ IC3 SG_ 2566899694 DailyRestingTimeShift6_ISig_3 65535;
BA_REL_ "GenSigTimeoutTime" BU_SG_REL_ IC3 SG_ 2566899694 DailyRestingTimeShift6_ISig_3 65535;
BA_REL_ "GenSigFirstTimeoutTime" BU_SG_REL_ IC3 SG_ 2566899694 WeeklyTotalDrivingTime_ISig_3 65535;
BA_REL_ "GenSigTimeoutTime" BU_SG_REL_ IC3 SG_ 2566899694 WeeklyTotalDrivingTime_ISig_3 65535;
BA_REL_ "GenSigFirstTimeoutTime" BU_SG_REL_ IC3 SG_ 2566899694 UnknownPeriodShift7_ISig_3 65535;
BA_REL_ "GenSigTimeoutTime" BU_SG_REL_ IC3 SG_ 2566899694 UnknownPeriodShift7_ISig_3 65535;
BA_REL_ "GenSigFirstTimeoutTime" BU_SG_REL_ IC3 SG_ 2566899694 UnknownPeriodShift6_ISig_3 65535;
BA_REL_ "GenSigTimeoutTime" BU_SG_REL_ IC3 SG_ 2566899694 UnknownPeriodShift6_ISig_3 65535;
BA_REL_ "GenSigFirstTimeoutTime" BU_SG_REL_ IC3 SG_ 2566899694 DailyRestingTimeShift5_ISig_3 65535;
BA_REL_ "GenSigTimeoutTime" BU_SG_REL_ IC3 SG_ 2566899694 DailyRestingTimeShift5_ISig_3 65535;
BA_REL_ "GenSigFirstTimeoutTime" BU_SG_REL_ IC3 SG_ 2566899694 DailyDrivingTimeShift1_ISig_3 65535;
BA_REL_ "GenSigTimeoutTime" BU_SG_REL_ IC3 SG_ 2566899694 DailyDrivingTimeShift1_ISig_3 65535;
BA_REL_ "GenSigFirstTimeoutTime" BU_SG_REL_ IC3 SG_ 2566899694 UnknownPeriodShift3_ISig_3 65535;
BA_REL_ "GenSigTimeoutTime" BU_SG_REL_ IC3 SG_ 2566899694 UnknownPeriodShift3_ISig_3 65535;
BA_REL_ "GenSigFirstTimeoutTime" BU_SG_REL_ IC3 SG_ 2566899694 RestingPeriodFlagShift4_ISig_3 65535;
BA_REL_ "GenSigTimeoutTime" BU_SG_REL_ IC3 SG_ 2566899694 RestingPeriodFlagShift4_ISig_3 65535;
BA_REL_ "GenSigFirstTimeoutTime" BU_SG_REL_ IC3 SG_ 2566899694 DailyDrivingTimeShift6_ISig_3 65535;
BA_REL_ "GenSigTimeoutTime" BU_SG_REL_ IC3 SG_ 2566899694 DailyDrivingTimeShift6_ISig_3 65535;
BA_REL_ "GenSigFirstTimeoutTime" BU_SG_REL_ IC3 SG_ 2566899694 UnknownPeriodShift5_ISig_3 65535;
BA_REL_ "GenSigTimeoutTime" BU_SG_REL_ IC3 SG_ 2566899694 UnknownPeriodShift5_ISig_3 65535;
BA_REL_ "GenSigFirstTimeoutTime" BU_SG_REL_ VMCU SG_ 2566898926 Drvr1CumuBreakTime_Tacho 65000;
BA_REL_ "GenSigTimeoutTime" BU_SG_REL_ VMCU SG_ 2566898926 Drvr1CumuBreakTime_Tacho 60000;
BA_REL_ "GenSigFirstTimeoutTime" BU_SG_REL_ VMCU SG_ 2566898926 Drvr1CurDurSelectActy_Tacho 65000;
BA_REL_ "GenSigTimeoutTime" BU_SG_REL_ VMCU SG_ 2566898926 Drvr1CurDurSelectActy_Tacho 60000;
BA_REL_ "GenSigFirstTimeoutTime" BU_SG_REL_ VMCU SG_ 2566898926 Driver1CardUnload_Tacho 65000;
BA_REL_ "GenSigTimeoutTime" BU_SG_REL_ VMCU SG_ 2566898926 Driver1CardUnload_Tacho 60000;
BA_REL_ "GenSigFirstTimeoutTime" BU_SG_REL_ VMCU SG_ 2566898926 EndofLifeDriver1Card_Tacho 65000;
BA_REL_ "GenSigTimeoutTime" BU_SG_REL_ VMCU SG_ 2566898926 EndofLifeDriver1Card_Tacho 60000;
BA_REL_ "GenSigFirstTimeoutTime" BU_SG_REL_ VMCU SG_ 2566898926 DrawerState_Tacho 65000;
BA_REL_ "GenSigTimeoutTime" BU_SG_REL_ VMCU SG_ 2566898926 DrawerState_Tacho 60000;
BA_REL_ "GenSigFirstTimeoutTime" BU_SG_REL_ VMCU SG_ 2566898926 Drvr1ContinDrivingTime_Tacho 65000;
BA_REL_ "GenSigTimeoutTime" BU_SG_REL_ VMCU SG_ 2566898926 Drvr1ContinDrivingTime_Tacho 60000;
BA_REL_ "GenSigFirstTimeoutTime" BU_SG_REL_ VMCU SG_ 2566898670 NextCalibrationDateDay 65535;
BA_REL_ "GenSigTimeoutTime" BU_SG_REL_ VMCU SG_ 2566898670 NextCalibrationDateDay 65535;
BA_REL_ "GenSigFirstTimeoutTime" BU_SG_REL_ VMCU SG_ 2566898670 WVehicleCharacteristicFactor 65535;
BA_REL_ "GenSigTimeoutTime" BU_SG_REL_ VMCU SG_ 2566898670 WVehicleCharacteristicFactor 65535;
BA_REL_ "GenSigFirstTimeoutTime" BU_SG_REL_ VMCU SG_ 2566898670 NextCalibrationDateMonth 65535;
BA_REL_ "GenSigTimeoutTime" BU_SG_REL_ VMCU SG_ 2566898670 NextCalibrationDateMonth 65535;
BA_REL_ "GenSigFirstTimeoutTime" BU_SG_REL_ IC3 SG_ 2566898670 Driver1Identification_ISig_3 65535;
BA_REL_ "GenSigTimeoutTime" BU_SG_REL_ IC3 SG_ 2566898670 Driver1Identification_ISig_3 65535;
BA_REL_ "GenSigFirstTimeoutTime" BU_SG_REL_ CIOM SG_ 2566898670 Driver1Identification_ISig_3 65535;
BA_REL_ "GenSigTimeoutTime" BU_SG_REL_ CIOM SG_ 2566898670 Driver1Identification_ISig_3 65535;
BA_REL_ "GenSigFirstTimeoutTime" BU_SG_REL_ VMCU SG_ 2566898670 NextCalibrationDateYear 65535;
BA_REL_ "GenSigTimeoutTime" BU_SG_REL_ VMCU SG_ 2566898670 NextCalibrationDateYear 65535;
BA_REL_ "GenSigFirstTimeoutTime" BU_SG_REL_ TECU SG_ 2566759457 Pto2EnableSwitch 3000;
BA_REL_ "GenSigTimeoutTime" BU_SG_REL_ TECU SG_ 2566759457 Pto2EnableSwitch 600;
BA_REL_ "GenSigFirstTimeoutTime" BU_SG_REL_ TECU SG_ 2566759457 Pto1EnableSwitch 3000;
BA_REL_ "GenSigTimeoutTime" BU_SG_REL_ TECU SG_ 2566759457 Pto1EnableSwitch 600;
BA_REL_ "GenSigFirstTimeoutTime" BU_SG_REL_ VMCU SG_ 2566759427 Pto2EngagementConsent 3000;
BA_REL_ "GenSigTimeoutTime" BU_SG_REL_ VMCU SG_ 2566759427 Pto2EngagementConsent 600;
BA_REL_ "GenSigFirstTimeoutTime" BU_SG_REL_ VMCU SG_ 2566759427 Pto1EngagementConsent 3000;
BA_REL_ "GenSigTimeoutTime" BU_SG_REL_ VMCU SG_ 2566759427 Pto1EngagementConsent 600;
BA_REL_ "GenSigFirstTimeoutTime" BU_SG_REL_ CIOM SG_ 2566844928 InstantaneousFuelEconomy_ISig_3 3000;
BA_REL_ "GenSigTimeoutTime" BU_SG_REL_ CIOM SG_ 2566844928 InstantaneousFuelEconomy_ISig_3 600;
BA_REL_ "GenSigFirstTimeoutTime" BU_SG_REL_ IC3 SG_ 2566844928 InstantaneousFuelEconomy_ISig_3 3000;
BA_REL_ "GenSigTimeoutTime" BU_SG_REL_ IC3 SG_ 2566844928 InstantaneousFuelEconomy_ISig_3 600;
BA_REL_ "GenSigFirstTimeoutTime" BU_SG_REL_ BBM SG_ 2566844928 EngineFuelRate_ISig_3 3000;
BA_REL_ "GenSigTimeoutTime" BU_SG_REL_ BBM SG_ 2566844928 EngineFuelRate_ISig_3 600;
BA_REL_ "GenSigFirstTimeoutTime" BU_SG_REL_ VMCU SG_ 2566844928 EngineFuelRate_ISig_3 3000;
BA_REL_ "GenSigTimeoutTime" BU_SG_REL_ VMCU SG_ 2566844928 EngineFuelRate_ISig_3 600;
BA_REL_ "GenSigFirstTimeoutTime" BU_SG_REL_ IC3 SG_ 2566844928 EngineFuelRate_ISig_3 3000;
BA_REL_ "GenSigTimeoutTime" BU_SG_REL_ IC3 SG_ 2566844928 EngineFuelRate_ISig_3 600;
BA_REL_ "GenSigFirstTimeoutTime" BU_SG_REL_ CIOM SG_ 2566844928 EngineFuelRate_ISig_3 3000;
BA_REL_ "GenSigTimeoutTime" BU_SG_REL_ CIOM SG_ 2566844928 EngineFuelRate_ISig_3 600;
BA_REL_ "GenSigFirstTimeoutTime" BU_SG_REL_ DACU SG_ 2566799590 RearFogLights_ISig_3 3000;
BA_REL_ "GenSigTimeoutTime" BU_SG_REL_ DACU SG_ 2566799590 RearFogLights_ISig_3 600;
BA_REL_ "GenSigFirstTimeoutTime" BU_SG_REL_ DACU SG_ 2566799590 LowBeamHeadLightData_ISig_3 3000;
BA_REL_ "GenSigTimeoutTime" BU_SG_REL_ DACU SG_ 2566799590 LowBeamHeadLightData_ISig_3 600;
BA_REL_ "GenSigFirstTimeoutTime" BU_SG_REL_ IC3 SG_ 2566825472 EngineTurbo1BoostPressure 12000;
BA_REL_ "GenSigTimeoutTime" BU_SG_REL_ IC3 SG_ 2566825472 EngineTurbo1BoostPressure 3000;
BA_REL_ "GenSigFirstTimeoutTime" BU_SG_REL_ ACM SG_ 2566825472 EngineTurbo1BoostPressure 12000;
BA_REL_ "GenSigTimeoutTime" BU_SG_REL_ ACM SG_ 2566825472 EngineTurbo1BoostPressure 3000;
BA_REL_ "GenSigFirstTimeoutTime" BU_SG_REL_ VMCU SG_ 2566896663 OBDRelDTC_IC_DtcIdA 12000;
BA_REL_ "GenSigTimeoutTime" BU_SG_REL_ VMCU SG_ 2566896663 OBDRelDTC_IC_DtcIdA 3000;
BA_REL_ "GenSigFirstTimeoutTime" BU_SG_REL_ VMCU SG_ 2566896663 OBDRelDTC_IC_DtcIdB 12000;
BA_REL_ "GenSigTimeoutTime" BU_SG_REL_ VMCU SG_ 2566896663 OBDRelDTC_IC_DtcIdB 3000;
BA_REL_ "GenSigFirstTimeoutTime" BU_SG_REL_ VMCU SG_ 2566896663 OBDRelDTC_IC_EvalStatA 12000;
BA_REL_ "GenSigTimeoutTime" BU_SG_REL_ VMCU SG_ 2566896663 OBDRelDTC_IC_EvalStatA 3000;
BA_REL_ "GenSigFirstTimeoutTime" BU_SG_REL_ VMCU SG_ 2566896663 OBDRelDTC_IC_EvalResultA 12000;
BA_REL_ "GenSigTimeoutTime" BU_SG_REL_ VMCU SG_ 2566896663 OBDRelDTC_IC_EvalResultA 3000;
BA_REL_ "GenSigFirstTimeoutTime" BU_SG_REL_ VMCU SG_ 2566896663 OBDRelDTC_IC_EvalResultB 12000;
BA_REL_ "GenSigTimeoutTime" BU_SG_REL_ VMCU SG_ 2566896663 OBDRelDTC_IC_EvalResultB 3000;
BA_REL_ "GenSigFirstTimeoutTime" BU_SG_REL_ VMCU SG_ 2566896663 OBDRelDTC_IC_EvalStatB 12000;
BA_REL_ "GenSigTimeoutTime" BU_SG_REL_ VMCU SG_ 2566896663 OBDRelDTC_IC_EvalStatB 3000;
BA_REL_ "GenSigFirstTimeoutTime" BU_SG_REL_ VMCU SG_ 2566896663 OBDRelDTC_IC_FailTB 12000;
BA_REL_ "GenSigTimeoutTime" BU_SG_REL_ VMCU SG_ 2566896663 OBDRelDTC_IC_FailTB 3000;
BA_REL_ "GenSigFirstTimeoutTime" BU_SG_REL_ VMCU SG_ 2566896663 OBDRelDTC_IC_DrvngCycleB 12000;
BA_REL_ "GenSigTimeoutTime" BU_SG_REL_ VMCU SG_ 2566896663 OBDRelDTC_IC_DrvngCycleB 3000;
BA_REL_ "GenSigFirstTimeoutTime" BU_SG_REL_ VMCU SG_ 2566896663 OBDRelDTC_IC_DrvngCycleA 12000;
BA_REL_ "GenSigTimeoutTime" BU_SG_REL_ VMCU SG_ 2566896663 OBDRelDTC_IC_DrvngCycleA 3000;
BA_REL_ "GenSigFirstTimeoutTime" BU_SG_REL_ VMCU SG_ 2566896663 OBDRelDTC_IC_FailTA 12000;
BA_REL_ "GenSigTimeoutTime" BU_SG_REL_ VMCU SG_ 2566896663 OBDRelDTC_IC_FailTA 3000;
BA_REL_ "GenSigFirstTimeoutTime" BU_SG_REL_ TECU SG_ 2566896407 AWBEnableRequest 12000;
BA_REL_ "GenSigTimeoutTime" BU_SG_REL_ TECU SG_ 2566896407 AWBEnableRequest 3000;
BA_REL_ "GenSigFirstTimeoutTime" BU_SG_REL_ EMS SG_ 2566896407 AWBEnableRequest 12000;
BA_REL_ "GenSigTimeoutTime" BU_SG_REL_ EMS SG_ 2566896407 AWBEnableRequest 3000;
BA_REL_ "GenSigFirstTimeoutTime" BU_SG_REL_ CIOM SG_ 2566896407 CCtrlRemActTmpOpRqst_Temp_ISig_3 12000;
BA_REL_ "GenSigTimeoutTime" BU_SG_REL_ CIOM SG_ 2566896407 CCtrlRemActTmpOpRqst_Temp_ISig_3 3000;
BA_REL_ "GenSigFirstTimeoutTime" BU_SG_REL_ VMCU SG_ 2566896407 LoadCargoTare_rqst 12000;
BA_REL_ "GenSigTimeoutTime" BU_SG_REL_ VMCU SG_ 2566896407 LoadCargoTare_rqst 3000;
BA_REL_ "GenSigFirstTimeoutTime" BU_SG_REL_ VMCU SG_ 2566896407 DeleteLoadCalib 12000;
BA_REL_ "GenSigTimeoutTime" BU_SG_REL_ VMCU SG_ 2566896407 DeleteLoadCalib 3000;
BA_REL_ "GenSigFirstTimeoutTime" BU_SG_REL_ CIOM SG_ 2566896407 CCtrlRemActTmpOpRqst_Act_ISig_3 12000;
BA_REL_ "GenSigTimeoutTime" BU_SG_REL_ CIOM SG_ 2566896407 CCtrlRemActTmpOpRqst_Act_ISig_3 3000;
BA_REL_ "GenSigFirstTimeoutTime" BU_SG_REL_ EMS SG_ 2566892452 OBDGWLogHeartBeat_MsgCounter_ISi 65535;
BA_REL_ "GenSigTimeoutTime" BU_SG_REL_ EMS SG_ 2566892452 OBDGWLogHeartBeat_MsgCounter_ISi 65535;
BA_REL_ "GenSigFirstTimeoutTime" BU_SG_REL_ EMS SG_ 2566892452 OBDGWLogHeartBeat_Data1_ISig_3 65535;
BA_REL_ "GenSigTimeoutTime" BU_SG_REL_ EMS SG_ 2566892452 OBDGWLogHeartBeat_Data1_ISig_3 65535;
BA_REL_ "GenSigFirstTimeoutTime" BU_SG_REL_ EMS SG_ 2566892452 OBDGWLogHeartBeat_Data0_ISig_3 65535;
BA_REL_ "GenSigTimeoutTime" BU_SG_REL_ EMS SG_ 2566892452 OBDGWLogHeartBeat_Data0_ISig_3 65535;
BA_REL_ "GenSigFirstTimeoutTime" BU_SG_REL_ EMS SG_ 2566892452 OBDGWLogHeartBeat_Data4_ISig_3 65535;
BA_REL_ "GenSigTimeoutTime" BU_SG_REL_ EMS SG_ 2566892452 OBDGWLogHeartBeat_Data4_ISig_3 65535;
BA_REL_ "GenSigFirstTimeoutTime" BU_SG_REL_ EMS SG_ 2566892452 OBDGWLogHeartBeat_Data2_ISig_3 65535;
BA_REL_ "GenSigTimeoutTime" BU_SG_REL_ EMS SG_ 2566892452 OBDGWLogHeartBeat_Data2_ISig_3 65535;
BA_REL_ "GenSigFirstTimeoutTime" BU_SG_REL_ EMS SG_ 2566892452 OBDGWLogHeartBeat_Data5_ISig_3 65535;
BA_REL_ "GenSigTimeoutTime" BU_SG_REL_ EMS SG_ 2566892452 OBDGWLogHeartBeat_Data5_ISig_3 65535;
BA_REL_ "GenSigFirstTimeoutTime" BU_SG_REL_ EMS SG_ 2566892452 OBDGWLogHeartBeat_Data3_ISig_3 65535;
BA_REL_ "GenSigTimeoutTime" BU_SG_REL_ EMS SG_ 2566892452 OBDGWLogHeartBeat_Data3_ISig_3 65535;
BA_REL_ "GenSigFirstTimeoutTime" BU_SG_REL_ EMS SG_ 2566892452 OBDGWLogHeartBeat_MsgChecksum_IS 65535;
BA_REL_ "GenSigTimeoutTime" BU_SG_REL_ EMS SG_ 2566892452 OBDGWLogHeartBeat_MsgChecksum_IS 65535;
BA_REL_ "GenSigFirstTimeoutTime" BU_SG_REL_ EMS SG_ 2566892452 OBDGWLogHeartBeat_Data6_ISig_3 65535;
BA_REL_ "GenSigTimeoutTime" BU_SG_REL_ EMS SG_ 2566892452 OBDGWLogHeartBeat_Data6_ISig_3 65535;
BA_REL_ "GenSigFirstTimeoutTime" BU_SG_REL_ VMCU SG_ 2298372875 FrontAxleRightWheelSpeed_ISig_3 3000;
BA_REL_ "GenSigTimeoutTime" BU_SG_REL_ VMCU SG_ 2298372875 FrontAxleRightWheelSpeed_ISig_3 120;
BA_REL_ "GenSigFirstTimeoutTime" BU_SG_REL_ BBM SG_ 2298372875 FrontAxleRightWheelSpeed_ISig_3 3000;
BA_REL_ "GenSigTimeoutTime" BU_SG_REL_ BBM SG_ 2298372875 FrontAxleRightWheelSpeed_ISig_3 120;
BA_REL_ "GenSigFirstTimeoutTime" BU_SG_REL_ DACU SG_ 2298372875 FrontAxleRightWheelSpeed_ISig_3 3000;
BA_REL_ "GenSigTimeoutTime" BU_SG_REL_ DACU SG_ 2298372875 FrontAxleRightWheelSpeed_ISig_3 120;
BA_REL_ "GenSigFirstTimeoutTime" BU_SG_REL_ TECU SG_ 2298372875 FrontAxleRightWheelSpeed_ISig_3 3000;
BA_REL_ "GenSigTimeoutTime" BU_SG_REL_ TECU SG_ 2298372875 FrontAxleRightWheelSpeed_ISig_3 120;
BA_REL_ "GenSigFirstTimeoutTime" BU_SG_REL_ IC3 SG_ 2298372875 FrontAxleRightWheelSpeed_ISig_3 3000;
BA_REL_ "GenSigTimeoutTime" BU_SG_REL_ IC3 SG_ 2298372875 FrontAxleRightWheelSpeed_ISig_3 120;
BA_REL_ "GenSigFirstTimeoutTime" BU_SG_REL_ BBM SG_ 2298372875 RearAxleLeftWheelSpeed_ISig_3 3000;
BA_REL_ "GenSigTimeoutTime" BU_SG_REL_ BBM SG_ 2298372875 RearAxleLeftWheelSpeed_ISig_3 120;
BA_REL_ "GenSigFirstTimeoutTime" BU_SG_REL_ VMCU SG_ 2298372875 RearAxleLeftWheelSpeed_ISig_3 3000;
BA_REL_ "GenSigTimeoutTime" BU_SG_REL_ VMCU SG_ 2298372875 RearAxleLeftWheelSpeed_ISig_3 120;
BA_REL_ "GenSigFirstTimeoutTime" BU_SG_REL_ TECU SG_ 2298372875 RearAxleLeftWheelSpeed_ISig_3 3000;
BA_REL_ "GenSigTimeoutTime" BU_SG_REL_ TECU SG_ 2298372875 RearAxleLeftWheelSpeed_ISig_3 120;
BA_REL_ "GenSigFirstTimeoutTime" BU_SG_REL_ DACU SG_ 2298372875 RearAxleLeftWheelSpeed_ISig_3 3000;
BA_REL_ "GenSigTimeoutTime" BU_SG_REL_ DACU SG_ 2298372875 RearAxleLeftWheelSpeed_ISig_3 120;
BA_REL_ "GenSigFirstTimeoutTime" BU_SG_REL_ IC3 SG_ 2298372875 RearAxleLeftWheelSpeed_ISig_3 3000;
BA_REL_ "GenSigTimeoutTime" BU_SG_REL_ IC3 SG_ 2298372875 RearAxleLeftWheelSpeed_ISig_3 120;
BA_REL_ "GenSigFirstTimeoutTime" BU_SG_REL_ BBM SG_ 2298372875 RearAxleRightWheelSpeed_ISig_3 3000;
BA_REL_ "GenSigTimeoutTime" BU_SG_REL_ BBM SG_ 2298372875 RearAxleRightWheelSpeed_ISig_3 120;
BA_REL_ "GenSigFirstTimeoutTime" BU_SG_REL_ VMCU SG_ 2298372875 RearAxleRightWheelSpeed_ISig_3 3000;
BA_REL_ "GenSigTimeoutTime" BU_SG_REL_ VMCU SG_ 2298372875 RearAxleRightWheelSpeed_ISig_3 120;
BA_REL_ "GenSigFirstTimeoutTime" BU_SG_REL_ TECU SG_ 2298372875 RearAxleRightWheelSpeed_ISig_3 3000;
BA_REL_ "GenSigTimeoutTime" BU_SG_REL_ TECU SG_ 2298372875 RearAxleRightWheelSpeed_ISig_3 120;
BA_REL_ "GenSigFirstTimeoutTime" BU_SG_REL_ DACU SG_ 2298372875 RearAxleRightWheelSpeed_ISig_3 3000;
BA_REL_ "GenSigTimeoutTime" BU_SG_REL_ DACU SG_ 2298372875 RearAxleRightWheelSpeed_ISig_3 120;
BA_REL_ "GenSigFirstTimeoutTime" BU_SG_REL_ IC3 SG_ 2298372875 RearAxleRightWheelSpeed_ISig_3 3000;
BA_REL_ "GenSigTimeoutTime" BU_SG_REL_ IC3 SG_ 2298372875 RearAxleRightWheelSpeed_ISig_3 120;
BA_REL_ "GenSigFirstTimeoutTime" BU_SG_REL_ TECU SG_ 2298372875 FrontAxleLeftWheelSpeed_ISig_3 3000;
BA_REL_ "GenSigTimeoutTime" BU_SG_REL_ TECU SG_ 2298372875 FrontAxleLeftWheelSpeed_ISig_3 120;
BA_REL_ "GenSigFirstTimeoutTime" BU_SG_REL_ IC3 SG_ 2298372875 FrontAxleLeftWheelSpeed_ISig_3 3000;
BA_REL_ "GenSigTimeoutTime" BU_SG_REL_ IC3 SG_ 2298372875 FrontAxleLeftWheelSpeed_ISig_3 120;
BA_REL_ "GenSigFirstTimeoutTime" BU_SG_REL_ DACU SG_ 2298372875 FrontAxleLeftWheelSpeed_ISig_3 3000;
BA_REL_ "GenSigTimeoutTime" BU_SG_REL_ DACU SG_ 2298372875 FrontAxleLeftWheelSpeed_ISig_3 120;
BA_REL_ "GenSigFirstTimeoutTime" BU_SG_REL_ BBM SG_ 2298372875 FrontAxleLeftWheelSpeed_ISig_3 3000;
BA_REL_ "GenSigTimeoutTime" BU_SG_REL_ BBM SG_ 2298372875 FrontAxleLeftWheelSpeed_ISig_3 120;
BA_REL_ "GenSigFirstTimeoutTime" BU_SG_REL_ VMCU SG_ 2298372875 FrontAxleLeftWheelSpeed_ISig_3 3000;
BA_REL_ "GenSigTimeoutTime" BU_SG_REL_ VMCU SG_ 2298372875 FrontAxleLeftWheelSpeed_ISig_3 120;
BA_REL_ "GenSigFirstTimeoutTime" BU_SG_REL_ IC3 SG_ 2566719744 HighResEngineTotalFuelUsed_ISig_ 24000;
BA_REL_ "GenSigTimeoutTime" BU_SG_REL_ IC3 SG_ 2566719744 HighResEngineTotalFuelUsed_ISig_ 6000;
BA_REL_ "GenSigFirstTimeoutTime" BU_SG_REL_ BBM SG_ 2566719744 HighResEngineTotalFuelUsed_ISig_ 24000;
BA_REL_ "GenSigTimeoutTime" BU_SG_REL_ BBM SG_ 2566719744 HighResEngineTotalFuelUsed_ISig_ 6000;
BA_REL_ "GenSigFirstTimeoutTime" BU_SG_REL_ CIOM SG_ 2566719744 HighResEngineTotalFuelUsed_ISig_ 24000;
BA_REL_ "GenSigTimeoutTime" BU_SG_REL_ CIOM SG_ 2566719744 HighResEngineTotalFuelUsed_ISig_ 6000;
BA_REL_ "GenSigFirstTimeoutTime" BU_SG_REL_ IC3 SG_ 2566841600 EngineRevolutions_ISig_3 65000;
BA_REL_ "GenSigTimeoutTime" BU_SG_REL_ IC3 SG_ 2566841600 EngineRevolutions_ISig_3 30000;
BA_REL_ "GenSigFirstTimeoutTime" BU_SG_REL_ CIOM SG_ 2566749463 FMS1_TellTaleStatus4_ISig_3 24000;
BA_REL_ "GenSigTimeoutTime" BU_SG_REL_ CIOM SG_ 2566749463 FMS1_TellTaleStatus4_ISig_3 6000;
BA_REL_ "GenSigFirstTimeoutTime" BU_SG_REL_ CIOM SG_ 2566749463 FMS1_TellTaleStatus10_ISig_3 24000;
BA_REL_ "GenSigTimeoutTime" BU_SG_REL_ CIOM SG_ 2566749463 FMS1_TellTaleStatus10_ISig_3 6000;
BA_REL_ "GenSigFirstTimeoutTime" BU_SG_REL_ CIOM SG_ 2566749463 FMS1_TellTaleStatus6_ISig_3 24000;
BA_REL_ "GenSigTimeoutTime" BU_SG_REL_ CIOM SG_ 2566749463 FMS1_TellTaleStatus6_ISig_3 6000;
BA_REL_ "GenSigFirstTimeoutTime" BU_SG_REL_ CIOM SG_ 2566749463 FMS1_TellTaleStatus8_ISig_3 24000;
BA_REL_ "GenSigTimeoutTime" BU_SG_REL_ CIOM SG_ 2566749463 FMS1_TellTaleStatus8_ISig_3 6000;
BA_REL_ "GenSigFirstTimeoutTime" BU_SG_REL_ CIOM SG_ 2566749463 FMS1_TellTaleStatus5_ISig_3 24000;
BA_REL_ "GenSigTimeoutTime" BU_SG_REL_ CIOM SG_ 2566749463 FMS1_TellTaleStatus5_ISig_3 6000;
BA_REL_ "GenSigFirstTimeoutTime" BU_SG_REL_ CIOM SG_ 2566749463 FMS1_TellTaleStatus12_ISig_3 24000;
BA_REL_ "GenSigTimeoutTime" BU_SG_REL_ CIOM SG_ 2566749463 FMS1_TellTaleStatus12_ISig_3 6000;
BA_REL_ "GenSigFirstTimeoutTime" BU_SG_REL_ CIOM SG_ 2566749463 FMS1_Blockid_ISig_3 24000;
BA_REL_ "GenSigTimeoutTime" BU_SG_REL_ CIOM SG_ 2566749463 FMS1_Blockid_ISig_3 6000;
BA_REL_ "GenSigFirstTimeoutTime" BU_SG_REL_ CIOM SG_ 2566749463 FMS1_TellTaleStatus14_ISig_3 24000;
BA_REL_ "GenSigTimeoutTime" BU_SG_REL_ CIOM SG_ 2566749463 FMS1_TellTaleStatus14_ISig_3 6000;
BA_REL_ "GenSigFirstTimeoutTime" BU_SG_REL_ CIOM SG_ 2566749463 FMS1_TellTaleStatus1_ISig_3 24000;
BA_REL_ "GenSigTimeoutTime" BU_SG_REL_ CIOM SG_ 2566749463 FMS1_TellTaleStatus1_ISig_3 6000;
BA_REL_ "GenSigFirstTimeoutTime" BU_SG_REL_ CIOM SG_ 2566749463 FMS1_TellTaleStatus2_ISig_3 24000;
BA_REL_ "GenSigTimeoutTime" BU_SG_REL_ CIOM SG_ 2566749463 FMS1_TellTaleStatus2_ISig_3 6000;
BA_REL_ "GenSigFirstTimeoutTime" BU_SG_REL_ CIOM SG_ 2566749463 FMS1_TellTaleStatus11_ISig_3 24000;
BA_REL_ "GenSigTimeoutTime" BU_SG_REL_ CIOM SG_ 2566749463 FMS1_TellTaleStatus11_ISig_3 6000;
BA_REL_ "GenSigFirstTimeoutTime" BU_SG_REL_ CIOM SG_ 2566749463 FMS1_TellTaleStatus15_ISig_3 24000;
BA_REL_ "GenSigTimeoutTime" BU_SG_REL_ CIOM SG_ 2566749463 FMS1_TellTaleStatus15_ISig_3 6000;
BA_REL_ "GenSigFirstTimeoutTime" BU_SG_REL_ CIOM SG_ 2566749463 FMS1_TellTaleStatus3_ISig_3 24000;
BA_REL_ "GenSigTimeoutTime" BU_SG_REL_ CIOM SG_ 2566749463 FMS1_TellTaleStatus3_ISig_3 6000;
BA_REL_ "GenSigFirstTimeoutTime" BU_SG_REL_ CIOM SG_ 2566749463 FMS1_TellTaleStatus13_ISig_3 24000;
BA_REL_ "GenSigTimeoutTime" BU_SG_REL_ CIOM SG_ 2566749463 FMS1_TellTaleStatus13_ISig_3 6000;
BA_REL_ "GenSigFirstTimeoutTime" BU_SG_REL_ CIOM SG_ 2566749463 FMS1_TellTaleStatus9_ISig_3 24000;
BA_REL_ "GenSigTimeoutTime" BU_SG_REL_ CIOM SG_ 2566749463 FMS1_TellTaleStatus9_ISig_3 6000;
BA_REL_ "GenSigFirstTimeoutTime" BU_SG_REL_ CIOM SG_ 2566749463 FMS1_TellTaleStatus7_ISig_3 24000;
BA_REL_ "GenSigTimeoutTime" BU_SG_REL_ CIOM SG_ 2566749463 FMS1_TellTaleStatus7_ISig_3 6000;
BA_REL_ "GenSigFirstTimeoutTime" BU_SG_REL_ VMCU SG_ 2566801923 TransmEngineCrankEnable2_ISig_3 3000;
BA_REL_ "GenSigTimeoutTime" BU_SG_REL_ VMCU SG_ 2566801923 TransmEngineCrankEnable2_ISig_3 600;
BA_REL_ "GenSigFirstTimeoutTime" BU_SG_REL_ BBM SG_ 2565866755 TransmissionActualGearRatio_ISig 3000;
BA_REL_ "GenSigTimeoutTime" BU_SG_REL_ BBM SG_ 2565866755 TransmissionActualGearRatio_ISig 600;
BA_REL_ "GenSigFirstTimeoutTime" BU_SG_REL_ DACU SG_ 2565866755 TransmissionActualGearRatio_ISig 3000;
BA_REL_ "GenSigTimeoutTime" BU_SG_REL_ DACU SG_ 2565866755 TransmissionActualGearRatio_ISig 600;
BA_REL_ "GenSigFirstTimeoutTime" BU_SG_REL_ EMS SG_ 2565866755 TransmissionActualGearRatio_ISig 3000;
BA_REL_ "GenSigTimeoutTime" BU_SG_REL_ EMS SG_ 2565866755 TransmissionActualGearRatio_ISig 600;
BA_REL_ "GenSigFirstTimeoutTime" BU_SG_REL_ VMCU SG_ 2565866755 TransmissionActualGearRatio_ISig 3000;
BA_REL_ "GenSigTimeoutTime" BU_SG_REL_ VMCU SG_ 2565866755 TransmissionActualGearRatio_ISig 600;
BA_REL_ "GenSigFirstTimeoutTime" BU_SG_REL_ EMS SG_ 2565866755 TransmissionCurrentGear_ISig_3 3000;
BA_REL_ "GenSigTimeoutTime" BU_SG_REL_ EMS SG_ 2565866755 TransmissionCurrentGear_ISig_3 600;
BA_REL_ "GenSigFirstTimeoutTime" BU_SG_REL_ BBM SG_ 2565866755 TransmissionCurrentGear_ISig_3 3000;
BA_REL_ "GenSigTimeoutTime" BU_SG_REL_ BBM SG_ 2565866755 TransmissionCurrentGear_ISig_3 600;
BA_REL_ "GenSigFirstTimeoutTime" BU_SG_REL_ VMCU SG_ 2565866755 TransmissionCurrentGear_ISig_3 3000;
BA_REL_ "GenSigTimeoutTime" BU_SG_REL_ VMCU SG_ 2565866755 TransmissionCurrentGear_ISig_3 600;
BA_REL_ "GenSigFirstTimeoutTime" BU_SG_REL_ EBS SG_ 2565866755 TransmissionCurrentGear_ISig_3 3000;
BA_REL_ "GenSigTimeoutTime" BU_SG_REL_ EBS SG_ 2565866755 TransmissionCurrentGear_ISig_3 600;
BA_REL_ "GenSigFirstTimeoutTime" BU_SG_REL_ IC3 SG_ 2565866755 TransmissionCurrentGear_ISig_3 3000;
BA_REL_ "GenSigTimeoutTime" BU_SG_REL_ IC3 SG_ 2565866755 TransmissionCurrentGear_ISig_3 600;
BA_REL_ "GenSigFirstTimeoutTime" BU_SG_REL_ DACU SG_ 2565866755 TransmissionCurrentGear_ISig_3 3000;
BA_REL_ "GenSigTimeoutTime" BU_SG_REL_ DACU SG_ 2565866755 TransmissionCurrentGear_ISig_3 600;
BA_REL_ "GenSigFirstTimeoutTime" BU_SG_REL_ VMCU SG_ 2565866755 TransmissionRangeSelected_ISig_3 3000;
BA_REL_ "GenSigTimeoutTime" BU_SG_REL_ VMCU SG_ 2565866755 TransmissionRangeSelected_ISig_3 600;
BA_REL_ "GenSigFirstTimeoutTime" BU_SG_REL_ IC3 SG_ 2565866755 TransmissionRangeSelected_ISig_3 3000;
BA_REL_ "GenSigTimeoutTime" BU_SG_REL_ IC3 SG_ 2565866755 TransmissionRangeSelected_ISig_3 600;
BA_REL_ "GenSigFirstTimeoutTime" BU_SG_REL_ BBM SG_ 2565866755 TransmissionRangeSelected_ISig_3 3000;
BA_REL_ "GenSigTimeoutTime" BU_SG_REL_ BBM SG_ 2565866755 TransmissionRangeSelected_ISig_3 600;
BA_REL_ "GenSigFirstTimeoutTime" BU_SG_REL_ BBM SG_ 2565866755 TransmissionRangeAttained_ISig_3 3000;
BA_REL_ "GenSigTimeoutTime" BU_SG_REL_ BBM SG_ 2565866755 TransmissionRangeAttained_ISig_3 600;
BA_REL_ "GenSigFirstTimeoutTime" BU_SG_REL_ IC3 SG_ 2565866755 TransmissionRangeAttained_ISig_3 3000;
BA_REL_ "GenSigTimeoutTime" BU_SG_REL_ IC3 SG_ 2565866755 TransmissionRangeAttained_ISig_3 600;
BA_REL_ "GenSigFirstTimeoutTime" BU_SG_REL_ EMS SG_ 2565866755 TransmissionSelectedGear_ISig_3 3000;
BA_REL_ "GenSigTimeoutTime" BU_SG_REL_ EMS SG_ 2565866755 TransmissionSelectedGear_ISig_3 600;
BA_REL_ "GenSigFirstTimeoutTime" BU_SG_REL_ BBM SG_ 2565866755 TransmissionSelectedGear_ISig_3 3000;
BA_REL_ "GenSigTimeoutTime" BU_SG_REL_ BBM SG_ 2565866755 TransmissionSelectedGear_ISig_3 600;
BA_REL_ "GenSigFirstTimeoutTime" BU_SG_REL_ IC3 SG_ 2565866755 TransmissionSelectedGear_ISig_3 3000;
BA_REL_ "GenSigTimeoutTime" BU_SG_REL_ IC3 SG_ 2565866755 TransmissionSelectedGear_ISig_3 600;
BA_REL_ "GenSigFirstTimeoutTime" BU_SG_REL_ VMCU SG_ 2565866755 TransmissionSelectedGear_ISig_3 3000;
BA_REL_ "GenSigTimeoutTime" BU_SG_REL_ VMCU SG_ 2565866755 TransmissionSelectedGear_ISig_3 600;
BA_REL_ "GenSigFirstTimeoutTime" BU_SG_REL_ EBS SG_ 2364539395 PercentClutchSlip_ISig_3 3000;
BA_REL_ "GenSigTimeoutTime" BU_SG_REL_ EBS SG_ 2364539395 PercentClutchSlip_ISig_3 60;
BA_REL_ "GenSigFirstTimeoutTime" BU_SG_REL_ EMS SG_ 2364539395 PercentClutchSlip_ISig_3 3000;
BA_REL_ "GenSigTimeoutTime" BU_SG_REL_ EMS SG_ 2364539395 PercentClutchSlip_ISig_3 60;
BA_REL_ "GenSigFirstTimeoutTime" BU_SG_REL_ VMCU SG_ 2364539395 PercentClutchSlip_ISig_3 3000;
BA_REL_ "GenSigTimeoutTime" BU_SG_REL_ VMCU SG_ 2364539395 PercentClutchSlip_ISig_3 60;
BA_REL_ "GenSigFirstTimeoutTime" BU_SG_REL_ BBM SG_ 2364539395 PercentClutchSlip_ISig_3 3000;
BA_REL_ "GenSigTimeoutTime" BU_SG_REL_ BBM SG_ 2364539395 PercentClutchSlip_ISig_3 60;
BA_REL_ "GenSigFirstTimeoutTime" BU_SG_REL_ VMCU SG_ 2364539395 TransmissionOutputShaftSpeed2 3000;
BA_REL_ "GenSigTimeoutTime" BU_SG_REL_ VMCU SG_ 2364539395 TransmissionOutputShaftSpeed2 60;
BA_REL_ "GenSigFirstTimeoutTime" BU_SG_REL_ VMCU SG_ 2364539395 TransmTrqConvrtrLockupEngd_ISig_ 3000;
BA_REL_ "GenSigTimeoutTime" BU_SG_REL_ VMCU SG_ 2364539395 TransmTrqConvrtrLockupEngd_ISig_ 60;
BA_REL_ "GenSigFirstTimeoutTime" BU_SG_REL_ EMS SG_ 2364539395 TransmTrqConvrtrLockupEngd_ISig_ 3000;
BA_REL_ "GenSigTimeoutTime" BU_SG_REL_ EMS SG_ 2364539395 TransmTrqConvrtrLockupEngd_ISig_ 60;
BA_REL_ "GenSigFirstTimeoutTime" BU_SG_REL_ BBM SG_ 2364539395 TransmTrqConvrtrLockupEngd_ISig_ 3000;
BA_REL_ "GenSigTimeoutTime" BU_SG_REL_ BBM SG_ 2364539395 TransmTrqConvrtrLockupEngd_ISig_ 60;
BA_REL_ "GenSigFirstTimeoutTime" BU_SG_REL_ EMS SG_ 2364539395 TransmissionDrivelineEngaged_ISi 3000;
BA_REL_ "GenSigTimeoutTime" BU_SG_REL_ EMS SG_ 2364539395 TransmissionDrivelineEngaged_ISi 60;
BA_REL_ "GenSigFirstTimeoutTime" BU_SG_REL_ VMCU SG_ 2364539395 TransmissionDrivelineEngaged_ISi 3000;
BA_REL_ "GenSigTimeoutTime" BU_SG_REL_ VMCU SG_ 2364539395 TransmissionDrivelineEngaged_ISi 60;
BA_REL_ "GenSigFirstTimeoutTime" BU_SG_REL_ BBM SG_ 2364539395 TransmissionDrivelineEngaged_ISi 3000;
BA_REL_ "GenSigTimeoutTime" BU_SG_REL_ BBM SG_ 2364539395 TransmissionDrivelineEngaged_ISi 60;
BA_REL_ "GenSigFirstTimeoutTime" BU_SG_REL_ DACU SG_ 2364539395 TransmissionDrivelineEngaged_ISi 3000;
BA_REL_ "GenSigTimeoutTime" BU_SG_REL_ DACU SG_ 2364539395 TransmissionDrivelineEngaged_ISi 60;
BA_REL_ "GenSigFirstTimeoutTime" BU_SG_REL_ EBS SG_ 2364539395 TransmissionDrivelineEngaged_ISi 3000;
BA_REL_ "GenSigTimeoutTime" BU_SG_REL_ EBS SG_ 2364539395 TransmissionDrivelineEngaged_ISi 60;
BA_REL_ "GenSigFirstTimeoutTime" BU_SG_REL_ BBM SG_ 2364539395 TransmissionInputShaftSpeed_ISig 3000;
BA_REL_ "GenSigTimeoutTime" BU_SG_REL_ BBM SG_ 2364539395 TransmissionInputShaftSpeed_ISig 60;
BA_REL_ "GenSigFirstTimeoutTime" BU_SG_REL_ EBS SG_ 2364539395 TransmissionInputShaftSpeed_ISig 3000;
BA_REL_ "GenSigTimeoutTime" BU_SG_REL_ EBS SG_ 2364539395 TransmissionInputShaftSpeed_ISig 60;
BA_REL_ "GenSigFirstTimeoutTime" BU_SG_REL_ BBM SG_ 2364539395 MomentaryEngineOverspeedEnable_I 3000;
BA_REL_ "GenSigTimeoutTime" BU_SG_REL_ BBM SG_ 2364539395 MomentaryEngineOverspeedEnable_I 60;
BA_REL_ "GenSigFirstTimeoutTime" BU_SG_REL_ EMS SG_ 2364539395 MomentaryEngineOverspeedEnable_I 3000;
BA_REL_ "GenSigTimeoutTime" BU_SG_REL_ EMS SG_ 2364539395 MomentaryEngineOverspeedEnable_I 60;
BA_REL_ "GenSigFirstTimeoutTime" BU_SG_REL_ EMS SG_ 2364539395 TransmissionShiftInProcess_ISig_ 3000;
BA_REL_ "GenSigTimeoutTime" BU_SG_REL_ EMS SG_ 2364539395 TransmissionShiftInProcess_ISig_ 60;
BA_REL_ "GenSigFirstTimeoutTime" BU_SG_REL_ VMCU SG_ 2364539395 TransmissionShiftInProcess_ISig_ 3000;
BA_REL_ "GenSigTimeoutTime" BU_SG_REL_ VMCU SG_ 2364539395 TransmissionShiftInProcess_ISig_ 60;
BA_REL_ "GenSigFirstTimeoutTime" BU_SG_REL_ EBS SG_ 2364539395 TransmissionShiftInProcess_ISig_ 3000;
BA_REL_ "GenSigTimeoutTime" BU_SG_REL_ EBS SG_ 2364539395 TransmissionShiftInProcess_ISig_ 60;
BA_REL_ "GenSigFirstTimeoutTime" BU_SG_REL_ BBM SG_ 2364539395 TransmissionShiftInProcess_ISig_ 3000;
BA_REL_ "GenSigTimeoutTime" BU_SG_REL_ BBM SG_ 2364539395 TransmissionShiftInProcess_ISig_ 60;
BA_REL_ "GenSigFirstTimeoutTime" BU_SG_REL_ DACU SG_ 2364539395 TransmissionShiftInProcess_ISig_ 3000;
BA_REL_ "GenSigTimeoutTime" BU_SG_REL_ DACU SG_ 2364539395 TransmissionShiftInProcess_ISig_ 600;
BA_REL_ "GenSigFirstTimeoutTime" BU_SG_REL_ IC3 SG_ 2566843904 EngineOilTemperature_ISig_3 24000;
BA_REL_ "GenSigTimeoutTime" BU_SG_REL_ IC3 SG_ 2566843904 EngineOilTemperature_ISig_3 6000;
BA_REL_ "GenSigFirstTimeoutTime" BU_SG_REL_ BBM SG_ 2566843904 EngineOilTemperature_ISig_3 24000;
BA_REL_ "GenSigTimeoutTime" BU_SG_REL_ BBM SG_ 2566843904 EngineOilTemperature_ISig_3 6000;
BA_REL_ "GenSigFirstTimeoutTime" BU_SG_REL_ TECU SG_ 2566843904 EngineOilTemperature_ISig_3 24000;
BA_REL_ "GenSigTimeoutTime" BU_SG_REL_ TECU SG_ 2566843904 EngineOilTemperature_ISig_3 6000;
BA_REL_ "GenSigFirstTimeoutTime" BU_SG_REL_ CIOM SG_ 2566843904 EngineCoolantTemp_stat_ISig_3 24000;
BA_REL_ "GenSigTimeoutTime" BU_SG_REL_ CIOM SG_ 2566843904 EngineCoolantTemp_stat_ISig_3 6000;
BA_REL_ "GenSigFirstTimeoutTime" BU_SG_REL_ IC3 SG_ 2566843904 EngineCoolantTemp_stat_ISig_3 24000;
BA_REL_ "GenSigTimeoutTime" BU_SG_REL_ IC3 SG_ 2566843904 EngineCoolantTemp_stat_ISig_3 6000;
BA_REL_ "GenSigFirstTimeoutTime" BU_SG_REL_ VMCU SG_ 2566843904 EngineCoolantTemp_stat_ISig_3 24000;
BA_REL_ "GenSigTimeoutTime" BU_SG_REL_ VMCU SG_ 2566843904 EngineCoolantTemp_stat_ISig_3 6000;
BA_REL_ "GenSigFirstTimeoutTime" BU_SG_REL_ TECU SG_ 2566843904 EngineCoolantTemp_stat_ISig_3 24000;
BA_REL_ "GenSigTimeoutTime" BU_SG_REL_ TECU SG_ 2566843904 EngineCoolantTemp_stat_ISig_3 6000;
BA_REL_ "GenSigFirstTimeoutTime" BU_SG_REL_ ACM SG_ 2566843904 EngineCoolantTemp_stat_ISig_3 24000;
BA_REL_ "GenSigTimeoutTime" BU_SG_REL_ ACM SG_ 2566843904 EngineCoolantTemp_stat_ISig_3 6000;
BA_REL_ "GenSigFirstTimeoutTime" BU_SG_REL_ BBM SG_ 2566843904 EngineCoolantTemp_stat_ISig_3 24000;
BA_REL_ "GenSigTimeoutTime" BU_SG_REL_ BBM SG_ 2566843904 EngineCoolantTemp_stat_ISig_3 6000;
BA_REL_ "GenSigFirstTimeoutTime" BU_SG_REL_ EMS SG_ 2565865488 EngineCoolantLoadIncrease 3000;
BA_REL_ "GenSigTimeoutTime" BU_SG_REL_ EMS SG_ 2565865488 EngineCoolantLoadIncrease 600;
BA_REL_ "GenSigFirstTimeoutTime" BU_SG_REL_ EMS SG_ 2565865488 ActualMaxAvailDrvlnRetPrctTrq 3000;
BA_REL_ "GenSigTimeoutTime" BU_SG_REL_ EMS SG_ 2565865488 ActualMaxAvailDrvlnRetPrctTrq 600;
BA_REL_ "GenSigFirstTimeoutTime" BU_SG_REL_ EBS SG_ 2565865488 ActualMaxAvailDrvlnRetPrctTrq 3000;
BA_REL_ "GenSigTimeoutTime" BU_SG_REL_ EBS SG_ 2565865488 ActualMaxAvailDrvlnRetPrctTrq 600;
BA_REL_ "GenSigFirstTimeoutTime" BU_SG_REL_ VMCU SG_ 2565865488 ActualMaxAvailDrvlnRetPrctTrq 3000;
BA_REL_ "GenSigTimeoutTime" BU_SG_REL_ VMCU SG_ 2565865488 ActualMaxAvailDrvlnRetPrctTrq 600;
BA_REL_ "GenSigFirstTimeoutTime" BU_SG_REL_ TECU SG_ 2565865488 ActualMaxAvailDrvlnRetPrctTrq 3000;
BA_REL_ "GenSigTimeoutTime" BU_SG_REL_ TECU SG_ 2565865488 ActualMaxAvailDrvlnRetPrctTrq 600;
BA_REL_ "GenSigFirstTimeoutTime" BU_SG_REL_ EMS SG_ 2565865488 ActualDrvlnRetdrPercentTorque_IS 3000;
BA_REL_ "GenSigTimeoutTime" BU_SG_REL_ EMS SG_ 2565865488 ActualDrvlnRetdrPercentTorque_IS 600;
BA_REL_ "GenSigFirstTimeoutTime" BU_SG_REL_ CIOM SG_ 2565865488 ActualDrvlnRetdrPercentTorque_IS 3000;
BA_REL_ "GenSigTimeoutTime" BU_SG_REL_ CIOM SG_ 2565865488 ActualDrvlnRetdrPercentTorque_IS 600;
BA_REL_ "GenSigFirstTimeoutTime" BU_SG_REL_ VMCU SG_ 2565865488 ActualDrvlnRetdrPercentTorque_IS 3000;
BA_REL_ "GenSigTimeoutTime" BU_SG_REL_ VMCU SG_ 2565865488 ActualDrvlnRetdrPercentTorque_IS 600;
BA_REL_ "GenSigFirstTimeoutTime" BU_SG_REL_ TECU SG_ 2565865488 ActualDrvlnRetdrPercentTorque_IS 3000;
BA_REL_ "GenSigTimeoutTime" BU_SG_REL_ TECU SG_ 2565865488 ActualDrvlnRetdrPercentTorque_IS 600;
BA_REL_ "GenSigFirstTimeoutTime" BU_SG_REL_ EBS SG_ 2565865488 ActualDrvlnRetdrPercentTorque_IS 3000;
BA_REL_ "GenSigTimeoutTime" BU_SG_REL_ EBS SG_ 2565865488 ActualDrvlnRetdrPercentTorque_IS 600;
BA_REL_ "GenSigFirstTimeoutTime" BU_SG_REL_ IC3 SG_ 2565865488 ActualDrvlnRetdrPercentTorque_IS 3000;
BA_REL_ "GenSigTimeoutTime" BU_SG_REL_ IC3 SG_ 2565865488 ActualDrvlnRetdrPercentTorque_IS 600;
BA_REL_ "GenSigFirstTimeoutTime" BU_SG_REL_ CIOM SG_ 2565865488 RetarderTorqueMode_ISig_3 3000;
BA_REL_ "GenSigTimeoutTime" BU_SG_REL_ CIOM SG_ 2565865488 RetarderTorqueMode_ISig_3 600;
BA_REL_ "GenSigFirstTimeoutTime" BU_SG_REL_ IC3 SG_ 2565865488 RetarderTorqueMode_ISig_3 3000;
BA_REL_ "GenSigTimeoutTime" BU_SG_REL_ IC3 SG_ 2565865488 RetarderTorqueMode_ISig_3 600;
BA_REL_ "GenSigFirstTimeoutTime" BU_SG_REL_ EMS SG_ 2565865488 RetarderTorqueMode_ISig_3 3000;
BA_REL_ "GenSigTimeoutTime" BU_SG_REL_ EMS SG_ 2565865488 RetarderTorqueMode_ISig_3 600;
BA_REL_ "GenSigFirstTimeoutTime" BU_SG_REL_ VMCU SG_ 2565865487 ActlMaxAvailEngRetdrPercentTrq 3000;
BA_REL_ "GenSigTimeoutTime" BU_SG_REL_ VMCU SG_ 2565865487 ActlMaxAvailEngRetdrPercentTrq 600;
BA_REL_ "GenSigFirstTimeoutTime" BU_SG_REL_ EBS SG_ 2565865487 ActlMaxAvailEngRetdrPercentTrq 3000;
BA_REL_ "GenSigTimeoutTime" BU_SG_REL_ EBS SG_ 2565865487 ActlMaxAvailEngRetdrPercentTrq 600;
BA_REL_ "GenSigFirstTimeoutTime" BU_SG_REL_ TECU SG_ 2565865487 RetarderEnableShiftAssistSw 3000;
BA_REL_ "GenSigTimeoutTime" BU_SG_REL_ TECU SG_ 2565865487 RetarderEnableShiftAssistSw 600;
BA_REL_ "GenSigFirstTimeoutTime" BU_SG_REL_ CIOM SG_ 2565865487 EngineRetarderTorqueMode_ISig_3 3000;
BA_REL_ "GenSigTimeoutTime" BU_SG_REL_ CIOM SG_ 2565865487 EngineRetarderTorqueMode_ISig_3 600;
BA_REL_ "GenSigFirstTimeoutTime" BU_SG_REL_ IC3 SG_ 2565865487 EngineRetarderTorqueMode_ISig_3 3000;
BA_REL_ "GenSigTimeoutTime" BU_SG_REL_ IC3 SG_ 2565865487 EngineRetarderTorqueMode_ISig_3 600;
BA_REL_ "GenSigFirstTimeoutTime" BU_SG_REL_ TECU SG_ 2565865487 EngRetdrEnableBrakeAssistSw 3000;
BA_REL_ "GenSigTimeoutTime" BU_SG_REL_ TECU SG_ 2565865487 EngRetdrEnableBrakeAssistSw 600;
BA_REL_ "GenSigFirstTimeoutTime" BU_SG_REL_ RECU_Virt SG_ 2565865487 ActualEngineRetarderPercentTrq_I 3000;
BA_REL_ "GenSigTimeoutTime" BU_SG_REL_ RECU_Virt SG_ 2565865487 ActualEngineRetarderPercentTrq_I 600;
BA_REL_ "GenSigFirstTimeoutTime" BU_SG_REL_ CIOM SG_ 2565865487 ActualEngineRetarderPercentTrq_I 3000;
BA_REL_ "GenSigTimeoutTime" BU_SG_REL_ CIOM SG_ 2565865487 ActualEngineRetarderPercentTrq_I 600;
BA_REL_ "GenSigFirstTimeoutTime" BU_SG_REL_ EBS SG_ 2565865487 ActualEngineRetarderPercentTrq_I 3000;
BA_REL_ "GenSigTimeoutTime" BU_SG_REL_ EBS SG_ 2565865487 ActualEngineRetarderPercentTrq_I 600;
BA_REL_ "GenSigFirstTimeoutTime" BU_SG_REL_ IC3 SG_ 2565865487 ActualEngineRetarderPercentTrq_I 3000;
BA_REL_ "GenSigTimeoutTime" BU_SG_REL_ IC3 SG_ 2565865487 ActualEngineRetarderPercentTrq_I 600;
BA_REL_ "GenSigFirstTimeoutTime" BU_SG_REL_ VMCU SG_ 2565865487 ActualEngineRetarderPercentTrq_I 3000;
BA_REL_ "GenSigTimeoutTime" BU_SG_REL_ VMCU SG_ 2565865487 ActualEngineRetarderPercentTrq_I 600;
BA_REL_ "GenSigFirstTimeoutTime" BU_SG_REL_ TECU SG_ 2565865487 ActualEngineRetarderPercentTrq_I 3000;
BA_REL_ "GenSigTimeoutTime" BU_SG_REL_ TECU SG_ 2565865487 ActualEngineRetarderPercentTrq_I 600;
BA_REL_ "GenSigFirstTimeoutTime" BU_SG_REL_ CIOM SG_ 2364541440 EngineIntakeAirRate 12000;
BA_REL_ "GenSigTimeoutTime" BU_SG_REL_ CIOM SG_ 2364541440 EngineIntakeAirRate 3000;
BA_REL_ "GenSigFirstTimeoutTime" BU_SG_REL_ BBM SG_ 2566844160 EngineOilLevel_ISig_3 12000;
BA_REL_ "GenSigTimeoutTime" BU_SG_REL_ BBM SG_ 2566844160 EngineOilLevel_ISig_3 3000;
BA_REL_ "GenSigFirstTimeoutTime" BU_SG_REL_ IC3 SG_ 2566844160 EngineOilLevel_ISig_3 12000;
BA_REL_ "GenSigTimeoutTime" BU_SG_REL_ IC3 SG_ 2566844160 EngineOilLevel_ISig_3 3000;
BA_REL_ "GenSigFirstTimeoutTime" BU_SG_REL_ VMCU SG_ 2566844160 EngineOilPressure_ISig_3 12000;
BA_REL_ "GenSigTimeoutTime" BU_SG_REL_ VMCU SG_ 2566844160 EngineOilPressure_ISig_3 3000;
BA_REL_ "GenSigFirstTimeoutTime" BU_SG_REL_ IC3 SG_ 2566844160 EngineOilPressure_ISig_3 12000;
BA_REL_ "GenSigTimeoutTime" BU_SG_REL_ IC3 SG_ 2566844160 EngineOilPressure_ISig_3 3000;
BA_REL_ "GenSigFirstTimeoutTime" BU_SG_REL_ BBM SG_ 2566844160 EngineOilPressure_ISig_3 12000;
BA_REL_ "GenSigTimeoutTime" BU_SG_REL_ BBM SG_ 2566844160 EngineOilPressure_ISig_3 3000;
BA_REL_ "GenSigFirstTimeoutTime" BU_SG_REL_ VMCU SG_ 2566840064 NominalFrictionPercentTorque_ISi 6000;
BA_REL_ "GenSigTimeoutTime" BU_SG_REL_ VMCU SG_ 2566840064 NominalFrictionPercentTorque_ISi 1500;
BA_REL_ "GenSigFirstTimeoutTime" BU_SG_REL_ TECU SG_ 2566840064 NominalFrictionPercentTorque_ISi 6000;
BA_REL_ "GenSigTimeoutTime" BU_SG_REL_ TECU SG_ 2566840064 NominalFrictionPercentTorque_ISi 1500;
BA_REL_ "GenSigFirstTimeoutTime" BU_SG_REL_ DACU SG_ 2566840064 NominalFrictionPercentTorque_ISi 6000;
BA_REL_ "GenSigTimeoutTime" BU_SG_REL_ DACU SG_ 2566840064 NominalFrictionPercentTorque_ISi 1500;
BA_REL_ "GenSigFirstTimeoutTime" BU_SG_REL_ CIOM SG_ 2566840064 NominalFrictionPercentTorque_ISi 6000;
BA_REL_ "GenSigTimeoutTime" BU_SG_REL_ CIOM SG_ 2566840064 NominalFrictionPercentTorque_ISi 1500;
BA_REL_ "GenSigFirstTimeoutTime" BU_SG_REL_ EBS SG_ 2566840064 NominalFrictionPercentTorque_ISi 6000;
BA_REL_ "GenSigTimeoutTime" BU_SG_REL_ EBS SG_ 2566840064 NominalFrictionPercentTorque_ISi 1500;
BA_REL_ "GenSigFirstTimeoutTime" BU_SG_REL_ RECU_Virt SG_ 2566840064 NominalFrictionPercentTorque_ISi 6000;
BA_REL_ "GenSigTimeoutTime" BU_SG_REL_ RECU_Virt SG_ 2566840064 NominalFrictionPercentTorque_ISi 1500;
BA_REL_ "GenSigFirstTimeoutTime" BU_SG_REL_ TECU SG_ 2364539665 AcceleratorPedalPositionVendor 3000;
BA_REL_ "GenSigTimeoutTime" BU_SG_REL_ TECU SG_ 2364539665 AcceleratorPedalPositionVendor 300;
BA_REL_ "GenSigFirstTimeoutTime" BU_SG_REL_ ACM SG_ 2364539648 EnginePercentLoadAtCurrentSpd_IS 3000;
BA_REL_ "GenSigTimeoutTime" BU_SG_REL_ ACM SG_ 2364539648 EnginePercentLoadAtCurrentSpd_IS 300;
BA_REL_ "GenSigFirstTimeoutTime" BU_SG_REL_ IC3 SG_ 2364539648 EnginePercentLoadAtCurrentSpd_IS 3000;
BA_REL_ "GenSigTimeoutTime" BU_SG_REL_ IC3 SG_ 2364539648 EnginePercentLoadAtCurrentSpd_IS 300;
BA_REL_ "GenSigFirstTimeoutTime" BU_SG_REL_ BBM SG_ 2364539648 EnginePercentLoadAtCurrentSpd_IS 3000;
BA_REL_ "GenSigTimeoutTime" BU_SG_REL_ BBM SG_ 2364539648 EnginePercentLoadAtCurrentSpd_IS 300;
BA_REL_ "GenSigFirstTimeoutTime" BU_SG_REL_ CIOM SG_ 2364539648 EnginePercentLoadAtCurrentSpd_IS 3000;
BA_REL_ "GenSigTimeoutTime" BU_SG_REL_ CIOM SG_ 2364539648 EnginePercentLoadAtCurrentSpd_IS 300;
BA_REL_ "GenSigFirstTimeoutTime" BU_SG_REL_ VMCU SG_ 2364539648 EnginePercentLoadAtCurrentSpd_IS 3000;
BA_REL_ "GenSigTimeoutTime" BU_SG_REL_ VMCU SG_ 2364539648 EnginePercentLoadAtCurrentSpd_IS 300;
BA_REL_ "GenSigFirstTimeoutTime" BU_SG_REL_ TECU SG_ 2364539648 EnginePercentLoadAtCurrentSpd_IS 3000;
BA_REL_ "GenSigTimeoutTime" BU_SG_REL_ TECU SG_ 2364539648 EnginePercentLoadAtCurrentSpd_IS 300;
BA_REL_ "GenSigFirstTimeoutTime" BU_SG_REL_ TECU SG_ 2364539648 AcceleratorPedalPosition1_2 3000;
BA_REL_ "GenSigTimeoutTime" BU_SG_REL_ TECU SG_ 2364539648 AcceleratorPedalPosition1_2 300;
BA_REL_ "GenSigFirstTimeoutTime" BU_SG_REL_ TECU SG_ 2364539648 RoadSpeedLimitStatus 3000;
BA_REL_ "GenSigTimeoutTime" BU_SG_REL_ TECU SG_ 2364539648 RoadSpeedLimitStatus 300;
BA_REL_ "GenSigFirstTimeoutTime" BU_SG_REL_ TECU SG_ 2364539904 EngineDemandPercentTorque 3000;
BA_REL_ "GenSigTimeoutTime" BU_SG_REL_ TECU SG_ 2364539904 EngineDemandPercentTorque 120;
BA_REL_ "GenSigFirstTimeoutTime" BU_SG_REL_ CIOM SG_ 2364539904 EngineDemandPercentTorque 3000;
BA_REL_ "GenSigTimeoutTime" BU_SG_REL_ CIOM SG_ 2364539904 EngineDemandPercentTorque 120;
BA_REL_ "GenSigFirstTimeoutTime" BU_SG_REL_ BBM SG_ 2364539904 DrvrDemandEngPercentTorque_ISig_ 3000;
BA_REL_ "GenSigTimeoutTime" BU_SG_REL_ BBM SG_ 2364539904 DrvrDemandEngPercentTorque_ISig_ 120;
BA_REL_ "GenSigFirstTimeoutTime" BU_SG_REL_ TECU SG_ 2364539904 DrvrDemandEngPercentTorque_ISig_ 3000;
BA_REL_ "GenSigTimeoutTime" BU_SG_REL_ TECU SG_ 2364539904 DrvrDemandEngPercentTorque_ISig_ 120;
BA_REL_ "GenSigFirstTimeoutTime" BU_SG_REL_ EBS SG_ 2364539904 DrvrDemandEngPercentTorque_ISig_ 3000;
BA_REL_ "GenSigTimeoutTime" BU_SG_REL_ EBS SG_ 2364539904 DrvrDemandEngPercentTorque_ISig_ 120;
BA_REL_ "GenSigFirstTimeoutTime" BU_SG_REL_ VMCU SG_ 2364539904 DrvrDemandEngPercentTorque_ISig_ 3000;
BA_REL_ "GenSigTimeoutTime" BU_SG_REL_ VMCU SG_ 2364539904 DrvrDemandEngPercentTorque_ISig_ 120;
BA_REL_ "GenSigFirstTimeoutTime" BU_SG_REL_ TECU SG_ 2364539904 EngineTorqueMode_ISig_3 3000;
BA_REL_ "GenSigTimeoutTime" BU_SG_REL_ TECU SG_ 2364539904 EngineTorqueMode_ISig_3 120;
BA_REL_ "GenSigFirstTimeoutTime" BU_SG_REL_ VMCU SG_ 2364539904 EngineTorqueMode_ISig_3 3000;
BA_REL_ "GenSigTimeoutTime" BU_SG_REL_ VMCU SG_ 2364539904 EngineTorqueMode_ISig_3 120;
BA_REL_ "GenSigFirstTimeoutTime" BU_SG_REL_ BBM SG_ 2364539904 EngineTorqueMode_ISig_3 3000;
BA_REL_ "GenSigTimeoutTime" BU_SG_REL_ BBM SG_ 2364539904 EngineTorqueMode_ISig_3 120;
BA_REL_ "GenSigFirstTimeoutTime" BU_SG_REL_ EBS SG_ 2364539904 EngineTorqueMode_ISig_3 3000;
BA_REL_ "GenSigTimeoutTime" BU_SG_REL_ EBS SG_ 2364539904 EngineTorqueMode_ISig_3 120;
BA_REL_ "GenSigFirstTimeoutTime" BU_SG_REL_ IC3 SG_ 2364539904 EngineTorqueMode_ISig_3 3000;
BA_REL_ "GenSigTimeoutTime" BU_SG_REL_ IC3 SG_ 2364539904 EngineTorqueMode_ISig_3 120;
BA_REL_ "GenSigFirstTimeoutTime" BU_SG_REL_ BBM SG_ 2364539904 EngineSpeed_ISig_3 3000;
BA_REL_ "GenSigTimeoutTime" BU_SG_REL_ BBM SG_ 2364539904 EngineSpeed_ISig_3 120;
BA_REL_ "GenSigFirstTimeoutTime" BU_SG_REL_ DACU SG_ 2364539904 EngineSpeed_ISig_3 3000;
BA_REL_ "GenSigTimeoutTime" BU_SG_REL_ DACU SG_ 2364539904 EngineSpeed_ISig_3 120;
BA_REL_ "GenSigFirstTimeoutTime" BU_SG_REL_ IC3 SG_ 2364539904 EngineSpeed_ISig_3 3000;
BA_REL_ "GenSigTimeoutTime" BU_SG_REL_ IC3 SG_ 2364539904 EngineSpeed_ISig_3 120;
BA_REL_ "GenSigFirstTimeoutTime" BU_SG_REL_ VMCU SG_ 2364539904 EngineSpeed_ISig_3 3000;
BA_REL_ "GenSigTimeoutTime" BU_SG_REL_ VMCU SG_ 2364539904 EngineSpeed_ISig_3 120;
BA_REL_ "GenSigFirstTimeoutTime" BU_SG_REL_ EBS SG_ 2364539904 EngineSpeed_ISig_3 3000;
BA_REL_ "GenSigTimeoutTime" BU_SG_REL_ EBS SG_ 2364539904 EngineSpeed_ISig_3 120;
BA_REL_ "GenSigFirstTimeoutTime" BU_SG_REL_ ACM SG_ 2364539904 EngineSpeed_ISig_3 3000;
BA_REL_ "GenSigTimeoutTime" BU_SG_REL_ ACM SG_ 2364539904 EngineSpeed_ISig_3 120;
BA_REL_ "GenSigFirstTimeoutTime" BU_SG_REL_ TECU SG_ 2364539904 EngineSpeed_ISig_3 3000;
BA_REL_ "GenSigTimeoutTime" BU_SG_REL_ TECU SG_ 2364539904 EngineSpeed_ISig_3 120;
BA_REL_ "GenSigFirstTimeoutTime" BU_SG_REL_ CIOM SG_ 2364539904 EngineSpeed_ISig_3 3000;
BA_REL_ "GenSigTimeoutTime" BU_SG_REL_ CIOM SG_ 2364539904 EngineSpeed_ISig_3 120;
BA_REL_ "GenSigFirstTimeoutTime" BU_SG_REL_ IC3 SG_ 2364539904 ActualEnginePercentTorque_ISig_3 3000;
BA_REL_ "GenSigTimeoutTime" BU_SG_REL_ IC3 SG_ 2364539904 ActualEnginePercentTorque_ISig_3 120;
BA_REL_ "GenSigFirstTimeoutTime" BU_SG_REL_ VMCU SG_ 2364539904 ActualEnginePercentTorque_ISig_3 3000;
BA_REL_ "GenSigTimeoutTime" BU_SG_REL_ VMCU SG_ 2364539904 ActualEnginePercentTorque_ISig_3 120;
BA_REL_ "GenSigFirstTimeoutTime" BU_SG_REL_ EBS SG_ 2364539904 ActualEnginePercentTorque_ISig_3 3000;
BA_REL_ "GenSigTimeoutTime" BU_SG_REL_ EBS SG_ 2364539904 ActualEnginePercentTorque_ISig_3 120;
BA_REL_ "GenSigFirstTimeoutTime" BU_SG_REL_ CIOM SG_ 2364539904 ActualEnginePercentTorque_ISig_3 3000;
BA_REL_ "GenSigTimeoutTime" BU_SG_REL_ CIOM SG_ 2364539904 ActualEnginePercentTorque_ISig_3 120;
BA_REL_ "GenSigFirstTimeoutTime" BU_SG_REL_ TECU SG_ 2364539904 ActualEnginePercentTorque_ISig_3 3000;
BA_REL_ "GenSigTimeoutTime" BU_SG_REL_ TECU SG_ 2364539904 ActualEnginePercentTorque_ISig_3 120;
BA_REL_ "GenSigFirstTimeoutTime" BU_SG_REL_ BBM SG_ 2364539904 ActualEnginePercentTorque_ISig_3 3000;
BA_REL_ "GenSigTimeoutTime" BU_SG_REL_ BBM SG_ 2364539904 ActualEnginePercentTorque_ISig_3 120;
BA_REL_ "GenSigFirstTimeoutTime" BU_SG_REL_ DACU SG_ 2364539904 ActualEnginePercentTorque_ISig_3 3000;
BA_REL_ "GenSigTimeoutTime" BU_SG_REL_ DACU SG_ 2364539904 ActualEnginePercentTorque_ISig_3 120;
BA_REL_ "GenSigFirstTimeoutTime" BU_SG_REL_ VMCU SG_ 2364539904 EngineStarterMode_ISig_3 3000;
BA_REL_ "GenSigTimeoutTime" BU_SG_REL_ VMCU SG_ 2364539904 EngineStarterMode_ISig_3 120;
BA_REL_ "GenSigFirstTimeoutTime" BU_SG_REL_ BBM SG_ 2364539904 EngineStarterMode_ISig_3 3000;
BA_REL_ "GenSigTimeoutTime" BU_SG_REL_ BBM SG_ 2364539904 EngineStarterMode_ISig_3 120;
BA_REL_ "GenSigFirstTimeoutTime" BU_SG_REL_ IC3 SG_ 2364539904 EngineStarterMode_ISig_3 3000;
BA_REL_ "GenSigTimeoutTime" BU_SG_REL_ IC3 SG_ 2364539904 EngineStarterMode_ISig_3 120;
BA_REL_ "GenSigFirstTimeoutTime" BU_SG_REL_ TECU SG_ 2566841088 EngConf_EngSpeedAtHighIdle_P6 65000;
BA_REL_ "GenSigTimeoutTime" BU_SG_REL_ TECU SG_ 2566841088 EngConf_EngSpeedAtHighIdle_P6 30000;
BA_REL_ "GenSigFirstTimeoutTime" BU_SG_REL_ TECU SG_ 2566841088 EngConf_EngTorqueAt_P4 65000;
BA_REL_ "GenSigTimeoutTime" BU_SG_REL_ TECU SG_ 2566841088 EngConf_EngTorqueAt_P4 30000;
BA_REL_ "GenSigFirstTimeoutTime" BU_SG_REL_ TECU SG_ 2566841088 EngConf_EngMaxMomOvSpeed_P7 65000;
BA_REL_ "GenSigTimeoutTime" BU_SG_REL_ TECU SG_ 2566841088 EngConf_EngMaxMomOvSpeed_P7 30000;
BA_REL_ "GenSigFirstTimeoutTime" BU_SG_REL_ TECU SG_ 2566841088 EngConf_EngTorqueAt_P5 65000;
BA_REL_ "GenSigTimeoutTime" BU_SG_REL_ TECU SG_ 2566841088 EngConf_EngTorqueAt_P5 30000;
BA_REL_ "GenSigFirstTimeoutTime" BU_SG_REL_ TECU SG_ 2566841088 EngConf_EngSpeedAtIdle_P1 65000;
BA_REL_ "GenSigTimeoutTime" BU_SG_REL_ TECU SG_ 2566841088 EngConf_EngSpeedAtIdle_P1 30000;
BA_REL_ "GenSigFirstTimeoutTime" BU_SG_REL_ TECU SG_ 2566841088 EngineReferenceTorque_ISig_3 65000;
BA_REL_ "GenSigTimeoutTime" BU_SG_REL_ TECU SG_ 2566841088 EngineReferenceTorque_ISig_3 30000;
BA_REL_ "GenSigFirstTimeoutTime" BU_SG_REL_ CIOM SG_ 2566841088 EngineReferenceTorque_ISig_3 60000;
BA_REL_ "GenSigTimeoutTime" BU_SG_REL_ CIOM SG_ 2566841088 EngineReferenceTorque_ISig_3 30000;
BA_REL_ "GenSigFirstTimeoutTime" BU_SG_REL_ RECU_Virt SG_ 2566841088 EngineReferenceTorque_ISig_3 65000;
BA_REL_ "GenSigTimeoutTime" BU_SG_REL_ RECU_Virt SG_ 2566841088 EngineReferenceTorque_ISig_3 30000;
BA_REL_ "GenSigFirstTimeoutTime" BU_SG_REL_ DACU SG_ 2566841088 EngineReferenceTorque_ISig_3 60000;
BA_REL_ "GenSigTimeoutTime" BU_SG_REL_ DACU SG_ 2566841088 EngineReferenceTorque_ISig_3 30000;
BA_REL_ "GenSigFirstTimeoutTime" BU_SG_REL_ EBS SG_ 2566841088 EngineReferenceTorque_ISig_3 65000;
BA_REL_ "GenSigTimeoutTime" BU_SG_REL_ EBS SG_ 2566841088 EngineReferenceTorque_ISig_3 30000;
BA_REL_ "GenSigFirstTimeoutTime" BU_SG_REL_ VMCU SG_ 2566841088 EngineReferenceTorque_ISig_3 65000;
BA_REL_ "GenSigTimeoutTime" BU_SG_REL_ VMCU SG_ 2566841088 EngineReferenceTorque_ISig_3 30000;
BA_REL_ "GenSigFirstTimeoutTime" BU_SG_REL_ TECU SG_ 2566841088 EngConf_EngSpeedAt_P2 65000;
BA_REL_ "GenSigTimeoutTime" BU_SG_REL_ TECU SG_ 2566841088 EngConf_EngSpeedAt_P2 30000;
BA_REL_ "GenSigFirstTimeoutTime" BU_SG_REL_ TECU SG_ 2566841088 EngConf_MaxMomOverrideTimeLim 65000;
BA_REL_ "GenSigTimeoutTime" BU_SG_REL_ TECU SG_ 2566841088 EngConf_MaxMomOverrideTimeLim 30000;
BA_REL_ "GenSigFirstTimeoutTime" BU_SG_REL_ TECU SG_ 2566841088 EngConf_EngSpeedAt_P5 65000;
BA_REL_ "GenSigTimeoutTime" BU_SG_REL_ TECU SG_ 2566841088 EngConf_EngSpeedAt_P5 30000;
BA_REL_ "GenSigFirstTimeoutTime" BU_SG_REL_ TECU SG_ 2566841088 EngConf_EngTorqueAtIdle_P1 65000;
BA_REL_ "GenSigTimeoutTime" BU_SG_REL_ TECU SG_ 2566841088 EngConf_EngTorqueAtIdle_P1 30000;
BA_REL_ "GenSigFirstTimeoutTime" BU_SG_REL_ TECU SG_ 2566841088 EngConf_EngSpeedAt_P4 65000;
BA_REL_ "GenSigTimeoutTime" BU_SG_REL_ TECU SG_ 2566841088 EngConf_EngSpeedAt_P4 30000;
BA_REL_ "GenSigFirstTimeoutTime" BU_SG_REL_ TECU SG_ 2566841088 EngConf_EngSpeedAt_P3 65000;
BA_REL_ "GenSigTimeoutTime" BU_SG_REL_ TECU SG_ 2566841088 EngConf_EngSpeedAt_P3 30000;
BA_REL_ "GenSigFirstTimeoutTime" BU_SG_REL_ TECU SG_ 2566841088 EngConf_EngTorqueAt_P3 65000;
BA_REL_ "GenSigTimeoutTime" BU_SG_REL_ TECU SG_ 2566841088 EngConf_EngTorqueAt_P3 30000;
BA_REL_ "GenSigFirstTimeoutTime" BU_SG_REL_ TECU SG_ 2566841088 EngConf_EngTorqueAt_P2 65000;
BA_REL_ "GenSigTimeoutTime" BU_SG_REL_ TECU SG_ 2566841088 EngConf_EngTorqueAt_P2 30000;
BA_REL_ "GenSigFirstTimeoutTime" BU_SG_REL_ IC3 SG_ 2566911243 Trailer5PneumSupply_Status_ISig_ 24000;
BA_REL_ "GenSigTimeoutTime" BU_SG_REL_ IC3 SG_ 2566911243 Trailer5PneumSupply_Status_ISig_ 6000;
BA_REL_ "GenSigFirstTimeoutTime" BU_SG_REL_ IC3 SG_ 2566911243 Trailer5VehicleType_ISig_3 24000;
BA_REL_ "GenSigTimeoutTime" BU_SG_REL_ IC3 SG_ 2566911243 Trailer5VehicleType_ISig_3 6000;
BA_REL_ "GenSigFirstTimeoutTime" BU_SG_REL_ IC3 SG_ 2566911243 Trailer5ElectricalSupplyStat_ISi 24000;
BA_REL_ "GenSigTimeoutTime" BU_SG_REL_ IC3 SG_ 2566911243 Trailer5ElectricalSupplyStat_ISi 6000;
BA_REL_ "GenSigFirstTimeoutTime" BU_SG_REL_ IC3 SG_ 2566911243 Trailer5ROPSystemStatus_ISig_3 24000;
BA_REL_ "GenSigTimeoutTime" BU_SG_REL_ IC3 SG_ 2566911243 Trailer5ROPSystemStatus_ISig_3 6000;
BA_REL_ "GenSigFirstTimeoutTime" BU_SG_REL_ IC3 SG_ 2566911243 Trailer5EBSRedWarning_ISig_3 24000;
BA_REL_ "GenSigTimeoutTime" BU_SG_REL_ IC3 SG_ 2566911243 Trailer5EBSRedWarning_ISig_3 6000;
BA_REL_ "GenSigFirstTimeoutTime" BU_SG_REL_ IC3 SG_ 2566911243 Trailer5PneumSupply_Pressure_ISi 24000;
BA_REL_ "GenSigTimeoutTime" BU_SG_REL_ IC3 SG_ 2566911243 Trailer5PneumSupply_Pressure_ISi 6000;
BA_REL_ "GenSigFirstTimeoutTime" BU_SG_REL_ IC3 SG_ 2566911243 Trailer5LoadRampApprAssistStat_I 24000;
BA_REL_ "GenSigTimeoutTime" BU_SG_REL_ IC3 SG_ 2566911243 Trailer5LoadRampApprAssistStat_I 6000;
BA_REL_ "GenSigFirstTimeoutTime" BU_SG_REL_ IC3 SG_ 2566911243 Trailer5LevelControlStatus_ISig_ 24000;
BA_REL_ "GenSigTimeoutTime" BU_SG_REL_ IC3 SG_ 2566911243 Trailer5LevelControlStatus_ISig_ 6000;
BA_REL_ "GenSigFirstTimeoutTime" BU_SG_REL_ IC3 SG_ 2566911243 Trailer5ExtLvlStorageSupport_ISi 24000;
BA_REL_ "GenSigTimeoutTime" BU_SG_REL_ IC3 SG_ 2566911243 Trailer5ExtLvlStorageSupport_ISi 6000;
BA_REL_ "GenSigFirstTimeoutTime" BU_SG_REL_ IC3 SG_ 2566911243 Trailer5NomBodyLevel_RearLevel_I 24000;
BA_REL_ "GenSigTimeoutTime" BU_SG_REL_ IC3 SG_ 2566911243 Trailer5NomBodyLevel_RearLevel_I 6000;
BA_REL_ "GenSigFirstTimeoutTime" BU_SG_REL_ IC3 SG_ 2566911243 Trailer5YCSystemStatus_ISig_3 24000;
BA_REL_ "GenSigTimeoutTime" BU_SG_REL_ IC3 SG_ 2566911243 Trailer5YCSystemStatus_ISig_3 6000;
BA_REL_ "GenSigFirstTimeoutTime" BU_SG_REL_ IC3 SG_ 2566911243 Trailer5EBSAmberWarning_ISig_3 24000;
BA_REL_ "GenSigTimeoutTime" BU_SG_REL_ IC3 SG_ 2566911243 Trailer5EBSAmberWarning_ISig_3 6000;
BA_REL_ "GenSigFirstTimeoutTime" BU_SG_REL_ IC3 SG_ 2566911243 Trailer5NomBodyLevel_FrontLevel_ 24000;
BA_REL_ "GenSigTimeoutTime" BU_SG_REL_ IC3 SG_ 2566911243 Trailer5NomBodyLevel_FrontLevel_ 6000;
VAL_ 2566899694 RestingPeriodFlagShift2_ISig_3 1 "RestingPeriodFlagShift_Break3hMinAnd9hMaxWithinDrivingShift" 0 "RestingPeriodFlagShift_NoBreak3hMinAnd9hMaxWithinDrivingShift" ;
VAL_ 2566899694 UnknownPeriodShift1_ISig_3 1 "UnknownPeriodShift_UnknownTimeInDailyRestingPeriodShift" 0 "UnknownPeriodShift_NoUnknownTimeInDailyRestingPeriodShift" ;
VAL_ 2566899694 RestingPeriodFlagShift1_ISig_3 1 "RestingPeriodFlagShift_Break3hMinAnd9hMaxWithinDrivingShift" 0 "RestingPeriodFlagShift_NoBreak3hMinAnd9hMaxWithinDrivingShift" ;
VAL_ 2566899694 UnknownPeriodShift2_ISig_3 1 "UnknownPeriodShift_UnknownTimeInDailyRestingPeriodShift" 0 "UnknownPeriodShift_NoUnknownTimeInDailyRestingPeriodShift" ;
VAL_ 2566899694 RestingPeriodFlag_ISig_3 1 "RestingPeriodFlag_Break3hMinAnd9hMaxWithinCurrentDrivingTime" 0 "RestingPeriodFlag_NoBreak3hMinAnd9hMaxWithinCurrentDrivingTime" ;
VAL_ 2566899694 UnknownPeriodShift4_ISig_3 1 "UnknownPeriodShift_UnknownTimeInDailyRestingPeriodShift" 0 "UnknownPeriodShift_NoUnknownTimeInDailyRestingPeriodShift" ;
VAL_ 2566899694 RestingPeriodFlagShift6_ISig_3 1 "RestingPeriodFlagShift_Break3hMinAnd9hMaxWithinDrivingShift" 0 "RestingPeriodFlagShift_NoBreak3hMinAnd9hMaxWithinDrivingShift" ;
VAL_ 2566899694 RestingPeriodFlagShift5_ISig_3 1 "RestingPeriodFlagShift_Break3hMinAnd9hMaxWithinDrivingShift" 0 "RestingPeriodFlagShift_NoBreak3hMinAnd9hMaxWithinDrivingShift" ;
VAL_ 2566899694 RestingPeriodFlagShift3_ISig_3 1 "RestingPeriodFlagShift_Break3hMinAnd9hMaxWithinDrivingShift" 0 "RestingPeriodFlagShift_NoBreak3hMinAnd9hMaxWithinDrivingShift" ;
VAL_ 2566899694 UnknownPeriodShift7_ISig_3 1 "UnknownPeriodShift_UnknownTimeInDailyRestingPeriodShift" 0 "UnknownPeriodShift_NoUnknownTimeInDailyRestingPeriodShift" ;
VAL_ 2566899694 UnknownPeriodShift6_ISig_3 1 "UnknownPeriodShift_UnknownTimeInDailyRestingPeriodShift" 0 "UnknownPeriodShift_NoUnknownTimeInDailyRestingPeriodShift" ;
VAL_ 2566899694 UnknownPeriodShift3_ISig_3 1 "UnknownPeriodShift_UnknownTimeInDailyRestingPeriodShift" 0 "UnknownPeriodShift_NoUnknownTimeInDailyRestingPeriodShift" ;
VAL_ 2566899694 RestingPeriodFlagShift4_ISig_3 1 "RestingPeriodFlagShift_Break3hMinAnd9hMaxWithinDrivingShift" 0 "RestingPeriodFlagShift_NoBreak3hMinAnd9hMaxWithinDrivingShift" ;
VAL_ 2566899694 UnknownPeriodShift5_ISig_3 1 "UnknownPeriodShift_UnknownTimeInDailyRestingPeriodShift" 0 "UnknownPeriodShift_NoUnknownTimeInDailyRestingPeriodShift" ;
VAL_ 2566898926 Driver1CardUnload_Tacho 3 "Alert_NotAvailable" 2 "Alert_Error" 1 "Alert_Alert" 0 "Alert_NoAlert" ;
VAL_ 2566898926 EndofLifeDriver1Card_Tacho 3 "Alert_NotAvailable" 2 "Alert_Error" 1 "Alert_Alert" 0 "Alert_NoAlert" ;
VAL_ 2566898926 DrawerState_Tacho 3 "DrawerState_NotAvailable" 2 "DrawerState_Error" 1 "DrawerState_Close" 0 "DrawerState_Open" ;
VAL_ 2566759457 Pto2EnableSwitch 3 "OffOn_NotAvailable" 2 "OffOn_Error" 1 "OffOn_On" 0 "OffOn_Off" ;
VAL_ 2566759457 Pto1EnableSwitch 3 "OffOn_NotAvailable" 2 "OffOn_Error" 1 "OffOn_On" 0 "OffOn_Off" ;
VAL_ 2566759427 Pto2EngagementConsent 3 "PtoConsent_NotAvailable" 2 "PtoConsent_Error" 1 "PtoConsent_ConsentGivenPTODriveMayBeEngaged" 0 "PtoConsent_ConsentNotGivenPTODriveShouldNotBeEngaged" ;
VAL_ 2566759427 Pto1EngagementConsent 3 "PtoConsent_NotAvailable" 2 "PtoConsent_Error" 1 "PtoConsent_ConsentGivenPTODriveMayBeEngaged" 0 "PtoConsent_ConsentNotGivenPTODriveShouldNotBeEngaged" ;
VAL_ 2566799590 RearFogLights_ISig_3 3 "DeactivateActivate_NotAvailable" 2 "DeactivateActivate_Error" 1 "DeactivateActivate_Activate" 0 "DeactivateActivate_Deactivate" ;
VAL_ 2566799590 LowBeamHeadLightData_ISig_3 3 "DeactivateActivate_NotAvailable" 2 "DeactivateActivate_Error" 1 "DeactivateActivate_Activate" 0 "DeactivateActivate_Deactivate" ;
VAL_ 2566896663 OBDRelDTC_IC_EvalStatA 3 "DTCEvalStatA_NotAvailable" 2 "DTCEvalStatA_Error" 1 "DTCEvalStatA_Complete" 0 "DTCEvalStatA_Incomplete" ;
VAL_ 2566896663 OBDRelDTC_IC_EvalResultA 3 "DTCEvalResultA_NotAvailable" 2 "DTCEvalResultA_Error" 1 "DTCEvalResultA_Passed" 0 "DTCEvalResultA_Failed" ;
VAL_ 2566896663 OBDRelDTC_IC_EvalResultB 3 "DTCEvalResultB_NotAvailable" 2 "DTCEvalResultB_Error" 1 "DTCEvalResultB_Passed" 0 "DTCEvalResultB_Failed" ;
VAL_ 2566896663 OBDRelDTC_IC_EvalStatB 3 "DTCEvalStatB_NotAvailable" 2 "DTCEvalStatB_Error" 1 "DTCEvalStatB_Complete" 0 "DTCEvalStatB_Incomplete" ;
VAL_ 2566896663 OBDRelDTC_IC_DrvngCycleB 3 "DrivingCycleLSBB_NotAvailable" 2 "DrivingCycleLSBB_Error" 1 "DrivingCycleLSBB_Value1" 0 "DrivingCycleLSBB_Value0" ;
VAL_ 2566896663 OBDRelDTC_IC_DrvngCycleA 3 "DrivingCycleLSBA_NotAvailable" 2 "DrivingCycleLSBA_Error" 1 "DrivingCycleLSBA_Value1" 0 "DrivingCycleLSBA_Value0" ;
VAL_ 2566896407 AWBEnableRequest 3 "DisableEnable_NotAvailable" 2 "DisableEnable_Error" 1 "DisableEnable_Enable" 0 "DisableEnable_Disable" ;
VAL_ 2566896407 LoadCargoTare_rqst 15 "LoadCargoTare_rqst_NotAvailable" 14 "LoadCargoTare_rqst_Error" 13 "LoadCargoTare_rqst_Spare6" 12 "LoadCargoTare_rqst_Spare5" 11 "LoadCargoTare_rqst_Spare4" 10 "LoadCargoTare_rqst_Spare3" 9 "LoadCargoTare_rqst_Spare2" 8 "LoadCargoTare_rqst_Spare1" 7 "LoadCargoTare_rqst_Trailer5" 6 "LoadCargoTare_rqst_Trailer4" 5 "LoadCargoTare_rqst_Trailer3" 4 "LoadCargoTare_rqst_Trailer2" 3 "LoadCargoTare_rqst_Trailer1" 2 "LoadCargoTare_rqst_Truck" 1 "LoadCargoTare_rqst_VehicleCombination" 0 "LoadCargoTare_rqst_Inactive" ;
VAL_ 2566896407 DeleteLoadCalib 31 "DeleteLoadCalib_NotAvailable" 30 "DeleteLoadCalib_Spare10" 29 "DeleteLoadCalib_Spare9" 28 "DeleteLoadCalib_Spare8" 27 "DeleteLoadCalib_Spare7" 26 "DeleteLoadCalib_Truck" 25 "DeleteLoadCalib_TruckReAxle3" 24 "DeleteLoadCalib_TruckReAxle2" 23 "DeleteLoadCalib_TruckReAxle1" 22 "DeleteLoadCalib_TruckFrAxle2" 21 "DeleteLoadCalib_TruckFrAxle1" 20 "DeleteLoadCalib_Trailer20" 19 "DeleteLoadCalib_Trailer19" 18 "DeleteLoadCalib_Trailer18" 17 "DeleteLoadCalib_Trailer17" 16 "DeleteLoadCalib_Trailer16" 15 "DeleteLoadCalib_Trailer15" 14 "DeleteLoadCalib_Trailer14" 13 "DeleteLoadCalib_Trailer13" 12 "DeleteLoadCalib_Trailer12" 11 "DeleteLoadCalib_Trailer11" 10 "DeleteLoadCalib_Trailer10" 9 "DeleteLoadCalib_Trailer9" 8 "DeleteLoadCalib_Trailer8" 7 "DeleteLoadCalib_Trailer7" 6 "DeleteLoadCalib_Trailer6" 5 "DeleteLoadCalib_Trailer5" 4 "DeleteLoadCalib_Trailer4" 3 "DeleteLoadCalib_Trailer3" 2 "DeleteLoadCalib_Trailer2" 1 "DeleteLoadCalib_Trailer1" 0 "DeleteLoadCalib_NoRequest" ;
VAL_ 2566896407 CCtrlRemActTmpOpRqst_Act_ISig_3 7 "CabParkingClimateAct_NotAvailable" 6 "CabParkingClimateAct_Error" 5 "CabParkingClimateAct_spare3" 4 "CabParkingClimateAct_spare2" 3 "CabParkingClimateAct_spare1" 2 "CabParkingClimateAct_Deactivate" 1 "CabParkingClimateAct_Activate" 0 "CabParkingClimateAct_NoAction" ;
VAL_ 2566749463 FMS1_TellTaleStatus4_ISig_3 7 "TellTaleStatus_NotAvailable" 6 "TellTaleStatus_Reserved3" 5 "TellTaleStatus_Reserved2" 4 "TellTaleStatus_Reserved1" 3 "TellTaleStatus_Info" 2 "TellTaleStatus_Yellow" 1 "TellTaleStatus_Red" 0 "TellTaleStatus_Off" ;
VAL_ 2566749463 FMS1_TellTaleStatus10_ISig_3 7 "TellTaleStatus_NotAvailable" 6 "TellTaleStatus_Reserved3" 5 "TellTaleStatus_Reserved2" 4 "TellTaleStatus_Reserved1" 3 "TellTaleStatus_Info" 2 "TellTaleStatus_Yellow" 1 "TellTaleStatus_Red" 0 "TellTaleStatus_Off" ;
VAL_ 2566749463 FMS1_TellTaleStatus6_ISig_3 7 "TellTaleStatus_NotAvailable" 6 "TellTaleStatus_Reserved3" 5 "TellTaleStatus_Reserved2" 4 "TellTaleStatus_Reserved1" 3 "TellTaleStatus_Info" 2 "TellTaleStatus_Yellow" 1 "TellTaleStatus_Red" 0 "TellTaleStatus_Off" ;
VAL_ 2566749463 FMS1_TellTaleStatus8_ISig_3 7 "TellTaleStatus_NotAvailable" 6 "TellTaleStatus_Reserved3" 5 "TellTaleStatus_Reserved2" 4 "TellTaleStatus_Reserved1" 3 "TellTaleStatus_Info" 2 "TellTaleStatus_Yellow" 1 "TellTaleStatus_Red" 0 "TellTaleStatus_Off" ;
VAL_ 2566749463 FMS1_TellTaleStatus5_ISig_3 7 "TellTaleStatus_NotAvailable" 6 "TellTaleStatus_Reserved3" 5 "TellTaleStatus_Reserved2" 4 "TellTaleStatus_Reserved1" 3 "TellTaleStatus_Info" 2 "TellTaleStatus_Yellow" 1 "TellTaleStatus_Red" 0 "TellTaleStatus_Off" ;
VAL_ 2566749463 FMS1_TellTaleStatus12_ISig_3 7 "TellTaleStatus_NotAvailable" 6 "TellTaleStatus_Reserved3" 5 "TellTaleStatus_Reserved2" 4 "TellTaleStatus_Reserved1" 3 "TellTaleStatus_Info" 2 "TellTaleStatus_Yellow" 1 "TellTaleStatus_Red" 0 "TellTaleStatus_Off" ;
VAL_ 2566749463 FMS1_TellTaleStatus14_ISig_3 7 "TellTaleStatus_NotAvailable" 6 "TellTaleStatus_Reserved3" 5 "TellTaleStatus_Reserved2" 4 "TellTaleStatus_Reserved1" 3 "TellTaleStatus_Info" 2 "TellTaleStatus_Yellow" 1 "TellTaleStatus_Red" 0 "TellTaleStatus_Off" ;
VAL_ 2566749463 FMS1_TellTaleStatus1_ISig_3 7 "TellTaleStatus_NotAvailable" 6 "TellTaleStatus_Reserved3" 5 "TellTaleStatus_Reserved2" 4 "TellTaleStatus_Reserved1" 3 "TellTaleStatus_Info" 2 "TellTaleStatus_Yellow" 1 "TellTaleStatus_Red" 0 "TellTaleStatus_Off" ;
VAL_ 2566749463 FMS1_TellTaleStatus2_ISig_3 7 "TellTaleStatus_NotAvailable" 6 "TellTaleStatus_Reserved3" 5 "TellTaleStatus_Reserved2" 4 "TellTaleStatus_Reserved1" 3 "TellTaleStatus_Info" 2 "TellTaleStatus_Yellow" 1 "TellTaleStatus_Red" 0 "TellTaleStatus_Off" ;
VAL_ 2566749463 FMS1_TellTaleStatus11_ISig_3 7 "TellTaleStatus_NotAvailable" 6 "TellTaleStatus_Reserved3" 5 "TellTaleStatus_Reserved2" 4 "TellTaleStatus_Reserved1" 3 "TellTaleStatus_Info" 2 "TellTaleStatus_Yellow" 1 "TellTaleStatus_Red" 0 "TellTaleStatus_Off" ;
VAL_ 2566749463 FMS1_TellTaleStatus15_ISig_3 7 "TellTaleStatus_NotAvailable" 6 "TellTaleStatus_Reserved3" 5 "TellTaleStatus_Reserved2" 4 "TellTaleStatus_Reserved1" 3 "TellTaleStatus_Info" 2 "TellTaleStatus_Yellow" 1 "TellTaleStatus_Red" 0 "TellTaleStatus_Off" ;
VAL_ 2566749463 FMS1_TellTaleStatus3_ISig_3 7 "TellTaleStatus_NotAvailable" 6 "TellTaleStatus_Reserved3" 5 "TellTaleStatus_Reserved2" 4 "TellTaleStatus_Reserved1" 3 "TellTaleStatus_Info" 2 "TellTaleStatus_Yellow" 1 "TellTaleStatus_Red" 0 "TellTaleStatus_Off" ;
VAL_ 2566749463 FMS1_TellTaleStatus13_ISig_3 7 "TellTaleStatus_NotAvailable" 6 "TellTaleStatus_Reserved3" 5 "TellTaleStatus_Reserved2" 4 "TellTaleStatus_Reserved1" 3 "TellTaleStatus_Info" 2 "TellTaleStatus_Yellow" 1 "TellTaleStatus_Red" 0 "TellTaleStatus_Off" ;
VAL_ 2566749463 FMS1_TellTaleStatus9_ISig_3 7 "TellTaleStatus_NotAvailable" 6 "TellTaleStatus_Reserved3" 5 "TellTaleStatus_Reserved2" 4 "TellTaleStatus_Reserved1" 3 "TellTaleStatus_Info" 2 "TellTaleStatus_Yellow" 1 "TellTaleStatus_Red" 0 "TellTaleStatus_Off" ;
VAL_ 2566749463 FMS1_TellTaleStatus7_ISig_3 7 "TellTaleStatus_NotAvailable" 6 "TellTaleStatus_Reserved3" 5 "TellTaleStatus_Reserved2" 4 "TellTaleStatus_Reserved1" 3 "TellTaleStatus_Info" 2 "TellTaleStatus_Yellow" 1 "TellTaleStatus_Red" 0 "TellTaleStatus_Off" ;
VAL_ 2566801923 TransmEngineCrankEnable2_ISig_3 3 "DisableEnable_NotAvailable" 2 "DisableEnable_Error" 1 "DisableEnable_Enable" 0 "DisableEnable_Disable" ;
VAL_ 2364539395 TransmTrqConvrtrLockupEngd_ISig_ 3 "DisengageEngage_NotAvailable" 2 "DisengageEngage_Error" 1 "DisengageEngage_Engage" 0 "DisengageEngage_Disengage" ;
VAL_ 2364539395 TransmissionDrivelineEngaged_ISi 3 "DisengageEngage_NotAvailable" 2 "DisengageEngage_Error" 1 "DisengageEngage_Engage" 0 "DisengageEngage_Disengage" ;
VAL_ 2364539395 MomentaryEngineOverspeedEnable_I 3 "DisableEnable_NotAvailable" 2 "DisableEnable_Error" 1 "DisableEnable_Enable" 0 "DisableEnable_Disable" ;
VAL_ 2364539395 TransmissionShiftInProcess_ISig_ 3 "TransmissionShiftInProcess_NotAvailable" 2 "TransmissionShiftInProcess_Error" 1 "TransmissionShiftInProcess_ShiftInProcess" 0 "TransmissionShiftInProcess_ShiftNotInProcess" ;
VAL_ 2565865488 EngineCoolantLoadIncrease 3 "EngineCoolantLoadIncrease_NotAvailable" 2 "EngineCoolantLoadIncrease_Error" 1 "EngineCoolantLoadIncrease_CoolantLoadIncreasePossible" 0 "EngineCoolantLoadIncrease_NoCoolantLoadIncrease" ;
VAL_ 2565865488 RetarderTorqueMode_ISig_3 15 "RetarderTorqueMode_NotAvailable" 14 "RetarderTorqueMode_Other" 13 "RetarderTorqueMode_NotDefined" 12 "RetarderTorqueMode_ServiceProcedure" 11 "RetarderTorqueMode_RemoteAccelerator" 10 "RetarderTorqueMode_BrakingSystem" 9 "RetarderTorqueMode_HighSpeedGovernor" 8 "RetarderTorqueMode_TorqueLimiting" 7 "RetarderTorqueMode_ABSControl" 6 "RetarderTorqueMode_TransmissionControl" 5 "RetarderTorqueMode_ASRControl" 4 "RetarderTorqueMode_RoadSpeedGovernor" 3 "RetarderTorqueMode_PTOGovernor" 2 "RetarderTorqueMode_CruiseControl" 1 "RetarderTorqueMode_AcceleratorPedalOperatorSelection" 0 "RetarderTorqueMode_LowIdleGovernorNoRequestDefaultMode" ;
VAL_ 2565865487 RetarderEnableShiftAssistSw 3 "DisableEnable_NotAvailable" 2 "DisableEnable_Error" 1 "DisableEnable_Enable" 0 "DisableEnable_Disable" ;
VAL_ 2565865487 EngineRetarderTorqueMode_ISig_3 15 "EngineRetarderTorqueMode_NotAvailable" 14 "EngineRetarderTorqueMode_Other" 13 "EngineRetarderTorqueMode_NotDefined" 12 "EngineRetarderTorqueMode_ServiceProcedure" 11 "EngineRetarderTorqueMode_RemoteAccelerator" 10 "EngineRetarderTorqueMode_BrakingSystem" 9 "EngineRetarderTorqueMode_HighSpeedGovernor" 8 "EngineRetarderTorqueMode_TorqueLimiting" 7 "EngineRetarderTorqueMode_ABSControl" 6 "EngineRetarderTorqueMode_TransmissionControl" 5 "EngineRetarderTorqueMode_ASRControl" 4 "EngineRetarderTorqueMode_RoadSpeedGovernor" 3 "EngineRetarderTorqueMode_PTOGovernor" 2 "EngineRetarderTorqueMode_CruiseControl" 1 "EngineRetarderTorqueMode_AcceleratorPedalOperatorSelection" 0 "EngineRetarderTorqueMode_LowIdleGovernorNoRequestDefaultMode" ;
VAL_ 2565865487 EngRetdrEnableBrakeAssistSw 3 "DisableEnable_NotAvailable" 2 "DisableEnable_Error" 1 "DisableEnable_Enable" 0 "DisableEnable_Disable" ;
VAL_ 2364539648 RoadSpeedLimitStatus 3 "ActiveNotActive_NotAvailable" 2 "ActiveNotActive_Error" 1 "ActiveNotActive_NotActive" 0 "ActiveNotActive_Active" ;
VAL_ 2364539904 EngineTorqueMode_ISig_3 15 "EngineTorqueMode_NotAvailable" 14 "EngineTorqueMode_Other" 13 "EngineTorqueMode_AirManagement" 12 "EngineTorqueMode_ServiceProcedure" 11 "EngineTorqueMode_RemoteAccelerator" 10 "EngineTorqueMode_BrakingSystem" 9 "EngineTorqueMode_HighSpeedGovernor" 8 "EngineTorqueMode_TorqueLimiting" 7 "EngineTorqueMode_ABSControl" 6 "EngineTorqueMode_TransmissionControl" 5 "EngineTorqueMode_ASRControl" 4 "EngineTorqueMode_RoadSpeedGovernor" 3 "EngineTorqueMode_PTOGovernor" 2 "EngineTorqueMode_CruiseControl" 1 "EngineTorqueMode_AcceleratorPedalOperatorSelection" 0 "EngineTorqueMode_LowIdleGovernorNoRequestDefaultMode" ;
VAL_ 2364539904 EngineStarterMode_ISig_3 15 "EngineStarterMode_NotAvailable" 14 "EngineStarterMode_Error" 13 "EngineStarterMode_NotToBeUsed" 12 "EngineStarterMode_StarterInhibitedReasonUnknown" 11 "EngineStarterMode_Reserved_02" 10 "EngineStarterMode_Reserved_01" 9 "EngineStarterMode_Reserved" 8 "EngineStarterMode_StarterInhibitedDueToStarterOverTemp" 7 "EngineStarterMode_StarterInhibitedDueToActiveImmobilizer" 6 "EngineStarterMode_StarterInhibitedDueToDrivelineEngagedOrOther" 5 "EngineStarterMode_StarterInhibitedDueToEngineNotReadyForStart" 4 "EngineStarterMode_StarterInhibitedDueToEngineAlreadyRunning" 3 "EngineStarterMode_StartFinishedStarterNotActiveAfterHavingBe" 2 "EngineStarterMode_StarterActiveGearEngaged" 1 "EngineStarterMode_StarterActiveGearNotEngaged" 0 "EngineStarterMode_StartNotRequested" ;
VAL_ 2566911243 Trailer5PneumSupply_Status_ISig_ 3 "InsufficientSufficient_NotAvailable" 2 "InsufficientSufficient_Error" 1 "InsufficientSufficient_Sufficient" 0 "InsufficientSufficient_Insufficient" ;
VAL_ 2566911243 Trailer5VehicleType_ISig_3 3 "TrailerVehicleType_NotAvailable" 2 "TrailerVehicleType_Error" 1 "TrailerVehicleType_ConverterDollyAxle" 0 "TrailerVehicleType_TowingOrTowedVehicle" ;
VAL_ 2566911243 Trailer5ElectricalSupplyStat_ISi 3 "InsufficientSufficient_NotAvailable" 2 "InsufficientSufficient_Error" 1 "InsufficientSufficient_Sufficient" 0 "InsufficientSufficient_Insufficient" ;
VAL_ 2566911243 Trailer5ROPSystemStatus_ISig_3 3 "DisableEnable_NotAvailable" 2 "DisableEnable_Error" 1 "DisableEnable_Enable" 0 "DisableEnable_Disable" ;
VAL_ 2566911243 Trailer5EBSRedWarning_ISig_3 3 "OffOn_NotAvailable" 2 "OffOn_Error" 1 "OffOn_On" 0 "OffOn_Off" ;
VAL_ 2566911243 Trailer5LoadRampApprAssistStat_I 3 "ActiveStatus_NotAvailable" 2 "ActiveStatus_Error" 1 "ActiveStatus_Active" 0 "ActiveStatus_NotActive" ;
VAL_ 2566911243 Trailer5LevelControlStatus_ISig_ 3 "DisableEnable_NotAvailable" 2 "DisableEnable_Error" 1 "DisableEnable_Enable" 0 "DisableEnable_Disable" ;
VAL_ 2566911243 Trailer5ExtLvlStorageSupport_ISi 3 "TrailerExtLvlStorageSupport_NotSupported" 2 "TrailerExtLvlStorageSupport_Error" 1 "TrailerExtLvlStorageSupport_SupportedIn2ExtendedSets" 0 "TrailerExtLvlStorageSupport_SupportedInAll3Sets" ;
VAL_ 2566911243 Trailer5YCSystemStatus_ISig_3 3 "DisableEnable_NotAvailable" 2 "DisableEnable_Error" 1 "DisableEnable_Enable" 0 "DisableEnable_Disable" ;
VAL_ 2566911243 Trailer5EBSAmberWarning_ISig_3 3 "WarningIndicator_NotAvailable" 2 "WarningIndicator_Flashing" 1 "WarningIndicator_OnContinuously" 0 "WarningIndicator_Off" ;
SIG_GROUP_ 2566896663 OBDRelDTC_IC_sg 1 : OBDRelDTC_IC_DtcIdA OBDRelDTC_IC_DtcIdB OBDRelDTC_IC_EvalStatA OBDRelDTC_IC_EvalResultA OBDRelDTC_IC_EvalResultB OBDRelDTC_IC_EvalStatB OBDRelDTC_IC_FailTB OBDRelDTC_IC_DrvngCycleB OBDRelDTC_IC_DrvngCycleA OBDRelDTC_IC_FailTA;
SIG_GROUP_ 2566896407 CCtrlRemActTmpOpRqst_sg_ISig_3 1 : CCtrlRemActTmpOpRqst_Temp_ISig_3 CCtrlRemActTmpOpRqst_Act_ISig_3;
SIG_GROUP_ 2566892452 OBDGWLogHeartBeat_sg_ISig_3 1 : OBDGWLogHeartBeat_MsgCounter_ISi OBDGWLogHeartBeat_Data1_ISig_3 OBDGWLogHeartBeat_Data0_ISig_3 OBDGWLogHeartBeat_Data4_ISig_3 OBDGWLogHeartBeat_Data2_ISig_3 OBDGWLogHeartBeat_Data5_ISig_3 OBDGWLogHeartBeat_Data3_ISig_3 OBDGWLogHeartBeat_MsgChecksum_IS OBDGWLogHeartBeat_Data6_ISig_3;
SIG_GROUP_ 2566749463 FMS1_sg_ISig_3 1 : FMS1_TellTaleStatus4_ISig_3 FMS1_TellTaleStatus10_ISig_3 FMS1_TellTaleStatus6_ISig_3 FMS1_TellTaleStatus8_ISig_3 FMS1_TellTaleStatus5_ISig_3 FMS1_TellTaleStatus12_ISig_3 FMS1_Blockid_ISig_3 FMS1_TellTaleStatus14_ISig_3 FMS1_TellTaleStatus1_ISig_3 FMS1_TellTaleStatus2_ISig_3 FMS1_TellTaleStatus11_ISig_3 FMS1_TellTaleStatus15_ISig_3 FMS1_TellTaleStatus3_ISig_3 FMS1_TellTaleStatus13_ISig_3 FMS1_TellTaleStatus9_ISig_3 FMS1_TellTaleStatus7_ISig_3;
SIG_GROUP_ 2566911243 Trailer5NomBodyLevel_sg_ISig_3 1 : Trailer5NomBodyLevel_RearLevel_I Trailer5NomBodyLevel_FrontLevel_;
SIG_GROUP_ 2566911243 Trailer5PneumSupply_sg_ISig_3 1 : Trailer5PneumSupply_Status_ISig_ Trailer5PneumSupply_Pressure_ISi;
